VERSION "HNNBNNNYNNNNNNNNNNNNNNNNNNNNNNNNNNNNNNNNNN/4/%%%/4/'%**4NNN///"

NS_ :

BS_:

BU_: BAP_Tester BCM Gateway_Max TSGGen3_BFS TSGGen3_FS TSGGen3_HBFS TSGGen3_HFS WLC_01_CFD

BO_ 885 ESC_54: 32 Gateway_Max
 SG_ ESC_54_BZ : 8|4@1+ (1,0) [0|15] ""  BCM
 SG_ SSO_EdgeCount_Sum : 16|32@1+ (1,0) [0|4294967293] "Unit_None"  BCM
 SG_ SOK_ESC_54_Signatur : 208|48@1+ (1,0) [0|281474976710655] "Unit_None"  BCM

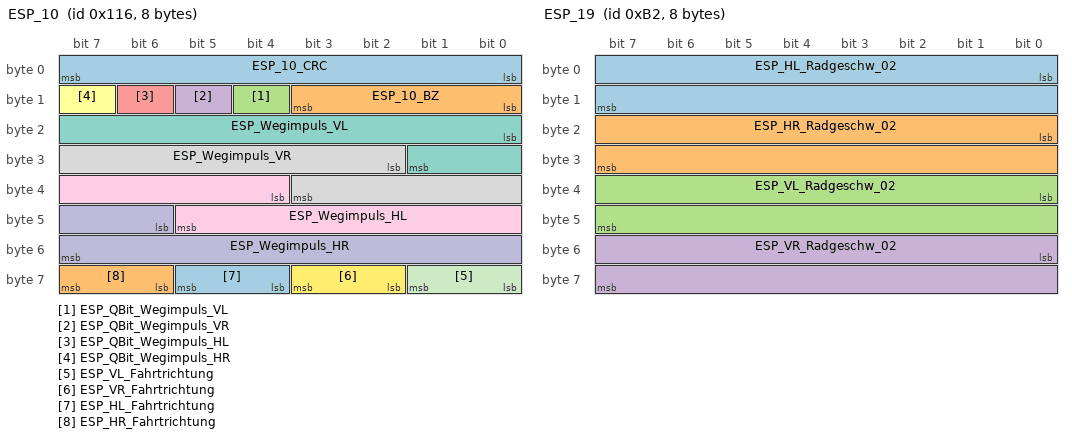
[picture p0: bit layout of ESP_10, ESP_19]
BO_ 278 ESP_10: 8 Gateway_Max
 SG_ ESP_10_CRC : 0|8@1+ (1,0) [0|255] ""  Vector__XXX
 SG_ ESP_10_BZ : 8|4@1+ (1,0) [0|15] ""  Vector__XXX
 SG_ ESP_QBit_Wegimpuls_VL : 12|1@1+ (1.0,0.0) [0.0|1] ""  Vector__XXX
 SG_ ESP_QBit_Wegimpuls_VR : 13|1@1+ (1.0,0.0) [0.0|1] ""  Vector__XXX
 SG_ ESP_QBit_Wegimpuls_HL : 14|1@1+ (1.0,0.0) [0.0|1] ""  Vector__XXX
 SG_ ESP_QBit_Wegimpuls_HR : 15|1@1+ (1.0,0.0) [0.0|1] ""  Vector__XXX
 SG_ ESP_Wegimpuls_VL : 16|10@1+ (1,0) [0|1000] ""  Vector__XXX
 SG_ ESP_Wegimpuls_VR : 26|10@1+ (1,0) [0|1000] ""  Vector__XXX
 SG_ ESP_Wegimpuls_HL : 36|10@1+ (1,0) [0|1000] ""  Vector__XXX
 SG_ ESP_Wegimpuls_HR : 46|10@1+ (1,0) [0|1000] ""  Vector__XXX
 SG_ ESP_VL_Fahrtrichtung : 56|2@1+ (1.0,0.0) [0.0|3] ""  BCM
 SG_ ESP_VR_Fahrtrichtung : 58|2@1+ (1.0,0.0) [0.0|3] ""  BCM
 SG_ ESP_HL_Fahrtrichtung : 60|2@1+ (1.0,0.0) [0.0|3] ""  BCM
 SG_ ESP_HR_Fahrtrichtung : 62|2@1+ (1.0,0.0) [0.0|3] ""  BCM

BO_ 178 ESP_19: 8 Gateway_Max
 SG_ ESP_HL_Radgeschw_02 : 0|16@1+ (0.0075,0) [0.0000|491.4900] "Unit_KiloMeterPerHour"  BCM
 SG_ ESP_HR_Radgeschw_02 : 16|16@1+ (0.0075,0) [0.0000|491.4900] "Unit_KiloMeterPerHour"  BCM
 SG_ ESP_VL_Radgeschw_02 : 32|16@1+ (0.0075,0) [0.0000|491.4900] "Unit_KiloMeterPerHour"  BCM
 SG_ ESP_VR_Radgeschw_02 : 48|16@1+ (0.0075,0) [0.0000|491.4900] "Unit_KiloMeterPerHour"  BCM

BO_ 1629 ESP_20: 8 Gateway_Max
 SG_ ESP_20_CRC : 0|8@1+ (1,0) [0|255] ""  Vector__XXX
 SG_ ESP_20_BZ : 8|4@1+ (1,0) [0|15] ""  Vector__XXX
 SG_ BR_Systemart : 12|2@1+ (1.0,0.0) [0.0|3] ""  BCM
 SG_ ESP_SpannungsAnf_02 : 14|2@1+ (1.0,0.0) [0.0|3] ""  Vector__XXX
 SG_ ESP_Zaehnezahl : 16|8@1+ (1,0) [0|255] ""  BCM
 SG_ ESP_Charisma_FahrPr : 24|4@1+ (1.0,0.0) [0.0|15] ""  Vector__XXX
 SG_ ESP_Charisma_Status : 28|2@1+ (1.0,0.0) [0.0|3] ""  Vector__XXX
 SG_ ESP_Wiederstart_Anz_01 : 30|1@1+ (1.0,0.0) [0.0|1] ""  Vector__XXX
 SG_ ESP_Wiederstart_Anz_02 : 31|1@1+ (1.0,0.0) [0.0|1] ""  Vector__XXX
 SG_ ESP_Wiederstart_Anz_03 : 32|1@1+ (1.0,0.0) [0.0|1] ""  Vector__XXX
 SG_ ESP_Wiederstart_Anz_04 : 33|1@1+ (1.0,0.0) [0.0|1] ""  Vector__XXX
 SG_ ESP_Stoppverbot_Anz_01 : 34|1@1+ (1.0,0.0) [0.0|1] ""  Vector__XXX
 SG_ ESP_Stoppverbot_Anz_02 : 35|1@1+ (1.0,0.0) [0.0|1] ""  Vector__XXX
 SG_ ESP_Stoppverbot_Anz_03 : 36|1@1+ (1.0,0.0) [0.0|1] ""  Vector__XXX
 SG_ ESP_Stoppverbot_Anz_04 : 37|1@1+ (1.0,0.0) [0.0|1] ""  Vector__XXX
 SG_ ESP_Stoppverbot_Anz_05 : 38|1@1+ (1.0,0.0) [0.0|1] ""  Vector__XXX
 SG_ ESP_Stoppverbot_Anz_06 : 39|1@1+ (1.0,0.0) [0.0|1] ""  Vector__XXX
 SG_ ESP_Stoppverbot_Anz_07 : 40|1@1+ (1.0,0.0) [0.0|1] ""  Vector__XXX
 SG_ ESP_Stoppverbot_Anz_Std : 41|1@1+ (1.0,0.0) [0.0|1] ""  Vector__XXX
 SG_ ESP_Dachrelingsensor : 42|2@1+ (1.0,0.0) [0.0|3] ""  Vector__XXX
 SG_ ESP_Stoppverbot_Anz_08 : 44|1@1+ (1.0,0.0) [0.0|1] ""  Vector__XXX
 SG_ HDC_Charisma_FahrPr : 45|4@1+ (1.0,0.0) [0.0|15] ""  Vector__XXX
 SG_ HDC_Charisma_Status : 49|2@1+ (1.0,0.0) [0.0|3] ""  Vector__XXX
 SG_ BR_QBit_Reifenumfang : 51|1@1+ (1.0,0.0) [0.0|1] ""  Vector__XXX
 SG_ BR_Reifenumfang : 52|12@1+ (1,0) [0|4095] "Unit_MilliMeter"  Vector__XXX

BO_ 253 ESP_21: 8 Gateway_Max
 SG_ ESP_21_CRC : 0|8@1+ (1,0) [0|255] ""  BCM,TSGGen3_BFS,TSGGen3_FS,TSGGen3_HBFS,TSGGen3_HFS
 SG_ ESP_21_BZ : 8|4@1+ (1,0) [0|15] ""  BCM,TSGGen3_BFS,TSGGen3_FS,TSGGen3_HBFS,TSGGen3_HFS
 SG_ BR_Eingriffsmoment : 12|10@1+ (1,-509) [-509|509] ""  BCM
 SG_ ESP_PLA_Bremseingriff : 22|1@1+ (1.0,0.0) [0.0|1] ""  BCM
 SG_ ESP_Diagnose : 23|1@1+ (1.0,0.0) [0.0|1] ""  BCM
 SG_ ESC_Reku_Freigabe : 24|1@1+ (1.0,0.0) [0.0|1] ""  BCM
 SG_ ESC_v_Signal_Qualifier_High_Low : 25|3@1+ (1.0,0.0) [0.0|7] ""  BCM
 SG_ ESP_Vorsteuerung : 28|1@1+ (1.0,0.0) [0.0|1] ""  BCM
 SG_ ESP_AWV3_Brems_aktiv : 29|1@1+ (1.0,0.0) [0.0|1] ""  BCM
 SG_ OBD_Schlechtweg : 30|1@1+ (1.0,0.0) [0.0|1] ""  BCM
 SG_ OBD_QBit_Schlechtweg : 31|1@1+ (1.0,0.0) [0.0|1] ""  BCM
 SG_ ESP_v_Signal : 32|16@1+ (0.01,0) [0.00|655.32] "Unit_KiloMeterPerHour"  BCM,TSGGen3_BFS,TSGGen3_FS,TSGGen3_HBFS,TSGGen3_HFS,WLC_01_CFD
 SG_ ASR_Tastung_passiv : 48|1@1+ (1.0,0.0) [0.0|1] ""  BCM
 SG_ ESP_Tastung_passiv : 49|1@1+ (1.0,0.0) [0.0|1] ""  BCM
 SG_ ESP_Systemstatus : 50|1@1+ (1.0,0.0) [0.0|1] ""  BCM
 SG_ ASR_Schalteingriff : 51|2@1+ (1.0,0.0) [0.0|3] ""  BCM
 SG_ ESP_Haltebestaetigung : 53|1@1+ (1.0,0.0) [0.0|1] ""  BCM
 SG_ ESP_MKB_Abbruch_Geschw : 54|1@1+ (1.0,0.0) [0.0|1] ""  BCM
 SG_ ESP_QBit_v_Signal : 55|1@1+ (1.0,0.0) [0.0|1] ""  BCM,TSGGen3_BFS,TSGGen3_FS,TSGGen3_HBFS,TSGGen3_HFS,WLC_01_CFD
 SG_ ABS_Bremsung : 56|1@1+ (1.0,0.0) [0.0|1] ""  BCM
 SG_ ASR_Anf : 57|1@1+ (1.0,0.0) [0.0|1] ""  BCM
 SG_ MSR_Anf : 58|1@1+ (1.0,0.0) [0.0|1] ""  BCM
 SG_ EBV_Eingriff : 59|1@1+ (1.0,0.0) [0.0|1] ""  BCM
 SG_ EDS_Eingriff : 60|1@1+ (1.0,0.0) [0.0|1] ""  BCM
 SG_ ESP_Eingriff : 61|1@1+ (1.0,0.0) [0.0|1] ""  BCM
 SG_ ESP_ASP : 62|1@1+ (1.0,0.0) [0.0|1] ""  BCM
 SG_ ESP_Anhaltevorgang_ACC_aktiv : 63|1@1+ (1.0,0.0) [0.0|1] ""  BCM

BO_ 795 ESP_24: 8 Gateway_Max
 SG_ ESP_24_CRC : 0|8@1+ (1,0) [0|255] ""  Vector__XXX
 SG_ ESP_24_BZ : 8|4@1+ (1,0) [0|15] ""  Vector__XXX
 SG_ ESP_Lampe : 12|1@1+ (1.0,0.0) [0.0|1] ""  Vector__XXX
 SG_ ABS_Lampe : 13|1@1+ (1.0,0.0) [0.0|1] ""  Vector__XXX
 SG_ BK_Lampe_02 : 14|2@1+ (1.0,0.0) [0.0|3] ""  Vector__XXX
 SG_ TC_Lampe : 16|1@1+ (1.0,0.0) [0.0|1] ""  Vector__XXX
 SG_ ESP_m_Raddrehz : 17|15@1+ (0.002,0) [0.000|65.278] "Unit_Hertz"  BCM
 SG_ ESP_Textanzeigen_03 : 32|5@1+ (1.0,0.0) [0.0|31] ""  Vector__XXX
 SG_ ESP_Meldungen : 37|3@1+ (1.0,0.0) [0.0|7] ""  Vector__XXX
 SG_ ESP_Wegimp_VA : 40|11@1+ (1,0) [0|2047] ""  BCM
 SG_ ESP_Fehlerstatus_Wegimp : 51|1@1+ (1.0,0.0) [0.0|1] ""  Vector__XXX
 SG_ ESP_Wegimp_Ueberlauf : 52|1@1+ (1.0,0.0) [0.0|1] ""  BCM
 SG_ ESP_QBit_Wegimp_VA : 53|1@1+ (1.0,0.0) [0.0|1] ""  Vector__XXX
 SG_ ESP_HDC_FktLampe : 54|1@1+ (1.0,0.0) [0.0|1] ""  Vector__XXX
 SG_ ESP_Off_Lampe : 55|1@1+ (1.0,0.0) [0.0|1] ""  Vector__XXX
 SG_ ESP_HDC_Regelgeschw : 56|7@1+ (0.32,0) [0.32|39.68] "Unit_KiloMeterPerHour"  Vector__XXX
 SG_ ESP_BKV_Warnung : 63|1@1+ (1.0,0.0) [0.0|1] ""  Vector__XXX

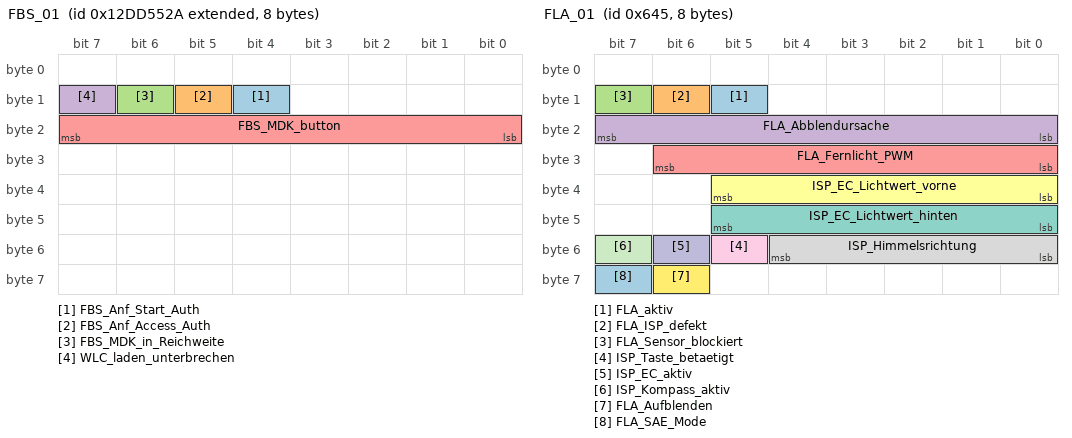
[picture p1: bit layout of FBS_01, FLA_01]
BO_ 2463978794 FBS_01: 8 BCM
 SG_ FBS_Anf_Start_Auth : 12|1@1+ (1.0,0.0) [0.0|1] ""  Gateway_Max,WLC_01_CFD
 SG_ FBS_Anf_Access_Auth : 13|1@1+ (1.0,0.0) [0.0|1] ""  Gateway_Max
 SG_ FBS_MDK_in_Reichweite : 14|1@1+ (1.0,0.0) [0.0|1] ""  Gateway_Max
 SG_ WLC_laden_unterbrechen : 15|1@1+ (1.0,0.0) [0.0|1] ""  Gateway_Max,WLC_01_CFD
 SG_ FBS_MDK_button : 16|8@1+ (1.0,0.0) [0.0|255] ""  Gateway_Max

BO_ 2527679800 FBS_MKGO_01: 64 BCM
 SG_ FBS_MKGO_01 : 0|512@1+ (1.0,0.0) [0.0|13407807929942597099574024998205846127479365820592393377723561443721764030073546976801874298166903427690031858186486050853753882811946569946433649006084095] ""  WLC_01_CFD

BO_ 2527679801 FBS_MKGO_02: 64 BCM
 SG_ FBS_MKGO_02 : 0|512@1+ (1.0,0.0) [0.0|13407807929942597099574024998205846127479365820592393377723561443721764030073546976801874298166903427690031858186486050853753882811946569946433649006084095] ""  WLC_01_CFD

BO_ 2527679802 FBS_MKGO_03: 64 BCM
 SG_ FBS_MKGO_03 : 0|512@1+ (1.0,0.0) [0.0|13407807929942597099574024998205846127479365820592393377723561443721764030073546976801874298166903427690031858186486050853753882811946569946433649006084095] ""  WLC_01_CFD

BO_ 2527679803 FBS_MKGO_04: 64 BCM
 SG_ FBS_MKGO_04 : 0|512@1+ (1.0,0.0) [0.0|13407807929942597099574024998205846127479365820592393377723561443721764030073546976801874298166903427690031858186486050853753882811946569946433649006084095] ""  WLC_01_CFD

BO_ 2527679804 FBS_MKGO_05: 64 BCM
 SG_ FBS_MKGO_05 : 0|512@1+ (1.0,0.0) [0.0|13407807929942597099574024998205846127479365820592393377723561443721764030073546976801874298166903427690031858186486050853753882811946569946433649006084095] ""  WLC_01_CFD

BO_ 1605 FLA_01: 8 Gateway_Max
 SG_ FLA_aktiv : 13|1@1+ (1.0,0.0) [0.0|1] ""  BCM
 SG_ FLA_ISP_defekt : 14|1@1+ (1.0,0.0) [0.0|1] ""  BCM
 SG_ FLA_Sensor_blockiert : 15|1@1+ (1.0,0.0) [0.0|1] ""  BCM
 SG_ FLA_Abblendursache : 16|8@1+ (1.0,0.0) [0.0|255] ""  Vector__XXX
 SG_ FLA_Fernlicht_PWM : 24|7@1+ (1,0) [0|100] "Unit_PerCent"  BCM
 SG_ ISP_EC_Lichtwert_vorne : 32|6@1+ (1,0) [0|61] "Unit_None"  Vector__XXX
 SG_ ISP_EC_Lichtwert_hinten : 40|6@1+ (1,0) [0|61] "Unit_None"  Vector__XXX
 SG_ ISP_Himmelsrichtung : 48|5@1+ (12,0) [0|348] "Unit_DegreOfArc"  Vector__XXX
 SG_ ISP_Taste_betaetigt : 53|1@1+ (1.0,0.0) [0.0|1] ""  Vector__XXX
 SG_ ISP_EC_aktiv : 54|1@1+ (1.0,0.0) [0.0|1] ""  Vector__XXX
 SG_ ISP_Kompass_aktiv : 55|1@1+ (1.0,0.0) [0.0|1] ""  Vector__XXX
 SG_ FLA_Aufblenden : 62|1@1+ (1.0,0.0) [0.0|1] ""  BCM
 SG_ FLA_SAE_Mode : 63|1@1+ (1.0,0.0) [0.0|1] ""  BCM

BO_ 2589283684 FoD_01: 8 Gateway_Max
 SG_ GRA_FoD_Status : 58|2@1+ (1.0,0.0) [0.0|3] ""  Vector__XXX
 SG_ FoD_Transmission_Info : 60|2@1+ (1.0,0.0) [0.0|3] ""  Vector__XXX

BO_ 2549875470 FoD_BCM1_Req: 8 Gateway_Max
 SG_ FoD_BCM1_Req_Data : 0|64@1+ (1.0,0.0) [0.0|18446744073709551615] ""  BCM

BO_ 2550006542 FoD_BCM1_Resp: 8 BCM
 SG_ FoD_BCM1_Resp_Data : 0|64@1+ (1.0,0.0) [0.0|18446744073709551615] ""  Gateway_Max

BO_ 986 Gateway_71: 8 Gateway_Max
 SG_ ESP_05_alt : 0|1@1+ (1.0,0.0) [0.0|1] ""  BCM
 SG_ EPB_01_alt : 1|1@1+ (1.0,0.0) [0.0|1] ""  BCM
 SG_ ESP_21_alt : 2|1@1+ (1.0,0.0) [0.0|1] ""  BCM
 SG_ LWI_01_alt : 3|1@1+ (1.0,0.0) [0.0|1] ""  BCM
 SG_ Parkhilfe_01_alt : 4|1@1+ (1.0,0.0) [0.0|1] ""  BCM
 SG_ Kamera_Status_alt : 5|1@1+ (1.0,0.0) [0.0|1] ""  BCM
 SG_ ESP_HDC_Standby : 6|1@1+ (1.0,0.0) [0.0|1] ""  BCM
 SG_ ECD_Bremslicht : 8|1@1+ (1.0,0.0) [0.0|1] ""  BCM
 SG_ EPB_Status : 9|2@1+ (1.0,0.0) [0.0|3] ""  BCM
 SG_ EPB_QBit_Pedalweg_Kuppl : 11|1@1+ (1.0,0.0) [0.0|1] ""  BCM
 SG_ ESP_QBit_v_Signal : 12|1@1+ (1.0,0.0) [0.0|1] ""  BCM
 SG_ ABS_Bremsung : 13|1@1+ (1.0,0.0) [0.0|1] ""  BCM
 SG_ ESP_Eingriff : 14|1@1+ (1.0,0.0) [0.0|1] ""  BCM
 SG_ Kamera_FSH_aktiv : 15|1@1+ (1.0,0.0) [0.0|1] ""  BCM
 SG_ EPB_Pedalweg_Kuppl : 16|8@1+ (0.4,0) [8.0|92.0] "Unit_PerCent"  BCM
 SG_ ESP_v_Signal : 24|16@1+ (0.01,0) [0.00|655.32] "Unit_KiloMeterPerHour"  BCM
 SG_ LWI_QBit_Lenkradwinkel : 40|1@1+ (1.0,0.0) [0.0|1] ""  BCM
 SG_ LWI_Sensorstatus : 41|1@1+ (1.0,0.0) [0.0|1] ""  BCM
 SG_ LWI_VZ_Lenkradwinkel : 42|1@1+ (1.0,0.0) [0.0|1] ""  BCM
 SG_ LWI_Lenkradwinkel : 43|13@1+ (0.1,0) [0.0|800.0] "Unit_DegreOfArc"  BCM
 SG_ PH_Anf_Audioabsenkung : 56|1@1+ (1.0,0.0) [0.0|1] ""  BCM
 SG_ PH_Systemzustand : 57|3@1+ (1.0,0.0) [0.0|7] ""  BCM
 SG_ PH_Taster : 60|2@1+ (1.0,0.0) [0.0|3] ""  BCM
 SG_ ESP_MKB_Abbruch_Geschw : 62|1@1+ (1.0,0.0) [0.0|1] ""  BCM
 SG_ PLA_Anf_Aufschaltung_RVC : 63|1@1+ (1.0,0.0) [0.0|1] ""  BCM

BO_ 988 Gateway_73: 8 Gateway_Max
 SG_ Motor_12_alt : 0|1@1+ (1.0,0.0) [0.0|1] ""  BCM
 SG_ ESP_07_alt : 1|1@1+ (1.0,0.0) [0.0|1] ""  BCM
 SG_ Getriebe_11_alt : 2|1@1+ (1.0,0.0) [0.0|1] ""  BCM
 SG_ Getriebe_13_alt : 3|1@1+ (1.0,0.0) [0.0|1] ""  BCM
 SG_ Getriebe_17_alt : 4|1@1+ (1.0,0.0) [0.0|1] ""  BCM
 SG_ TSK_06_alt : 5|1@1+ (1.0,0.0) [0.0|1] ""  BCM
 SG_ Getriebe_14_alt : 6|1@1+ (1.0,0.0) [0.0|1] ""  BCM
 SG_ ESP_50_alt : 7|1@1+ (1.0,0.0) [0.0|1] ""  BCM
 SG_ MO_QBit_Drehzahl_01 : 8|1@1+ (1.0,0.0) [0.0|1] ""  BCM
 SG_ MKE_Texte : 9|2@1+ (1.0,0.0) [0.0|3] ""  BCM
 SG_ MKE_Stufe : 11|3@1+ (1.0,0.0) [0.0|7] ""  BCM
 SG_ TSK_Hauptschalter_GRA_ACC : 14|2@1+ (1.0,0.0) [0.0|3] ""  BCM
 SG_ MO_Drehzahl_01 : 16|16@1+ (0.25,0) [0.00|16383.00] "Unit_MinutInver"  BCM
 SG_ TSK_Status : 32|3@1+ (1.0,0.0) [0.0|7] ""  BCM
 SG_ EPB_Schalterposition : 35|2@1+ (1.0,0.0) [0.0|3] ""  BCM
 SG_ GE_LaunchControl : 37|1@1+ (1.0,0.0) [0.0|1] ""  BCM
 SG_ GE_Fahrstufe : 40|4@1+ (1.0,0.0) [0.0|15] ""  BCM
 SG_ GE_Ursache_Fahrstufe_N : 44|1@1+ (1.0,0.0) [0.0|1] ""  BCM
 SG_ GE_Notlauf : 45|1@1+ (1.0,0.0) [0.0|1] ""  BCM
 SG_ ESP_Rollenmodus_Deaktivieren : 46|1@1+ (1.0,0.0) [0.0|1] ""  BCM
 SG_ GE_Freilauf_Status : 47|3@1+ (1.0,0.0) [0.0|7] ""  BCM
 SG_ GE_Sperr_Info_WFS : 50|1@1+ (1.0,0.0) [0.0|1] ""  BCM
 SG_ TSK_Limiter_ausgewaehlt : 51|1@1+ (1.0,0.0) [0.0|1] ""  BCM
 SG_ GE_Veto_Rollfaehigkeit : 52|1@1+ (1.0,0.0) [0.0|1] ""  BCM
 SG_ EPB_Status_02 : 53|3@1+ (1.0,0.0) [0.0|7] ""  BCM
 SG_ ACC_Status_ACC : 56|3@1+ (1.0,0.0) [0.0|7] ""  BCM
 SG_ ACC_18_alt : 59|1@1+ (1.0,0.0) [0.0|1] ""  BCM
 SG_ Bel_DiETa_Mode2 : 60|2@1+ (1.0,0.0) [0.0|3] ""  BCM

BO_ 1002 Gateway_77: 8 Gateway_Max
 SG_ ESP_05_alt : 0|1@1+ (1.0,0.0) [0.0|1] ""  BCM
 SG_ Getriebe_14_alt : 1|1@1+ (1.0,0.0) [0.0|1] ""  BCM
 SG_ Motor_11_alt : 2|1@1+ (1.0,0.0) [0.0|1] ""  BCM
 SG_ Motor_20_alt : 3|1@1+ (1.0,0.0) [0.0|1] ""  BCM
 SG_ EBKV_03_alt : 4|1@1+ (1.0,0.0) [0.0|1] ""  BCM
 SG_ AWV_03_alt : 5|1@1+ (1.0,0.0) [0.0|1] ""  BCM
 SG_ AWV_Verz_Freigabe : 6|1@1+ (1.0,0.0) [0.0|1] ""  BCM
 SG_ AWV_Verz_Anf : 7|10@1+ (0.024,-20.016) [-20.016|4.512] "Unit_MeterPerSeconSquar"  BCM
 SG_ Bel_DiETa_Mode : 17|2@1+ (1.0,0.0) [0.0|3] ""  BCM
 SG_ PaCo_DiETa_LED : 19|2@1+ (1.0,0.0) [0.0|3] ""  BCM
 SG_ RTM_Warnstatus : 21|2@1+ (1.0,0.0) [0.0|3] ""  BCM
 SG_ EBKV_Fahrer_bremst : 23|1@1+ (1.0,0.0) [0.0|1] ""  BCM
 SG_ AWV_Zielobjekttyp : 24|4@1+ (1.0,0.0) [0.0|15] ""  BCM
 SG_ ESP_Bremsdruck : 28|10@1+ (0.3,-30) [-30.0|276.6] "Unit_Bar"  BCM
 SG_ MO_Mom_Ist_Summe : 38|10@1+ (1,-509) [-509|509] ""  BCM
 SG_ MO_Fahrpedalrohwert_01 : 48|8@1+ (0.4,0) [0.0|101.6] "Unit_PerCent"  BCM
 SG_ GE_Sumpftemperatur : 56|8@1+ (1,-58) [-58|196] "Unit_DegreCelsi"  BCM

BO_ 1003 Gateway_78: 8 Gateway_Max
 SG_ LH_EPS_02_alt : 0|1@1+ (1.0,0.0) [0.0|1] ""  BCM
 SG_ LIN_2_alt : 1|1@1+ (1.0,0.0) [0.0|1] ""  BCM
 SG_ Parkhilfe_01_alt : 2|1@1+ (1.0,0.0) [0.0|1] ""  BCM
 SG_ Motor_20_alt : 3|1@1+ (1.0,0.0) [0.0|1] ""  BCM
 SG_ LR_HZG_01_alt : 4|1@1+ (1.0,0.0) [0.0|1] ""  BCM
 SG_ Areaview_01_alt : 5|1@1+ (1.0,0.0) [0.0|1] ""  BCM
 SG_ EBKV_03_alt : 6|1@1+ (1.0,0.0) [0.0|1] ""  BCM
 SG_ ESP_50_alt : 7|1@1+ (1.0,0.0) [0.0|1] ""  BCM
 SG_ EPS_Lastinfo : 8|8@1+ (1,0) [0|253] "Unit_Amper"  BCM
 SG_ EFF_Verbrauch_STH : 16|7@1+ (0.01,0) [0.00|1.26] "Unit_LiterPerHour"  BCM
 SG_ LR_HZG_Taster_on_off : 23|1@1+ (1.0,0.0) [0.0|1] ""  BCM
 SG_ LR_HZG_Temp_Sensor : 24|8@1+ (1,-50) [-50|104] "Unit_DegreCelsi"  BCM
 SG_ MFL_Signalhorn : 32|1@1+ (1.0,0.0) [0.0|1] ""  BCM
 SG_ EBKV_Fahrer_bremst : 33|1@1+ (1.0,0.0) [0.0|1] ""  BCM
 SG_ PH_Stoermeldung : 34|4@1+ (1.0,0.0) [0.0|15] ""  BCM
 SG_ MO_temporaere_Fahrerabwesenheit : 38|1@1+ (1.0,0.0) [0.0|1] ""  BCM
 SG_ AV_Umfeldbeleuchtung_Anf : 39|1@1+ (1.0,0.0) [0.0|1] ""  BCM
 SG_ MO_Fahrpedalrohwert_01 : 40|8@1+ (0.4,0) [0.0|101.6] "Unit_PerCent"  BCM
 SG_ LR_HZG_Konfiguration : 48|3@1+ (1.0,0.0) [0.0|7] ""  BCM
 SG_ EBKV_QBit_Fahrer_bremst : 51|1@1+ (1.0,0.0) [0.0|1] ""  BCM
 SG_ MO_QBit_Fahrpedalwerte_01 : 52|1@1+ (1.0,0.0) [0.0|1] ""  BCM
 SG_ ESP_QBit_Bremsdruck : 53|1@1+ (1.0,0.0) [0.0|1] ""  BCM
 SG_ ESP_Bremsdruck : 54|10@1+ (0.3,-30) [-30.0|276.6] "Unit_Bar"  BCM

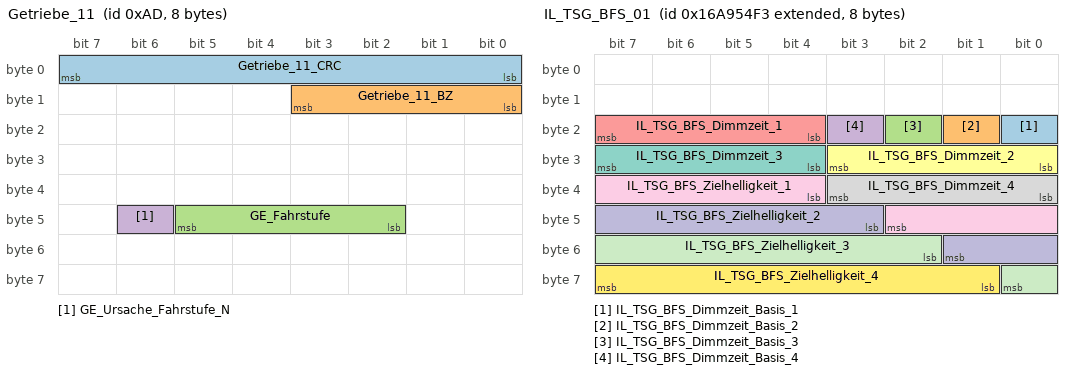
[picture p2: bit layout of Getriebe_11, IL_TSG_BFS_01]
BO_ 173 Getriebe_11: 8 Gateway_Max
 SG_ Getriebe_11_CRC : 0|8@1+ (1,0) [0|255] ""  BCM
 SG_ Getriebe_11_BZ : 8|4@1+ (1,0) [0|15] ""  BCM
 SG_ GE_Fahrstufe : 42|4@1+ (1.0,0.0) [0.0|15] ""  BCM
 SG_ GE_Ursache_Fahrstufe_N : 46|1@1+ (1.0,0.0) [0.0|1] ""  Vector__XXX

BO_ 299 GRA_ACC_01: 8 BCM
 SG_ GRA_ACC_01_CRC : 0|8@1+ (1,0) [0|255] ""  BCM,Gateway_Max
 SG_ GRA_ACC_01_BZ : 8|4@1+ (1,0) [0|15] ""  BCM,Gateway_Max
 SG_ GRA_Hauptschalter : 12|1@1+ (1.0,0.0) [0.0|1] ""  BCM,Gateway_Max
 SG_ GRA_Abbrechen : 13|1@1+ (1.0,0.0) [0.0|1] ""  BCM,Gateway_Max
 SG_ GRA_Typ_Hauptschalter : 14|1@1+ (1.0,0.0) [0.0|1] ""  BCM,Gateway_Max
 SG_ GRA_Limiter : 15|1@1+ (1.0,0.0) [0.0|1] ""  BCM,Gateway_Max
 SG_ GRA_Tip_Setzen : 16|1@1+ (1.0,0.0) [0.0|1] ""  BCM,Gateway_Max
 SG_ GRA_Tip_Hoch : 17|1@1+ (1.0,0.0) [0.0|1] ""  BCM,Gateway_Max
 SG_ GRA_Tip_Runter : 18|1@1+ (1.0,0.0) [0.0|1] ""  BCM,Gateway_Max
 SG_ GRA_Tip_Wiederaufnahme : 19|1@1+ (1.0,0.0) [0.0|1] ""  BCM,Gateway_Max
 SG_ GRA_Verstellung_Zeitluecke : 20|2@1+ (1.0,0.0) [0.0|3] ""  BCM,Gateway_Max
 SG_ GRA_Codierung : 22|2@1+ (1.0,0.0) [0.0|3] ""  BCM,Gateway_Max
 SG_ GRA_Fehler : 24|1@1+ (1.0,0.0) [0.0|1] ""  BCM,Gateway_Max
 SG_ GRA_LIM_Taste_verfuegbar : 25|1@1+ (1.0,0.0) [0.0|1] ""  BCM,Gateway_Max
 SG_ GRA_Tip_Stufe_2 : 26|1@1+ (1.0,0.0) [0.0|1] ""  BCM,Gateway_Max
 SG_ GRA_Typ_Bedienteil : 27|3@1+ (1.0,0.0) [0.0|7] ""  BCM,Gateway_Max
 SG_ GRA_TravelAssist : 30|1@1+ (1.0,0.0) [0.0|1] ""  BCM,Gateway_Max
 SG_ GRA_PIT_Limiter : 31|1@1+ (1.0,0.0) [0.0|1] ""  BCM,Gateway_Max
 SG_ GRA_reserveByte5 : 32|8@1+ (1.0,0.0) [0.0|255] ""  BCM,Gateway_Max
 SG_ GRA_reserveByte6 : 40|8@1+ (1.0,0.0) [0.0|255] ""  BCM,Gateway_Max
 SG_ GRA_reserveByte7 : 48|8@1+ (1.0,0.0) [0.0|255] ""  BCM,Gateway_Max
 SG_ GRA_reserveByte8 : 56|8@1+ (1.0,0.0) [0.0|255] ""  BCM,Gateway_Max

BO_ 18 GSG_WFS_Anfrage: 8 Gateway_Max
 SG_ WFS_GSG_RND : 0|32@1+ (1.0,0.0) [0.0|4294967295] ""  BCM
 SG_ WFS_GSG_CRC : 32|32@1+ (1.0,0.0) [0.0|4294967295] ""  BCM

BO_ 1410 HDSG_01: 4 Gateway_Max
 SG_ HD_Endstellung_oben : 0|1@1+ (1.0,0.0) [0.0|1] ""  Vector__XXX
 SG_ HD_Endstellung_unten : 1|1@1+ (1.0,0.0) [0.0|1] ""  Vector__XXX
 SG_ HD_Bewegung_auf : 2|1@1+ (1.0,0.0) [0.0|1] ""  BCM
 SG_ HD_Bewegung_zu : 3|1@1+ (1.0,0.0) [0.0|1] ""  BCM
 SG_ HD_Innentaster_betaetigt : 4|1@1+ (1.0,0.0) [0.0|1] ""  BCM
 SG_ HD_Kupp_Ma_aktiv : 5|1@1+ (1.0,0.0) [0.0|1] ""  Vector__XXX
 SG_ HD_Kupp_Sl_aktiv : 6|1@1+ (1.0,0.0) [0.0|1] ""  Vector__XXX
 SG_ HD_UeKB_erkannt : 7|1@1+ (1.0,0.0) [0.0|1] ""  Vector__XXX
 SG_ HD_Position : 8|8@1+ (1,0) [0|100] "Unit_PerCent"  BCM
 SG_ HD_SG_MA_KD_Fehler : 16|1@1+ (1.0,0.0) [0.0|1] ""  Vector__XXX
 SG_ HD_SG_SL_KD_Fehler : 17|1@1+ (1.0,0.0) [0.0|1] ""  Vector__XXX
 SG_ HD_Taster_defekt : 18|1@1+ (1.0,0.0) [0.0|1] ""  Vector__XXX
 SG_ HD_Spannung : 19|1@1+ (1.0,0.0) [0.0|1] ""  Vector__XXX
 SG_ HD_Rueckmeld_prog : 20|1@1+ (1.0,0.0) [0.0|1] ""  BCM
 SG_ HD_Verriegelungstaster_betaetigt : 21|1@1+ (1.0,0.0) [0.0|1] ""  BCM
 SG_ HD_Verr_Taster_betaetigt_inv : 22|1@1+ (1.0,0.0) [0.0|1] ""  BCM
 SG_ HD_ZZH_Schalter_S3 : 23|1@1+ (1.0,0.0) [0.0|1] ""  BCM
 SG_ HDSG_Anf_Umluftklappe : 31|1@1+ (1.0,0.0) [0.0|1] ""  Vector__XXX

BO_ 588 Heckradar_01: 16 Gateway_Max
 SG_ SWA_LED_Hell_BFS : 12|7@1+ (1,0) [0|100] "Unit_PerCent"  TSGGen3_BFS,TSGGen3_FS,TSGGen3_HBFS,TSGGen3_HFS
 SG_ SWA_LED_Hell_FS : 19|7@1+ (1,0) [0|100] "Unit_PerCent"  TSGGen3_BFS,TSGGen3_FS,TSGGen3_HBFS,TSGGen3_HFS
 SG_ SWA_LED_Ausgabemodus_BFS : 26|3@1+ (1.0,0.0) [0.0|7] ""  TSGGen3_BFS
 SG_ SWA_LED_Ausgabemodus_FS : 29|3@1+ (1.0,0.0) [0.0|7] ""  TSGGen3_FS
 SG_ SWA_Status : 32|2@1+ (1.0,0.0) [0.0|3] ""  Vector__XXX
 SG_ ASW_Ton_Richtung_VL : 34|1@1+ (1.0,0.0) [0.0|1] ""  Vector__XXX
 SG_ ASW_Ton_Richtung_VR : 35|1@1+ (1.0,0.0) [0.0|1] ""  Vector__XXX
 SG_ ASW_Ton_Richtung_HL : 36|1@1+ (1.0,0.0) [0.0|1] ""  Vector__XXX
 SG_ ASW_Ton_Richtung_HR : 37|1@1+ (1.0,0.0) [0.0|1] ""  Vector__XXX
 SG_ SWA_Status_System : 38|2@1+ (1.0,0.0) [0.0|3] ""  Vector__XXX
 SG_ SWA_Brightness_Mode_FPM : 40|4@1+ (1.0,0.0) [0.0|15] ""  Vector__XXX
 SG_ SWA_Status_KuFu : 44|2@1+ (1.0,0.0) [0.0|3] ""  Vector__XXX
 SG_ SWA_Infostufe_Assist_li : 46|1@1+ (1.0,0.0) [0.0|1] ""  Vector__XXX
 SG_ SWA_Infostufe_Assist_re : 47|1@1+ (1.0,0.0) [0.0|1] ""  Vector__XXX
 SG_ SWA_Warnstufe_Assist_li : 48|1@1+ (1.0,0.0) [0.0|1] ""  Vector__XXX
 SG_ SWA_Warnstufe_Assist_re : 49|1@1+ (1.0,0.0) [0.0|1] ""  Vector__XXX
 SG_ SWA_Modus_System : 50|3@1+ (1.0,0.0) [0.0|7] ""  Vector__XXX
 SG_ SWA_Kombiausgabe : 53|3@1+ (1.0,0.0) [0.0|7] ""  Vector__XXX
 SG_ ASW_Kombiausgabe : 56|3@1+ (1.0,0.0) [0.0|7] ""  Vector__XXX
 SG_ SWA_Kombiwarnung : 59|1@1+ (1.0,0.0) [0.0|1] ""  Vector__XXX
 SG_ ASW_Ausgabemodus_HBFS : 64|3@1+ (1.0,0.0) [0.0|7] ""  TSGGen3_BFS,TSGGen3_HBFS
 SG_ ASW_Ausgabemodus_HFS : 67|3@1+ (1.0,0.0) [0.0|7] ""  TSGGen3_FS,TSGGen3_HFS
 SG_ ASW_Akustik_Einstellung : 70|1@1+ (1.0,0.0) [0.0|1] ""  TSGGen3_BFS,TSGGen3_FS,TSGGen3_HBFS,TSGGen3_HFS
 SG_ SWA_Anzeigen : 76|4@1+ (1.0,0.0) [0.0|15] ""  Vector__XXX
 SG_ SWA_Blindheit_erkannt : 80|1@1+ (1.0,0.0) [0.0|1] ""  Vector__XXX
 SG_ SWA_rel_Nichtverf : 81|1@1+ (1.0,0.0) [0.0|1] ""  Vector__XXX
 SG_ SWA_rel_Fehler : 82|1@1+ (1.0,0.0) [0.0|1] ""  Vector__XXX
 SG_ SWA_Sta_aktiv : 83|1@1+ (1.0,0.0) [0.0|1] ""  Vector__XXX
 SG_ SWA_Sta_passiv : 84|1@1+ (1.0,0.0) [0.0|1] ""  Vector__XXX
 SG_ SWA_FT_RueckLED : 85|1@1+ (1.0,0.0) [0.0|1] ""  Vector__XXX
 SG_ ASW_Status : 86|2@1+ (1.0,0.0) [0.0|3] ""  TSGGen3_BFS,TSGGen3_FS,TSGGen3_HBFS,TSGGen3_HFS
 SG_ SWA_Standziele_li : 88|1@1+ (1.0,0.0) [0.0|1] ""  Vector__XXX
 SG_ ASW_Ausgabemodus_BFS : 89|3@1+ (1.0,0.0) [0.0|7] ""  TSGGen3_BFS
 SG_ ASW_Warnung_FS : 92|1@1+ (1.0,0.0) [0.0|1] ""  BCM,TSGGen3_BFS,TSGGen3_FS,TSGGen3_HBFS,TSGGen3_HFS
 SG_ ASW_Warnung_BFS : 93|1@1+ (1.0,0.0) [0.0|1] ""  BCM,TSGGen3_BFS,TSGGen3_FS,TSGGen3_HBFS,TSGGen3_HFS
 SG_ ASW_Kombitexte : 94|3@1+ (1.0,0.0) [0.0|7] ""  Vector__XXX
 SG_ ASW_Modus : 98|3@1+ (1.0,0.0) [0.0|7] ""  Vector__XXX
 SG_ SWA_Modus : 101|3@1+ (1.0,0.0) [0.0|7] ""  Vector__XXX
 SG_ SWA_Standziele_re : 104|1@1+ (1.0,0.0) [0.0|1] ""  Vector__XXX
 SG_ ASW_Ausgabemodus_FS : 105|3@1+ (1.0,0.0) [0.0|7] ""  TSGGen3_FS
 SG_ HRE_Anzeigetexte : 108|4@1+ (1.0,0.0) [0.0|15] ""  Vector__XXX
 SG_ SWA_Gischtzaehler : 112|7@1+ (1,0) [0|100] "Unit_PerCent"  Vector__XXX
 SG_ SWA_Blindheitsverdacht : 119|1@1+ (1.0,0.0) [0.0|1] ""  Vector__XXX
 SG_ Heckradar_Kombitexte : 120|5@1+ (1.0,0.0) [0.0|31] ""  Vector__XXX
 SG_ RCTA_Kombitexte : 125|3@1+ (1.0,0.0) [0.0|7] ""  Vector__XXX

BO_ 1016 HLR_02: 8 Gateway_Max
 SG_ HLR_FlHz_Freigabe_Ruhesitz : 14|2@1+ (1.0,0.0) [0.0|3] ""  Vector__XXX
 SG_ HLR_FlHz_Freigabe_VR : 16|2@1+ (1.0,0.0) [0.0|3] ""  Vector__XXX
 SG_ HLR_FlHz_Freigabe_VL : 18|2@1+ (1.0,0.0) [0.0|3] ""  Vector__XXX
 SG_ HLR_FlHz_Freigabe_HR : 20|2@1+ (1.0,0.0) [0.0|3] ""  Vector__XXX
 SG_ HLR_FlHz_Freigabe_HL : 22|2@1+ (1.0,0.0) [0.0|3] ""  Vector__XXX
 SG_ HLR_TCH_Freigabe : 24|1@1+ (1.0,0.0) [0.0|1] ""  Vector__XXX
 SG_ HLR_SIH_Freigabe_Fond : 25|1@1+ (1.0,0.0) [0.0|1] ""  Vector__XXX
 SG_ HLR_Sp_Heizung_Freigabe_BT : 26|1@1+ (1.0,0.0) [0.0|1] ""  TSGGen3_BFS
 SG_ HLR_Sp_Heizung_Freigabe_FT : 27|1@1+ (1.0,0.0) [0.0|1] ""  TSGGen3_FS
 SG_ HLR_KRH_Freigabe_VL : 28|2@1+ (1.0,0.0) [0.0|3] ""  BCM
 SG_ HLR_KRH_Freigabe_VR : 30|2@1+ (1.0,0.0) [0.0|3] ""  BCM
 SG_ HLR_SIH_Freigabe_VL : 32|2@1+ (1.0,0.0) [0.0|3] ""  Vector__XXX
 SG_ HLR_SIH_Freigabe_VR : 34|2@1+ (1.0,0.0) [0.0|3] ""  Vector__XXX
 SG_ HLR_SIH_Freigabe_HL : 36|2@1+ (1.0,0.0) [0.0|3] ""  Vector__XXX
 SG_ HLR_SIH_Freigabe_HR : 38|2@1+ (1.0,0.0) [0.0|3] ""  Vector__XXX
 SG_ HLR_SIL_Freigabe_VL : 40|2@1+ (1.0,0.0) [0.0|3] ""  Vector__XXX
 SG_ HLR_SIL_Freigabe_VR : 42|2@1+ (1.0,0.0) [0.0|3] ""  Vector__XXX
 SG_ HLR_SIL_Freigabe_HL : 44|2@1+ (1.0,0.0) [0.0|3] ""  Vector__XXX
 SG_ HLR_SIL_Freigabe_HR : 46|2@1+ (1.0,0.0) [0.0|3] ""  Vector__XXX
 SG_ HLR_FSH_Freigabe : 48|6@1+ (20,0) [20|1240] "Unit_Watt"  Vector__XXX
 SG_ HLR_HSH_Freigabe : 54|1@1+ (1.0,0.0) [0.0|1] ""  Vector__XXX
 SG_ HLR_LRH_Freigabe : 55|1@1+ (1.0,0.0) [0.0|1] ""  BCM
 SG_ HLR_PTC_linear_Freigabe : 56|6@1+ (50,0) [0|3100] "Unit_Watt"  Vector__XXX
 SG_ HLR_PTC_Freigabe : 62|2@1+ (1.0,0.0) [0.0|3] ""  Vector__XXX

BO_ 2527679731 IL_TSG_BFS_01: 8 BCM
 SG_ IL_TSG_BFS_Dimmzeit_Basis_1 : 16|1@1+ (1.0,0.0) [0.0|1] ""  TSGGen3_BFS
 SG_ IL_TSG_BFS_Dimmzeit_Basis_2 : 17|1@1+ (1.0,0.0) [0.0|1] ""  TSGGen3_BFS
 SG_ IL_TSG_BFS_Dimmzeit_Basis_3 : 18|1@1+ (1.0,0.0) [0.0|1] ""  TSGGen3_BFS
 SG_ IL_TSG_BFS_Dimmzeit_Basis_4 : 19|1@1+ (1.0,0.0) [0.0|1] ""  TSGGen3_BFS
 SG_ IL_TSG_BFS_Dimmzeit_1 : 20|4@1+ (1,0) [0|15] "Unit_None"  TSGGen3_BFS
 SG_ IL_TSG_BFS_Dimmzeit_2 : 24|4@1+ (1,0) [0|15] "Unit_None"  TSGGen3_BFS
 SG_ IL_TSG_BFS_Dimmzeit_3 : 28|4@1+ (1,0) [0|15] "Unit_None"  TSGGen3_BFS
 SG_ IL_TSG_BFS_Dimmzeit_4 : 32|4@1+ (1,0) [0|15] "Unit_None"  TSGGen3_BFS
 SG_ IL_TSG_BFS_Zielhelligkeit_1 : 36|7@1+ (1,0) [0|100] "Unit_PerCent"  TSGGen3_BFS
 SG_ IL_TSG_BFS_Zielhelligkeit_2 : 43|7@1+ (1,0) [0|100] "Unit_PerCent"  TSGGen3_BFS
 SG_ IL_TSG_BFS_Zielhelligkeit_3 : 50|7@1+ (1,0) [0|100] "Unit_PerCent"  TSGGen3_BFS
 SG_ IL_TSG_BFS_Zielhelligkeit_4 : 57|7@1+ (1,0) [0|100] "Unit_PerCent"  TSGGen3_BFS

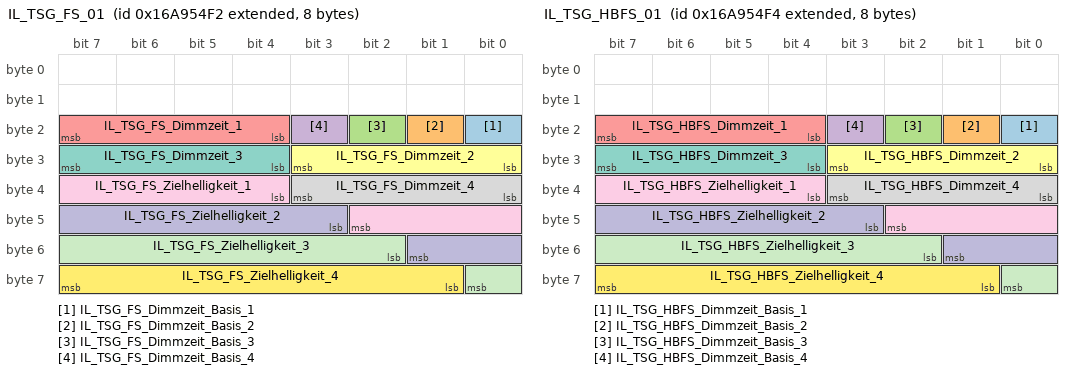
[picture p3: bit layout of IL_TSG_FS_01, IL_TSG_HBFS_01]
BO_ 2527679730 IL_TSG_FS_01: 8 BCM
 SG_ IL_TSG_FS_Dimmzeit_Basis_1 : 16|1@1+ (1.0,0.0) [0.0|1] ""  TSGGen3_FS
 SG_ IL_TSG_FS_Dimmzeit_Basis_2 : 17|1@1+ (1.0,0.0) [0.0|1] ""  TSGGen3_FS
 SG_ IL_TSG_FS_Dimmzeit_Basis_3 : 18|1@1+ (1.0,0.0) [0.0|1] ""  TSGGen3_FS
 SG_ IL_TSG_FS_Dimmzeit_Basis_4 : 19|1@1+ (1.0,0.0) [0.0|1] ""  TSGGen3_FS
 SG_ IL_TSG_FS_Dimmzeit_1 : 20|4@1+ (1,0) [0|15] "Unit_None"  TSGGen3_FS
 SG_ IL_TSG_FS_Dimmzeit_2 : 24|4@1+ (1,0) [0|15] "Unit_None"  TSGGen3_FS
 SG_ IL_TSG_FS_Dimmzeit_3 : 28|4@1+ (1,0) [0|15] "Unit_None"  TSGGen3_FS
 SG_ IL_TSG_FS_Dimmzeit_4 : 32|4@1+ (1,0) [0|15] "Unit_None"  TSGGen3_FS
 SG_ IL_TSG_FS_Zielhelligkeit_1 : 36|7@1+ (1,0) [0|100] "Unit_PerCent"  TSGGen3_FS
 SG_ IL_TSG_FS_Zielhelligkeit_2 : 43|7@1+ (1,0) [0|100] "Unit_PerCent"  TSGGen3_FS
 SG_ IL_TSG_FS_Zielhelligkeit_3 : 50|7@1+ (1,0) [0|100] "Unit_PerCent"  TSGGen3_FS
 SG_ IL_TSG_FS_Zielhelligkeit_4 : 57|7@1+ (1,0) [0|100] "Unit_PerCent"  TSGGen3_FS

BO_ 2527679732 IL_TSG_HBFS_01: 8 BCM
 SG_ IL_TSG_HBFS_Dimmzeit_Basis_1 : 16|1@1+ (1.0,0.0) [0.0|1] ""  TSGGen3_HBFS
 SG_ IL_TSG_HBFS_Dimmzeit_Basis_2 : 17|1@1+ (1.0,0.0) [0.0|1] ""  TSGGen3_HBFS
 SG_ IL_TSG_HBFS_Dimmzeit_Basis_3 : 18|1@1+ (1.0,0.0) [0.0|1] ""  TSGGen3_HBFS
 SG_ IL_TSG_HBFS_Dimmzeit_Basis_4 : 19|1@1+ (1.0,0.0) [0.0|1] ""  TSGGen3_HBFS
 SG_ IL_TSG_HBFS_Dimmzeit_1 : 20|4@1+ (1,0) [0|15] "Unit_None"  TSGGen3_HBFS
 SG_ IL_TSG_HBFS_Dimmzeit_2 : 24|4@1+ (1,0) [0|15] "Unit_None"  TSGGen3_HBFS
 SG_ IL_TSG_HBFS_Dimmzeit_3 : 28|4@1+ (1,0) [0|15] "Unit_None"  TSGGen3_HBFS
 SG_ IL_TSG_HBFS_Dimmzeit_4 : 32|4@1+ (1,0) [0|15] "Unit_None"  TSGGen3_HBFS
 SG_ IL_TSG_HBFS_Zielhelligkeit_1 : 36|7@1+ (1,0) [0|100] "Unit_PerCent"  TSGGen3_HBFS
 SG_ IL_TSG_HBFS_Zielhelligkeit_2 : 43|7@1+ (1,0) [0|100] "Unit_PerCent"  TSGGen3_HBFS
 SG_ IL_TSG_HBFS_Zielhelligkeit_3 : 50|7@1+ (1,0) [0|100] "Unit_PerCent"  TSGGen3_HBFS
 SG_ IL_TSG_HBFS_Zielhelligkeit_4 : 57|7@1+ (1,0) [0|100] "Unit_PerCent"  TSGGen3_HBFS

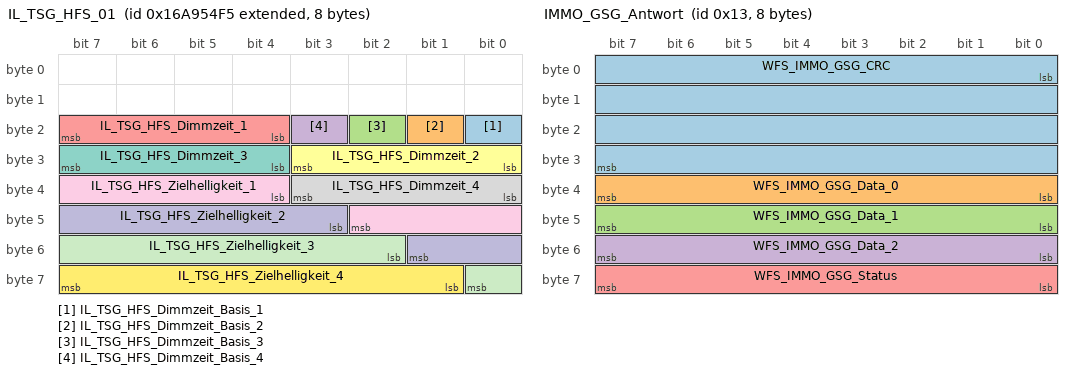
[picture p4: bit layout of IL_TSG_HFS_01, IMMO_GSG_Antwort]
BO_ 2527679733 IL_TSG_HFS_01: 8 BCM
 SG_ IL_TSG_HFS_Dimmzeit_Basis_1 : 16|1@1+ (1.0,0.0) [0.0|1] ""  TSGGen3_HFS
 SG_ IL_TSG_HFS_Dimmzeit_Basis_2 : 17|1@1+ (1.0,0.0) [0.0|1] ""  TSGGen3_HFS
 SG_ IL_TSG_HFS_Dimmzeit_Basis_3 : 18|1@1+ (1.0,0.0) [0.0|1] ""  TSGGen3_HFS
 SG_ IL_TSG_HFS_Dimmzeit_Basis_4 : 19|1@1+ (1.0,0.0) [0.0|1] ""  TSGGen3_HFS
 SG_ IL_TSG_HFS_Dimmzeit_1 : 20|4@1+ (1,0) [0|15] "Unit_None"  TSGGen3_HFS
 SG_ IL_TSG_HFS_Dimmzeit_2 : 24|4@1+ (1,0) [0|15] "Unit_None"  TSGGen3_HFS
 SG_ IL_TSG_HFS_Dimmzeit_3 : 28|4@1+ (1,0) [0|15] "Unit_None"  TSGGen3_HFS
 SG_ IL_TSG_HFS_Dimmzeit_4 : 32|4@1+ (1,0) [0|15] "Unit_None"  TSGGen3_HFS
 SG_ IL_TSG_HFS_Zielhelligkeit_1 : 36|7@1+ (1,0) [0|100] "Unit_PerCent"  TSGGen3_HFS
 SG_ IL_TSG_HFS_Zielhelligkeit_2 : 43|7@1+ (1,0) [0|100] "Unit_PerCent"  TSGGen3_HFS
 SG_ IL_TSG_HFS_Zielhelligkeit_3 : 50|7@1+ (1,0) [0|100] "Unit_PerCent"  TSGGen3_HFS
 SG_ IL_TSG_HFS_Zielhelligkeit_4 : 57|7@1+ (1,0) [0|100] "Unit_PerCent"  TSGGen3_HFS

BO_ 27 IMMO_ELV_Antwort: 8 BCM
 SG_ WFS_IMMO_ELV_CRC : 0|32@1+ (1.0,0.0) [0.0|4294967295] ""  Gateway_Max
 SG_ WFS_IMMO_ELV_RND : 32|32@1+ (1.0,0.0) [0.0|4294967295] ""  Gateway_Max

BO_ 19 IMMO_GSG_Antwort: 8 BCM
 SG_ WFS_IMMO_GSG_CRC : 0|32@1+ (1.0,0.0) [0.0|4294967295] ""  Gateway_Max
 SG_ WFS_IMMO_GSG_Data_0 : 32|8@1+ (1.0,0.0) [0.0|255] ""  Gateway_Max
 SG_ WFS_IMMO_GSG_Data_1 : 40|8@1+ (1.0,0.0) [0.0|255] ""  Gateway_Max
 SG_ WFS_IMMO_GSG_Data_2 : 48|8@1+ (1.0,0.0) [0.0|255] ""  Gateway_Max
 SG_ WFS_IMMO_GSG_Status : 56|8@1+ (1,0) [0|255] ""  Gateway_Max

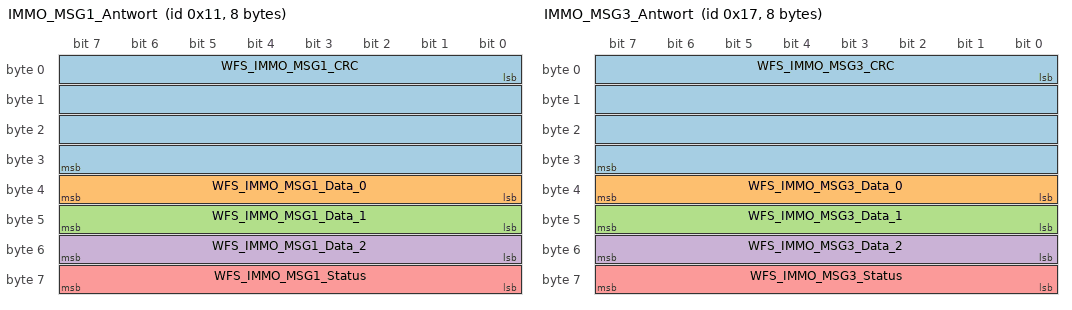
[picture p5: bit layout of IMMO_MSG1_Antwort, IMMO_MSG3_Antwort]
BO_ 17 IMMO_MSG1_Antwort: 8 BCM
 SG_ WFS_IMMO_MSG1_CRC : 0|32@1+ (1.0,0.0) [0.0|4294967295] ""  Gateway_Max
 SG_ WFS_IMMO_MSG1_Data_0 : 32|8@1+ (1.0,0.0) [0.0|255] ""  Gateway_Max
 SG_ WFS_IMMO_MSG1_Data_1 : 40|8@1+ (1.0,0.0) [0.0|255] ""  Gateway_Max
 SG_ WFS_IMMO_MSG1_Data_2 : 48|8@1+ (1.0,0.0) [0.0|255] ""  Gateway_Max
 SG_ WFS_IMMO_MSG1_Status : 56|8@1+ (1,0) [0|255] ""  Gateway_Max

BO_ 21 IMMO_MSG2_Antwort: 8 BCM
 SG_ WFS_IMMO_MSG2_CRC : 0|32@1+ (1.0,0.0) [0.0|4294967295] ""  Vector__XXX
 SG_ WFS_IMMO_MSG2_Status : 56|8@1+ (1,0) [0|255] ""  Vector__XXX

BO_ 23 IMMO_MSG3_Antwort: 8 BCM
 SG_ WFS_IMMO_MSG3_CRC : 0|32@1+ (1.0,0.0) [0.0|4294967295] ""  Gateway_Max
 SG_ WFS_IMMO_MSG3_Data_0 : 32|8@1+ (1.0,0.0) [0.0|255] ""  Gateway_Max
 SG_ WFS_IMMO_MSG3_Data_1 : 40|8@1+ (1.0,0.0) [0.0|255] ""  Gateway_Max
 SG_ WFS_IMMO_MSG3_Data_2 : 48|8@1+ (1.0,0.0) [0.0|255] ""  Gateway_Max
 SG_ WFS_IMMO_MSG3_Status : 56|8@1+ (1,0) [0|255] ""  Gateway_Max

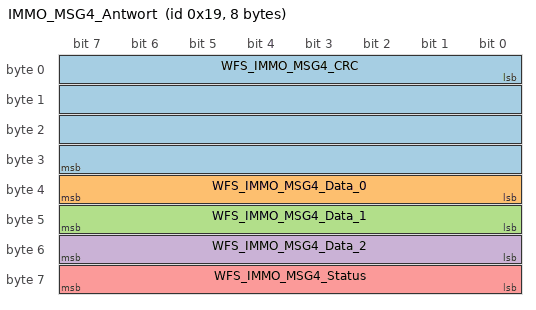
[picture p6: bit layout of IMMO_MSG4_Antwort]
BO_ 25 IMMO_MSG4_Antwort: 8 BCM
 SG_ WFS_IMMO_MSG4_CRC : 0|32@1+ (1.0,0.0) [0.0|4294967295] ""  Gateway_Max
 SG_ WFS_IMMO_MSG4_Data_0 : 32|8@1+ (1.0,0.0) [0.0|255] ""  Gateway_Max
 SG_ WFS_IMMO_MSG4_Data_1 : 40|8@1+ (1.0,0.0) [0.0|255] ""  Gateway_Max
 SG_ WFS_IMMO_MSG4_Data_2 : 48|8@1+ (1.0,0.0) [0.0|255] ""  Gateway_Max
 SG_ WFS_IMMO_MSG4_Status : 56|8@1+ (1,0) [0|255] ""  Gateway_Max

BO_ 29 IMMO_OCU_Antwort: 8 BCM
 SG_ WFS_IMMO_OCU_CRC : 0|32@1+ (1.0,0.0) [0.0|4294967295] ""  Gateway_Max
 SG_ WFS_IMMO_OCU_RND : 32|32@1+ (1.0,0.0) [0.0|4294967295] ""  Gateway_Max

BO_TX_BU_ 299 :BCM,Gateway_Max;
CM_ BO_ 1629 "neu im MQB";
CM_ BO_ 253 "Neue Momente im MQB
Struktur ab MQB mit CRC8 entstanden aus ESP_01";
CM_ BO_ 795 "neu für MQB wg. Absicherung
Entstanden aus ESP_04";
CM_ BO_ 986 "Fahrwerk, Extended -> Komfort, Infotainment";
CM_ BO_ 988 "Antrieb, Fahrwerk -> Extended, Infotainment, Komfort";
CM_ BO_ 1002 "ACAN, FCAN --> ICAN";
CM_ BO_ 1003 "Fahrwerk -> Komfort";
CM_ BO_ 1016 "Heizleistungsregelung 
MLBevo (NVEM im Gateway)";

CM_ SG_ 885 ESC_54_BZ "4bit Botschaftszähler, wird mit jeder Sendebotschaft inkrementiert";
CM_ SG_ 885 SOK_ESC_54_Signatur "Signatur im Rahmen der durch SOK geschützten Broadcast-Kommunikation

Geschützte Funktion: Wegstreckensicherheit
Geschützte Signale: SSO_EdgeCount_Sum";
CM_ SG_ 885 SSO_EdgeCount_Sum "sum of the average of the counters of the rear wheels";

CM_ SG_ 278 ESP_10_BZ "Botschaftszähler

Wird im Projekt D4 und D4Hybrid nicht verwendet!  Wird im D4 PA verwendet
Botschaft asynchron geroutet. Zählerwert kann springen.";
CM_ SG_ 278 ESP_10_CRC "Für MLB:
'Berechnung siehe Lastenheft 'Kommunikationsabsicherung für FlexRay und CAN''

Ab MQB und MLBevo:
'Berechnung siehe Lastenheft 'End-to-End Kommunikationsabsicherung''

Endwerte siehe Begleitdokument 'S-PDU Kennungsfolgen'

Wird im Projekt";
CM_ SG_ 278 ESP_HL_Fahrtrichtung "Drehrichtung Rad HL

Weiterführende Informationen im Lastenheft spezifiziert und in der entsprechenden Fachabteilung zu erfragen.

Wird im Projekt D4 und D4Hybrid nicht verwendet!  Wird im D4 PA verwendet";
CM_ SG_ 278 ESP_HR_Fahrtrichtung "Drehrichtung Rad HR

Weiterführende Informationen im Lastenheft spezifiziert und in der entsprechenden Fachabteilung zu erfragen.

Wird im Projekt D4 und D4Hybrid nicht verwendet!  Wird im D4 PA verwendet";
CM_ SG_ 278 ESP_QBit_Wegimpuls_HL "Qualifizierungsbit Wegimpulszähler HL

Wird im Projekt D4 und D4Hybrid nicht verwendet!  Wird im D4 PA verwendet";
CM_ SG_ 278 ESP_QBit_Wegimpuls_HR "Qualifizierungsbit Wegimpulszähler HR

Wird im Projekt D4 und D4Hybrid nicht verwendet!  Wird im D4 PA verwendet";
CM_ SG_ 278 ESP_QBit_Wegimpuls_VL "Qualifizierungsbit Wegimpulszähler VL

Wird im Projekt D4 und D4Hybrid nicht verwendet!  Wird im D4 PA verwendet";
CM_ SG_ 278 ESP_QBit_Wegimpuls_VR "Qualifizierungsbit Wegimpulszähler VR

Wird im Projekt D4 und D4Hybrid nicht verwendet!  Wird im D4 PA verwendet";
CM_ SG_ 278 ESP_VL_Fahrtrichtung "Drehrichtung Rad VL

Weiterführende Informationen im Lastenheft spezifiziert und in der entsprechenden Fachabteilung zu erfragen.

Wird im Projekt D4 und D4Hybrid nicht verwendet!  Wird im D4 PA verwendet";
CM_ SG_ 278 ESP_VR_Fahrtrichtung "Drehrichtung Rad VR

Weiterführende Informationen im Lastenheft spezifiziert und in der entsprechenden Fachabteilung zu erfragen.

Wird im Projekt D4 und D4Hybrid nicht verwendet!  Wird im D4 PA verwendet";
CM_ SG_ 278 ESP_Wegimpuls_HL "Wegimpulszähler HL.
Anzahl der Wegimpulse Hinterrad links (steigende und fallende Flanke)
Zähler läuft grundsätzlich vorwärts, auch bei Rückwärtsfahrt.
Nach SG-Reset ist immer, ohne Ausnahme, 1mal der Init Wert 1021 zu senden.

Wird im Projekt D4 und";
CM_ SG_ 278 ESP_Wegimpuls_HR "Wegimpulszähler HR.
Anzahl der Wegimpulse Hinterrad rechts (steigende und fallende Flanke)
Zähler läuft grundsätzlich vorwärts, auch bei Rückwärtsfahrt.
Nach SG-Reset ist immer, ohne Ausnahme, 1mal der Init Wert 1021 zu senden.

Wird im Projekt D4 un";
CM_ SG_ 278 ESP_Wegimpuls_VL "Wegimpulszähler VL.
Anzahl der Wegimpulse Vorderrad links (steigende und fallende Flanke)
Zähler läuft grundsätzlich vorwärts, auch bei Rückwärtsfahrt.
Nach SG-Reset ist immer, ohne Ausnahme, 1mal der Init Wert 1021 zu senden.

Wird im Projekt D4 und";
CM_ SG_ 278 ESP_Wegimpuls_VR "Wegimpulszähler VR.
Anzahl der Wegimpulse Vorderrad rechts (steigende und fallende Flanke)
Zähler läuft grundsätzlich vorwärts, auch bei Rückwärtsfahrt.
Nach SG-Reset ist immer, ohne Ausnahme, 1mal der Init Wert 1021 zu senden.

Wird im Projekt D4 un";

CM_ SG_ 178 ESP_HL_Radgeschw_02 "Radgeschwindigkeit hinten links";
CM_ SG_ 178 ESP_HR_Radgeschw_02 "Radgeschwindigkeit hinten rechts";
CM_ SG_ 178 ESP_VL_Radgeschw_02 "Radgeschwindigkeit vorne links";
CM_ SG_ 178 ESP_VR_Radgeschw_02 "Radgeschwindigkeit vorne rechts";

CM_ SG_ 1629 BR_QBit_Reifenumfang "Gesetzt bei Ersatzwert, Init oder Fehler.";
CM_ SG_ 1629 BR_Reifenumfang "Mittlerer Radumfang gerechnet in Millimeter.
Von der Bremse plausibilisierter Wert (Kopie von KBI_Reifenumfang wenn dieser plausibel) oder Ersatzwert aus Bremse wenn KBI_Reifenumfang unplausibel. Bitte das QBit beachten!

Im MEB wird das Signal KBI_Rei";
CM_ SG_ 1629 BR_Systemart "Identifikation des verbauten Bremssystems

Dient dem Kombi zur Plausibilisierung";
CM_ SG_ 1629 ESP_20_CRC "Für MLB:
'Berechnung siehe Lastenheft 'Kommunikationsabsicherung für FlexRay und CAN''

Ab MQB und MLBevo:
'Berechnung siehe Lastenheft 'End-to-End Kommunikationsabsicherung''

Endwerte siehe Begleitdokument 'S-PDU Kennungsfolgen'";
CM_ SG_ 1629 ESP_Charisma_FahrPr "MLBevo: Aktuelles Fahrprogramm des Charisma-Teilnehmers (siehe Systemlastenheft Drive Select)
MQB: Istwert der Kennlinie (siehe Systemlastenheft MQB FPA)";
CM_ SG_ 1629 ESP_Charisma_Status "Systemstatus des Charismateilnehmers

Wert 0x3 ist nur für Fahrzeuge ab MQB relevant";
CM_ SG_ 1629 ESP_Dachrelingsensor "Erkennung auf Verbau des Dachrelingsensors und Dachquerträger.";
CM_ SG_ 1629 ESP_SpannungsAnf_02 "Forderung des ESP-SG's zur Spannungsanhebung.";
CM_ SG_ 1629 ESP_Stoppverbot_Anz_01 "Dieses Signal gibt die detaillierte Begründung für ein Stoppverbot vom Bremsensteuergerät an.";
CM_ SG_ 1629 ESP_Stoppverbot_Anz_02 "Dieses Signal gibt die detaillierte Begründung für ein Stoppverbot vom Bremsensteuergerät an.";
CM_ SG_ 1629 ESP_Stoppverbot_Anz_03 "Dieses Signal gibt die detaillierte Begründung für ein Stoppverbot vom Bremsensteuergerät an.";
CM_ SG_ 1629 ESP_Stoppverbot_Anz_04 "Dieses Signal gibt die detaillierte Begründung für ein Stoppverbot vom Bremsensteuergerät an.";
CM_ SG_ 1629 ESP_Stoppverbot_Anz_05 "Dieses Signal gibt die detaillierte Begründung für ein Stoppverbot vom Bremsensteuergerät an.";
CM_ SG_ 1629 ESP_Stoppverbot_Anz_06 "Dieses Signal gibt die detaillierte Begründung für ein Stoppverbot vom Bremsensteuergerät an.";
CM_ SG_ 1629 ESP_Stoppverbot_Anz_07 "Dieses Signal gibt die detaillierte Begründung für ein Stoppverbot vom Bremsensteuergerät an.";
CM_ SG_ 1629 ESP_Stoppverbot_Anz_08 "Dieses Signal gibt die detaillierte Begründung für ein Stoppverbot vom Bremsensteuergerät an.";
CM_ SG_ 1629 ESP_Stoppverbot_Anz_Std "Dieses Signal gibt die detaillierte Begründung für ein Stoppverbot vom Bremsensteuergerät an.";
CM_ SG_ 1629 ESP_Wiederstart_Anz_01 "Dieses Signal gibt die detaillierte Begründung für einen Wiederstart vom Bremsensteuergerät an. ";
CM_ SG_ 1629 ESP_Wiederstart_Anz_02 "Dieses Signal gibt die detaillierte Begründung für einen Wiederstart vom Bremsensteuergerät an. ";
CM_ SG_ 1629 ESP_Wiederstart_Anz_03 "Dieses Signal gibt die detaillierte Begründung für einen Wiederstart vom Bremsensteuergerät an. ";
CM_ SG_ 1629 ESP_Wiederstart_Anz_04 "Dieses Signal gibt die detaillierte Begründung für einen Wiederstart vom Bremsensteuergerät an.";
CM_ SG_ 1629 ESP_Zaehnezahl "Konstanter Wert der Zähnezahl des verwendeten Impulsrades wird ausgegeben, jeder Empfänger der Wegimpulse muss die Zähnezahl einlesen, um eine volle Umdrehung des Rades zu erkennen. 

Weiterführende Informationen im Lastenheft spezifiziert und in der en";
CM_ SG_ 1629 HDC_Charisma_FahrPr "MLBevo: Aktuelles Fahrprogramm des Charisma-Teilnehmers (siehe Systemlastenheft Drive Select)
MQB: Istwert der Kennlinie (siehe Systemlastenheft MQB FPA)";
CM_ SG_ 1629 HDC_Charisma_Status "Systemstatus des Charismateilnehmers

Wert 0x3 ist nur für Fahrzeuge ab MQB relevant";

CM_ SG_ 253 ABS_Bremsung "Antiblockiersystem, Bit zeigt auch Druckabbau an (z.B. ESP hat zuviel Druck aufgebaut oder ungebremste Regelung auf Bahnübergang)
Weiterführende Informationen im Lastenheft spezifiziert und in der entsprechenden Fachabteilung zu erfragen.";
CM_ SG_ 253 ASR_Anf "MLB: Die Momentenanforderung 'ASR_MSR_Moment_schnell' und 'ASR_Moment_langsam' sind auszuführen
MQB: Die Momentenanforderung 'BR_Eingriffsmoment' ist auszuführen";
CM_ SG_ 253 ASR_Schalteingriff "Wunsch an das Getriebe während einer ASR Regelung

MLB: Es wird nur 0x0 und 0x1 genutzt

";
CM_ SG_ 253 ASR_Tastung_passiv "ASR deaktiviert oder Schwellen geändert (projektabhängig)
Weiterführende Informationen im Lastenheft spezifiziert und in der entsprechenden Fachabteilung zu erfragen.
";
CM_ SG_ 253 BR_Eingriffsmoment "Einheitenloser Wert! Faktor in MO_Faktor_Momente_02 in Motor_Code_01 beachten!
Schnelle reduzierende (ASR) oder erhöhende (MSR) Momentanforderung an den Motor.";
CM_ SG_ 253 EBV_Eingriff "Elektronische Bremskraftverteilung, aktueller Eingriff (Druckhalten, Druckabbau)

Im MLB: kein ABS / ESP-Eingriff ???";
CM_ SG_ 253 EDS_Eingriff "Elektronische Differentialsperre";
CM_ SG_ 253 ESC_Reku_Freigabe "Mit diesem Bit wird die Rekuperation im Motorsteuergerät erlaubt. Bei Ausfall ESC wird Rekuperation nicht freigegeben.

MQB/MQB2020: Wird nur von einem blendfähigen ESC unterstützt, wie es in mHEV und pHEV Fahrzeugen eingesetzt wird.";
CM_ SG_ 253 ESC_v_Signal_Qualifier_High_Low "Das Qualifizerungssignal ESC_v_Signal_Qualifier_High_Low gibt eine Information über die Güte der vom Bremsregelsystem ausgegebenen Geschwindigkeitsinformation 'mittlere Geschwindigkeit', wobei Vertrauensbereiche für das ausgegebene Geschwindigkeitssignal ";
CM_ SG_ 253 ESP_21_CRC "Für MLB:
'Berechnung siehe Lastenheft 'Kommunikationsabsicherung für FlexRay und CAN''

Ab MQB und MLBevo:
'Berechnung siehe Lastenheft 'End-to-End Kommunikationsabsicherung''

Endwerte siehe Begleitdokument 'S-PDU Kennungsfolgen'";
CM_ SG_ 253 ESP_Anhaltevorgang_ACC_aktiv "Zeigt an, ob ACC-Anhaltevorgang aktiv";
CM_ SG_ 253 ESP_ASP "MLB: Anhaenger-Stabilisierungs-Programm
MQB: Gespannstabilisierung";
CM_ SG_ 253 ESP_AWV3_Brems_aktiv "Teil-, Ziel- oder Notbremsung wird im ESP für AWV3 umgesetzt (das MSG nutzt diese Info für den Abwurf der GRA-Regelung).";
CM_ SG_ 253 ESP_Diagnose "MLB: Nach Diagnoseende wird ein SW-Reset ausgelöst welcher einen Kommunikatiosausfall für max. 150ms verursacht. Dies ist bei SG mit verschärfter Timeoutüberwachung (nicht nach Konzern-LH) zu beachten.

MQB: Weiterführende Informationen im Lastenheft sp";
CM_ SG_ 253 ESP_Eingriff "Eingriff des Fahrdynamikreglers";
CM_ SG_ 253 ESP_Haltebestaetigung "Rückmeldung vom ESP-SG, dass das Fahrzeug aufgrund einer externen Bremsanforderung (z. B. ACC, PLA, ANB, o. ä.) abgebremst wurde und im Stillstand gehalten wird.";
CM_ SG_ 253 ESP_MKB_Abbruch_Geschw "Im Falle einer Multikollisionsbremsung teilt das ESP den Abbruch der MKB aufgrund der unteren Geschwindigkeitsschwelle mit.";
CM_ SG_ 253 ESP_PLA_Bremseingriff "Signalisierung des aktiven Bremseingriffes des ESP aufgrund einer Bremsanforderung vom PLA.";
CM_ SG_ 253 ESP_QBit_v_Signal "Geschwindigkeit wird vom ABS/ASR oder ESP aus Ersatzwerten errechnet, wenn Bit gesetzt ist. Güte des Signals ist verändert.";
CM_ SG_ 253 ESP_Systemstatus "Fehler steht für Stillegung ESP mit Fehlereintrag.

MLB: Flag wird bei Unterspannung im Stand bis einmalig 6km/h (AU48x) oder 10 km/h (AU641, AU57x) überschritten nicht gesetzt (Ausblendung Startvorgang)
Im AU64x, AU57x gilt ESP D4 Funktionsanforderung";
CM_ SG_ 253 ESP_Tastung_passiv "ESP deaktiviert oder Schwellen geändert (projektabhängig)
Weiterführende Informationen im Lastenheft spezifiziert und in der entsprechenden Fachabteilung zu erfragen.";
CM_ SG_ 253 ESP_v_Signal "Geschwindigkeitssignal vom ABS/ASR oder ESP. Mittelwert der angetriebenen Räder.
Bei MSR oder ABS Eingriffen wird die ABS-Referenzgeschwindigkeit für >= 200ms eingespiegelt (Zeit wird mit Aktiv-Flanke der Funktionsbits getriggert)

MQB: Bei Frontantrie";
CM_ SG_ 253 ESP_Vorsteuerung "zur Unterscheidung zwischen ESP-Vorsteuermaßnahmen und ESP-Regeleingriffen";
CM_ SG_ 253 MSR_Anf "MLB: Die Momentenanforderung 'ASR_MSR_Moment_schnell' ist auszuführen.
MQB: Die Momentenanforderung 'BR_Eingriffsmoment' ist auszuführen";
CM_ SG_ 253 OBD_Schlechtweg "Für Ausblendung der Zündaussetzererkennung im Motorsteuergerät (Otto). Bit wird gesetzt, wenn Rad-Drehbeschleunigung im ESP > Grenzwert ist. Vorteil gegenüber Radgeschwindigkeiten, dass ESP alle 2 ms dynamisch die Rad-Drehbeschleunigung errechnet und dem ";

CM_ SG_ 795 ABS_Lampe "Sicherheitswarnlampe

Weiterführende Informationen im Lastenheft spezifiziert und in der entsprechenden Fachabteilung zu erfragen.";
CM_ SG_ 795 BK_Lampe_02 "Typ1_ein_statisch signalisiert EBV-Ausfall
MQB: wird auch bei HBV-Ausfall verwendet.

Typ1_ein_statisch: wird bei AUDI für Aktivierung der roten BKL ohne Text und Akustik verwendet (z.B. Lampenaufprüfung).
Typ2_ein_statisch: signalisiert elektrischen ";
CM_ SG_ 795 ESP_24_CRC "Für MLB:
'Berechnung siehe Lastenheft 'Kommunikationsabsicherung für FlexRay und CAN''

Ab MQB und MLBevo:
'Berechnung siehe Lastenheft 'End-to-End Kommunikationsabsicherung''

Endwerte siehe Begleitdokument 'S-PDU Kennungsfolgen'";
CM_ SG_ 795 ESP_BKV_Warnung "ESP sendet im Hinweis- /Störungsfall an das Kombi Informationen zum Anzeigen (Text + Akustik)

Im MQB wird dieses Signal nicht unterstützt!
";
CM_ SG_ 795 ESP_Fehlerstatus_Wegimp "Weiterführende Informationen im Lastenheft spezifiziert und in der entsprechenden Fachabteilung zu erfragen.

MLB: Fehler wird gesetzt, wenn beide ESP-Drehzahlfühler an der Vorderachse defekt sind.

MQB: Fehler wird gesetzt, wenn beide Raddrehzahlfühl";
CM_ SG_ 795 ESP_HDC_FktLampe "Funktionslampe Bergabfahrassistent.
(Sender blinkt mit dem Bit 3,3Hz)";
CM_ SG_ 795 ESP_HDC_Regelgeschw "Verwendung/Bedienung nur im AU57x Allroad:
HDC-Geschwindigkeit
Dient der Anzeige der HDC-Geschwindigkeit und eines Bergabfahrsymbols im Kombi.
HDC-Standby wird gesetzt sobald der Fahrer den HDC-Taster aktiviert hat.
Bei HDC-Off oder während der Initia";
CM_ SG_ 795 ESP_Lampe "Zustand der Fahrdynamikregelungslampe (MLB: ASR und/oder ESP, MQB: nur ESP)

Weiterführende Informationen im Lastenheft spezifiziert und in der entsprechenden Fachabteilung zu erfragen.";
CM_ SG_ 795 ESP_m_Raddrehz "Radumdrehungen pro Sekunde sind Eingangsgröße für die Geschwindigkeitsberechnung im Kombi. Aus dieser Raddrehzahl und dem Radumfang wird die Fahrzeuggeschwindigkeit errechnet.

MLB: Exklusiver Empfänger ist das Kombiinstrument!
MQB: Bei Frontantrieb un";
CM_ SG_ 795 ESP_Meldungen "ESP sendet im Hinweis- /Störungsfall an das Kombi Informationen zum Anzeigen

Weiterführende Informationen im Lastenheft spezifiziert und in der entsprechenden Fachabteilung zu erfragen.
Ergänzender Hinweis:
1 = Autohold_Hinweis_1 (Anfahrassistent: nu";
CM_ SG_ 795 ESP_Off_Lampe "Bit zur Ansteuerung der separaten ESP-off-Lampe im Kombi (Gesetzesforderung USA)

MLB:
Verwendung/Bedienung ab D4";
CM_ SG_ 795 ESP_QBit_Wegimp_VA "Gesetzt bei Ersatzwert, Init oder Fehler.";
CM_ SG_ 795 ESP_Textanzeigen_03 "Textanzeigen der Fahrdynamikregelung im Kombiinstrument

Weiterführende Informationen im Lastenheft spezifiziert und in der entsprechenden Fachabteilung zu erfragen.

Der Signalwert 24 wird nur im BY736 verwendet.";
CM_ SG_ 795 ESP_Wegimp_Ueberlauf "Der Wegimpulszähler ist pro Zündungslauf mindestens einmal übergelaufen

Weiterführende Informationen im Lastenheft spezifiziert und in der entsprechenden Fachabteilung zu erfragen.";
CM_ SG_ 795 ESP_Wegimp_VA "Weiterführende Informationen im Lastenheft spezifiziert und in der entsprechenden Fachabteilung zu erfragen.

MLB: Die Wegimpulse Vorderachse sind die gemittelten Werte (reine mathematische Operation: Addition und Division durch zwei, keine Filterung) d";
CM_ SG_ 795 TC_Lampe "M-ABS Lampe (separate Lampe für M-ABS-Systeme Markt Brasilien)

Weiterführende Informationen im Lastenheft spezifiziert und in der entsprechenden Fachabteilung zu erfragen.";

CM_ SG_ 2463978794 FBS_Anf_Access_Auth "Trigger um Authentifikation für Zugang zu starten";
CM_ SG_ 2463978794 FBS_Anf_Start_Auth "Trigger um Authentifikation zu starten";
CM_ SG_ 2463978794 FBS_MDK_button "smart device button pressed signalling for remote keyless entry";
CM_ SG_ 2463978794 FBS_MDK_in_Reichweite "Für elektrisch betätigte Türen und Klappen muss für eine Remote-Betätigung mittels MobileDeviceKey eine Reichweitenbegrenzung eingeführt werden. Dieses Bit zeigt an, dass sich der MobileDeviceKey innerhalb der geforderten Reichweite befindet";
CM_ SG_ 2463978794 WLC_laden_unterbrechen "Kommunikation zur Phonebox, das Laden zu unterbrechen";

CM_ SG_ 2527679800 FBS_MKGO_01 "NFC Kommunikation FBS zu MKGO";

CM_ SG_ 2527679801 FBS_MKGO_02 "NFC Kommunikation FBS zu MKGO";

CM_ SG_ 2527679802 FBS_MKGO_03 "NFC Kommunikation FBS zu MKGO";

CM_ SG_ 2527679803 FBS_MKGO_04 "NFC Kommunikation FBS zu MKGO";

CM_ SG_ 2527679804 FBS_MKGO_05 "NFC Kommunikation FBS zu MKGO";

CM_ SG_ 1605 FLA_Abblendursache "FLA Abblendursache
(20ms Task)";
CM_ SG_ 1605 FLA_aktiv "FLA aktiv  (200ms Task)";
CM_ SG_ 1605 FLA_Aufblenden "FLA Aufblenden (20ms Task)";
CM_ SG_ 1605 FLA_Fernlicht_PWM "FLA PWM Vorgabe Fernlicht
(20ms Task)";
CM_ SG_ 1605 FLA_ISP_defekt "FLA defekt (Innenspiegelkamera oder Multifunktionskamera)
interner Fehler  (200ms Task)";
CM_ SG_ 1605 FLA_SAE_Mode "Rückmeldung an den Fahrer, über Wechsel in den SAE Modus --> wird nur für den amerikanischen Markt benötigt.";
CM_ SG_ 1605 FLA_Sensor_blockiert "FLA Sensor blockiert
Sichtbeeinträchtigung der Kamera  (200ms Task)";
CM_ SG_ 1605 ISP_EC_aktiv "Status Innenspiegel (EC-Spiegel)";
CM_ SG_ 1605 ISP_EC_Lichtwert_hinten "Innenspiegel: Lichtwert hinten
";
CM_ SG_ 1605 ISP_EC_Lichtwert_vorne "Innenspiegel: Lichtwert vorne
";
CM_ SG_ 1605 ISP_Himmelsrichtung "Himmelsrichtung Kompass im EC Spiegel
Wertebereich 0-29 (12°-Schritte, 0-348°)
";
CM_ SG_ 1605 ISP_Kompass_aktiv "Status Kompass Innenspiegel";
CM_ SG_ 1605 ISP_Taste_betaetigt "ISP Taste betätigt
(200ms Task)";

CM_ SG_ 2589283684 FoD_Transmission_Info "Mit dem Signal zeigt der FoD-Master allen FoD-Slaves den Beginn und das Ende eines Freischaltuebertragungszykluses (FS-ID-Zyklus) an.";
CM_ SG_ 2589283684 GRA_FoD_Status "Verortung des FOD-Slaves für die Funktion GRA erfolgt im Gateway. Signal übermittelt den FOD-Status an das MSG.";

CM_ SG_ 2549875470 FoD_BCM1_Req_Data "FoD - Function On Demand
ISO-TP Datenkanal - FID2NA
Request Funktion 0x03 FoD-Master

FoD-Master an BCM1";

CM_ SG_ 2550006542 FoD_BCM1_Resp_Data "FoD - Function On Demand
ISO-TP Datenkanal - FID2NA
Response Knoten 0x0E BCM

BCM an FoD Master";

CM_ SG_ 986 ABS_Bremsung "Antiblockiersystem, Bit zeigt auch Druckabbau an (z.B. ESP hat zuviel Druck aufgebaut oder ungebremste Regelung auf Bahnübergang)
Weiterführende Informationen im Lastenheft spezifiziert und in der entsprechenden Fachabteilung zu erfragen.";
CM_ SG_ 986 ECD_Bremslicht "Bremslichtansteuerung durch ECD-Funktion";
CM_ SG_ 986 EPB_Pedalweg_Kuppl "Signal entspricht Tastverhältnis des PWM. Gesamtweg Kupplungspedal 10% bis 90%, damit zu erwartende Werte 25 bis 225. 25 bei Kupplungspedal nicht getreten, 225 bei Kupplungspedal voll durchgetreten.
2% Toleranz wird im Wertebereich ermöglicht (8%-92%).
";
CM_ SG_ 986 EPB_Status "Gibt den Zustand der EPB-Aktuatoren an.

Nur VW526/PAG E2: Wert 0x3 bedeutet 'unbekannt'

";
CM_ SG_ 986 ESP_Eingriff "Eingriff des Fahrdynamikreglers";
CM_ SG_ 986 ESP_HDC_Standby "Verwendung/Bedienung im MQB und AU57x Allroad:
Flag wird vom ESP gesetzt, wenn über den HDC-Taster die HDC-Funktion eingeschalten wurde";
CM_ SG_ 986 ESP_MKB_Abbruch_Geschw "Im Falle einer Multikollisionsbremsung teilt das ESP den Abbruch der MKB aufgrund der unteren Geschwindigkeitsschwelle mit.";
CM_ SG_ 986 ESP_QBit_v_Signal "Geschwindigkeit wird vom ABS/ASR oder ESP aus Ersatzwerten errechnet, wenn Bit gesetzt ist. Güte des Signals ist verändert.";
CM_ SG_ 986 ESP_v_Signal "Geschwindigkeitssignal vom ABS/ASR oder ESP. Mittelwert der angetriebenen Räder.
Bei MSR oder ABS Eingriffen wird die ABS-Referenzgeschwindigkeit für >= 200ms eingespiegelt (Zeit wird mit Aktiv-Flanke der Funktionsbits getriggert)

MQB: Bei Frontantrie";
CM_ SG_ 986 Kamera_FSH_aktiv "Bei aktivierter (lokaler) Frontscheibenheizung wird die Scheibentemperaturmessung des Klimafeuchtesensors beeinflusst. Über das Signal wird dem Klima-SG mitgeteilt, dass die lokale Scheibenheizung aktiviert ist, um entsprechende Korrekturwerte bei der Sch";
CM_ SG_ 986 LWI_Lenkradwinkel "Wertebereich = +/- 800 Grad
Auflösung = 0,1 Grad
ACHTUNG: spezifizierte Interne Auflösung des Sensors beträgt aber nur Schrittweite 0,5 Grad!

Hinweis:
MLB: Zusätzlich gestellte Winkel bei Dynamiklenkung beachten !
MQB: Nicht konstante Lenkübersetzu";
CM_ SG_ 986 LWI_QBit_Lenkradwinkel "Das QBit wird auch bei nicht abgeglichenem Lenkradwinkelsensor gesetzt";
CM_ SG_ 986 LWI_VZ_Lenkradwinkel "Vorzeichen Lenkradwinkel gemäss DIN70000; 
Nullstellung = +0";
CM_ SG_ 986 PH_Anf_Audioabsenkung "Es gibt zwei unterschiedliche Nachlauftimer für dieses Bit:
1. normale Funktion
2. Demotonausgabe";
CM_ SG_ 986 PH_Systemzustand "Aktivierungsursache wird für die Dauer der Aktivierung gemeldet.
Im Fehlerfall bei atkviem System wechselt das Signal auf '7'
(siehe auch 'Abschaltursache')";
CM_ SG_ 986 PH_Taster "Taster Status (für RVC/TopView)";
CM_ SG_ 986 PLA_Anf_Aufschaltung_RVC "Anforderung der Aufschaltung RVC durch PLA";

CM_ SG_ 988 ACC_18_alt "Veraltet-Bit";
CM_ SG_ 988 ACC_Status_ACC "'ACC OFF' bedeutet ACC-Hauptschalter ist 'Gerastet Aus

'ACC Reversibler Fehler' bedeutet, daß das ACC aktuell einen 
reversiblen Fehler im ACC-SG selbst oder in einem zum 
ACC-System gehörenden SG erkennt.

'ACC irreversibler Fehler' bedeutet, daß ";
CM_ SG_ 988 Bel_DiETa_Mode2 "Statusanzeige FPA-Mode2 in den Direkteinstiegstasten (GTE-Taster im VW380 PHEV)";
CM_ SG_ 988 EPB_Schalterposition "Spiegelt die Schalterstellung wieder.

0x3 = Schalterfehler ";
CM_ SG_ 988 EPB_Status_02 "Erweiterung der Zustände um ein genaueres Bild des aktuellen Zustandes zu erhalten für weitergehende Funktionen ( Stillstandsmanager)
";
CM_ SG_ 988 ESP_50_alt "Veraltet-Bit";
CM_ SG_ 988 ESP_Rollenmodus_Deaktivieren "Zwang zum Abbruch des Rollenmodus mit anschließender ESP-Vollfunktion.
MQB: Zwang zum Abbruch des Rollenmodus in allen Funktionsteilnehmern (Empfänger) mit anschließender ESP-Vollfunktion (Sender).
Signal wird vom ESP dauerhaft mit gültigen Werten bedat";
CM_ SG_ 988 GE_Fahrstufe "Fahrprogramm des Getriebes

Hinweis: Zwischenstellung '0x0' darf nur für Zustandswechsel P/R, R/N, N/D ausgegeben werden, nicht für D/S oder D/Tippgasse wegen Abschaltkriterium GRA/ACC";
CM_ SG_ 988 GE_Freilauf_Status "Freilauf-Status-Signal vom Frailauf-Master an aktive Freilauf-Teilnehmer. In diesem Signal zeigt der Freilauf-Master an, welchen aktuellen Status die Freilauf-Betriebsstrategie hat.";
CM_ SG_ 988 GE_LaunchControl "Während einer LaunchControl-Anfahrt sendet das Getriebesteuergerät das Bit LaunchControl aktiv.
Die Bremse wertet dieses Bit aus, um während einer solchen Anfahrt die Regelgrenzen der Schlupfregelung zu erweitern.
Im Motor Nutzung zur Verbesserung des A";
CM_ SG_ 988 GE_Notlauf "AL/DL: Signalisiert wenn sich das Getriebe (bei DL ein Teilgetriebe) im Notlauf befindet.
VL: Wird gesetzt wenn kein Kraftschluss möglich ist.";
CM_ SG_ 988 GE_Sperr_Info_WFS "WFS-Sperrinformation";
CM_ SG_ 988 GE_Ursache_Fahrstufe_N "Zeigt an, warum Fahrstufe N angenommen wurde. So kann z.B. die Rollsicherung im Verlassenskonzept aktiv bleiben, wenn das Schalten nach N ohne Fahrerwunsch erfolgte (z.B. Fehlerreaktion).

ACHTUNG: Das Signal darf nur ausgewertet werden, wenn GE_Fahrstu";
CM_ SG_ 988 GE_Veto_Rollfaehigkeit "Der Schaltbetätigungsmaster kann mit diesem Signal die Rollfähigkeit bei Zündung aus ('N-Haltephase'/'Waschstraßenfunktion') situationsabhängig verhindern, z.B. bei einem Defekt der P-Taste.";
CM_ SG_ 988 MKE_Stufe "Das Signal bildet die Müdigkeitsstufe im Kombi ab:
0 - deaktiviert
1 - nicht_verfügbar
2 - Stufe_1
3 - Stufe_2
4 - Stufe_3
5 - Stufe_4
6 - reserviert
7 - reserviert";
CM_ SG_ 988 MKE_Texte "Systemhinweis und Sicherheitshinweis für Anzeige im Kombi";
CM_ SG_ 988 MO_Drehzahl_01 "Im Fehlerfall wird die Motordrehzahl über die Nockenwellendrehzahl als Ersatzgrösse ausgegeben

Bei Parallelhybrid: Getriebeeingangsdrehzahl (=E-Maschinen Drehzahl)

Hinweis: 
Ehemaliger Fehlerwert 0xFFFF wird senderseitig nicht unterstützt. 
Diesen";
CM_ SG_ 988 MO_QBit_Drehzahl_01 "AUDI D4: Zykluszeit: 10ms (siehe Zykluszeit schnell/Cycletime Fast)

Achtung:
Reduktion der Zykluszeit Motor_03 auf 10ms geplant.
Projektabhängig soll künftig mit 10ms gesendet werden.
Empfänger die in weiteren Konzern-Projekten eingesetzt werden müs";
CM_ SG_ 988 TSK_06_alt "Veraltet-Bit für die BotschaftTSK_06_alt";
CM_ SG_ 988 TSK_Hauptschalter_GRA_ACC "Stellung des GRA/ACC Hauptschalters. Das Signal wird auch bei Fehlerabschaltungen von GRA/ACC weiterhin bedient und ermöglicht für ACC die Steuerung der ACC-Anzeige auch in Fehlerfällen.";
CM_ SG_ 988 TSK_Limiter_ausgewaehlt "ACC/GRA-Betrieb nur bei nicht ausgewähltem Limiter möglich";
CM_ SG_ 988 TSK_Status "Betriebszustand des TSK-Reglers";

CM_ SG_ 1002 AWV_03_alt "Veraltet-Bit für die Signale:

Botschaft Gateway_77:
AWV_Zielobjekt";
CM_ SG_ 1002 AWV_Verz_Anf "Verzögerungsanforderung der Funktionen Zielbremsung und Teilbremsung an das VZM";
CM_ SG_ 1002 AWV_Verz_Freigabe "Freigabe-Bit der AWV Verzögerung an das VZM";
CM_ SG_ 1002 AWV_Zielobjekttyp "Definiert den Zielobjekttyp an VZM";
CM_ SG_ 1002 Bel_DiETa_Mode "Statusanzeige FPA-Mode in den Direkteinstiegstasten";
CM_ SG_ 1002 EBKV_03_alt "Veraltet Bit";
CM_ SG_ 1002 EBKV_Fahrer_bremst "Fahrer will bremsen (Eintreterkennung).
Wird benötigt, um ACC oder GRA abzuschalten.";
CM_ SG_ 1002 ESP_Bremsdruck "Rohwert des Bremsdrucks
Für Fahrzeuge mit elektrischem Bremskraftverstärker gilt: Aus dem Signal ESP_Bremsdruck lässt sich kein Fahrerbremswunsch ableiten. Das Signal bildet lediglich den hydraulischen Anteil der Fahrzeugverzögerung ab. Der Rohwert des S";
CM_ SG_ 1002 GE_Sumpftemperatur "Getriebesumpftemperatur wird über den Temperatursensor auf der Getriebeplatine ermittelt. Die absolute Sumpftemperatur wird vom Motor empfangen, um entsprechende Kühlleistung für das Getriebe einzustellen.";
CM_ SG_ 1002 MO_Fahrpedalrohwert_01 "AUDI D4: Zykluszeit: 10ms (siehe Zykluszeit schnell/Cycletime Fast)

Stellung des Fahrpedales (Rohwert, ohne Überlagerung durch GRA-Eingriffe etc.)

Die Funktionen zur Berechung des Fahrpedalrohwerts laufen im 10ms Raster. Der Fahrpedalwert berechnet ";
CM_ SG_ 1002 MO_Mom_Ist_Summe "Einheitenloser Wert! Faktor in MO_Faktor_Momente_02 in Motor_Code_01 beachten!

Ist-Moment als Summe aus Verbrennungsmotor und E-Motor (bei Hybrid-Konzepten) incl. allen Eingriffen und Korrekturen

In Fahrzeugen mit einer Antriebsachse bzw. mit mechan";
CM_ SG_ 1002 PaCo_DiETa_LED "Ansteuerung der Funktionsbeleuchtung im Direkteinstiegstaster ('DiETa') durch den Parking Coordinator ('PaCo').

0 LED_Inactive: Die Funktionsbeleuchtung im DiETa_Parken muss leuchten
1 LED_Active: Die Funktionsbeleuchtung im DiETa_Parken darf nicht le";
CM_ SG_ 1002 RTM_Warnstatus "Signalisiert die RTM-Warnstufe.";

CM_ SG_ 1003 AV_Umfeldbeleuchtung_Anf "Anforderung für die Aktivierung einer Umfeldbeleuchtung zur Unterstützung des Umfeldkamerasystems bei Dunkelheit";
CM_ SG_ 1003 EBKV_03_alt "Veraltet Bit";
CM_ SG_ 1003 EBKV_Fahrer_bremst "Fahrer will bremsen (Eintreterkennung).
Wird benötigt, um ACC oder GRA abzuschalten.";
CM_ SG_ 1003 EBKV_QBit_Fahrer_bremst "
";
CM_ SG_ 1003 EFF_Verbrauch_STH "Verbrauchsanteil der Standheizung im Komfortverbrauch (siehe EFF_Verbraucher_Balken)";
CM_ SG_ 1003 EPS_Lastinfo "entspricht Stromaufnahme des Lenkhilfe-SG, Auflösung = 1A";
CM_ SG_ 1003 ESP_50_alt "Veraltet-Bit";
CM_ SG_ 1003 ESP_Bremsdruck "Rohwert des Bremsdrucks
Für Fahrzeuge mit elektrischem Bremskraftverstärker gilt: Aus dem Signal ESP_Bremsdruck lässt sich kein Fahrerbremswunsch ableiten. Das Signal bildet lediglich den hydraulischen Anteil der Fahrzeugverzögerung ab. Der Rohwert des S";
CM_ SG_ 1003 ESP_QBit_Bremsdruck "QBit des Bremsdrucks. Gesetzt bei Ersatzwert, Init oder Fehler.";
CM_ SG_ 1003 LR_HZG_Konfiguration "Konfiguration der Heizmatte der Lenkradheizung";
CM_ SG_ 1003 LR_HZG_Taster_on_off "Anforderung des Schalters am MFL: Lenkradheizung aus/ein
(Regelung der LR_HZG ist im SMLS)";
CM_ SG_ 1003 LR_HZG_Temp_Sensor "Temperaturwert Lenkradheizung";
CM_ SG_ 1003 MFL_Signalhorn "Signalhorn nicht betaetigt/betaetigt";
CM_ SG_ 1003 MO_Fahrpedalrohwert_01 "AUDI D4: Zykluszeit: 10ms (siehe Zykluszeit schnell/Cycletime Fast)

Stellung des Fahrpedales (Rohwert, ohne Überlagerung durch GRA-Eingriffe etc.)

Die Funktionen zur Berechung des Fahrpedalrohwerts laufen im 10ms Raster. Der Fahrpedalwert berechnet ";
CM_ SG_ 1003 MO_QBit_Fahrpedalwerte_01 "AUDI D4: Zykluszeit: 10ms (siehe Zykluszeit schnell/Cycletime Fast)

QBit für beide Fahrpedalwerte des Motors (Fahrpedalrohsignal für ESP, EPB, ACC; Fahrpedalwert für Getriebe)

Achtung:
Reduktion der Zykluszeit Motor_03 auf 10ms geplant.
Projektabh";
CM_ SG_ 1003 MO_temporaere_Fahrerabwesenheit "Das Signal dient zur Signalisierung einer temporären Abwesenheit des Fahrers. In dieser Zeit ist es ihm möglich, sich durch gewisse ¿ im Verlassenskonzept definierte ¿ Fahreraktionen im aktuellen Fahrzyklus zurückzumelden.
Das Signal wird gesetzt, sobald";
CM_ SG_ 1003 PH_Stoermeldung "Meldung einer Störung der PDC an das Kombi";

CM_ SG_ 173 GE_Fahrstufe "Fahrprogramm des Getriebes

Hinweis: Zwischenstellung '0x0' darf nur für Zustandswechsel P/R, R/N, N/D ausgegeben werden, nicht für D/S oder D/Tippgasse wegen Abschaltkriterium GRA/ACC";
CM_ SG_ 173 GE_Ursache_Fahrstufe_N "Zeigt an, warum Fahrstufe N angenommen wurde. So kann z.B. die Rollsicherung im Verlassenskonzept aktiv bleiben, wenn das Schalten nach N ohne Fahrerwunsch erfolgte (z.B. Fehlerreaktion).

ACHTUNG: Das Signal darf nur ausgewertet werden, wenn GE_Fahrstu";
CM_ SG_ 173 Getriebe_11_BZ "Botschaftszähler";
CM_ SG_ 173 Getriebe_11_CRC "Für MLB:
'Berechnung siehe Lastenheft 'Kommunikationsabsicherung für FlexRay und CAN''

Ab MQB und MLBevo:
'Berechnung siehe Lastenheft 'End-to-End Kommunikationsabsicherung''

Endwerte siehe Begleitdokument 'S-PDU Kennungsfolgen'";

CM_ SG_ 299 GRA_Abbrechen "GRA : aus mit speichern
ACC : Soft aus";
CM_ SG_ 299 GRA_ACC_01_BZ "4bit Botschaftszaehler, wird mit jeder Sendebotschaft inkrementiert";
CM_ SG_ 299 GRA_ACC_01_CRC "Für MLB:
'Berechnung siehe Lastenheft 'Kommunikationsabsicherung für FlexRay und CAN''

Ab MQB und MLBevo:
'Berechnung siehe Lastenheft 'End-to-End Kommunikationsabsicherung''

Endwerte siehe Begleitdokument 'S-PDU Kennungsfolgen'";
CM_ SG_ 299 GRA_Codierung "Das Signal zeigt an, ob das Sende-SG (SMLS/MFL) auf GRA- oder ACC-Bedienteil codiert ist:
0: kein GRA- oder ACC Bedienteil
1: GRA-Bedienteil
2: ACC-Bedienteil
3: Limiter_Only-Bedienteil";
CM_ SG_ 299 GRA_Fehler "Das Signal zeigt an, dass das Sende-SG (SMLS/MFG) einen Defekt des GRA-Bedienteils erkannt hat und hierzu ein FSPE abgelegt wurde.";
CM_ SG_ 299 GRA_Hauptschalter "Stellung des GRA/ACC-Hauptschalters: 
Bei gerastetem Hauptschalter:
0: Hauptschalter aus
1: Hauptschalter ein
Bei getastetem Hauptschalter:
0: Taster nicht betätigt
1: Taster betätigt";
CM_ SG_ 299 GRA_LIM_Taste_verfuegbar "Das Signal zeigt an, ob eine Limiter-Umschalttaste am jeweiligen GRA/ACC-Bedienelement vorhanden ist.";
CM_ SG_ 299 GRA_Limiter "Stellung des Limiter-Tasters";
CM_ SG_ 299 GRA_PIT_Limiter "Stellung der Taste PIT-Speed-Limiter";
CM_ SG_ 299 GRA_reserveByte5 "Zweck: Befüllen der reservierten Bitpositionen mit 0 (wg. LIN-Teilnehmer MFL)";
CM_ SG_ 299 GRA_reserveByte6 "Zweck: Befüllen der reservierten Bitpositionen mit 0 (wg. LIN-Teilnehmer MFL)";
CM_ SG_ 299 GRA_reserveByte7 "Zweck: Befüllen der reservierten Bitpositionen mit 0 (wg. LIN-Teilnehmer MFL)";
CM_ SG_ 299 GRA_reserveByte8 "Zweck: Befüllen der reservierten Bitpositionen mit 0 (wg. LIN-Teilnehmer MFL)";
CM_ SG_ 299 GRA_Tip_Hoch "Tippschalter Tip Up / Geschwindigkeit erhöhen";
CM_ SG_ 299 GRA_Tip_Runter "Tippschalter Tip Down / Geschwindigkeit reduzieren";
CM_ SG_ 299 GRA_Tip_Setzen "Tippschalter Set";
CM_ SG_ 299 GRA_Tip_Stufe_2 "Signal zeigt an, dass der zweistufige GRA/ACC-Hebel (8_Positions_Bedienteil) in der 2. Tip-Stufe betätigt wird. Das Signal wird nur gleichzeitig mit dem Signal GRA_Tip_Hoch oder GRA_Tip_Runter gesetzt, wobei die Bits GRA_Tip_Hoch bzw. GRA_Tip_Runter die R";
CM_ SG_ 299 GRA_Tip_Wiederaufnahme "Tippschalter Wiederaufnahme";
CM_ SG_ 299 GRA_TravelAssist "Taste für TravelAssist";
CM_ SG_ 299 GRA_Typ_Bedienteil "Das Signal kennzeichnet die Variante des GRA/ACC-Bedienteils:
0: Init
1: 4-Positionen-Bedienteil (z.B. GRA im Blinkerhebel)
2: 6-Positionen-Bedienteil (GRA/ACC-Bedienteil mit separaten Stellungen für Set/Resume/TipUp/TipDown) 
3: 8-Positionen-Bediente";
CM_ SG_ 299 GRA_Typ_Hauptschalter "Variante des GRA/ACC-Hauptschalters:
0: gerasteter Hauptschalter (bzw. Taster mit Speicherung des Status im SMLS (PAG))
1: getasteter Hauptschalter, keine Speicherung des Status im SMLS";
CM_ SG_ 299 GRA_Verstellung_Zeitluecke "Verstellung der Zeitlücke für ACC

DIST -1 = Zeitluecke um 1 Stufe kleiner
DIST +1 = Zeitluecke um 1 Stufe groeßer
DIST Toggle = Zeitlücke um 1 Stufe kleiner, von kleinster Stufe auf größte Stufe";

CM_ SG_ 1410 HD_Bewegung_auf "Bewegung HD (öffnen)";
CM_ SG_ 1410 HD_Bewegung_zu "Bewegung HD (schließen)";
CM_ SG_ 1410 HD_Endstellung_oben "obere Endstellung HD
";
CM_ SG_ 1410 HD_Endstellung_unten "untere Endstellung HD";
CM_ SG_ 1410 HD_Innentaster_betaetigt "Betätigung Innentaster HD
";
CM_ SG_ 1410 HD_Position "HD Position von 0 bis 100 %";
CM_ SG_ 1410 HD_Rueckmeld_prog "Programmierung Endstellung HD 
";
CM_ SG_ 1410 HD_Taster_defekt "Anzeige ob Heckdeckeltaster defekt ist";
CM_ SG_ 1410 HD_UeKB_erkannt "Erkennung Einklemmschutz";
CM_ SG_ 1410 HD_Verr_Taster_betaetigt_inv "Inverses Bit (Fusi-Anforderung) Betätigung des Verriegelungstaster für Heckdeckel";
CM_ SG_ 1410 HD_Verriegelungstaster_betaetigt "Betätigung des Verriegelungstaster für Heckdeckel";
CM_ SG_ 1410 HD_ZZH_Schalter_S3 "Teilt den Zustand des Statusschalters in einer unidirektionalen ZZH mit.";
CM_ SG_ 1410 HDSG_Anf_Umluftklappe "Signal zur Ansteuerung der Umluftklappe Klima.";

CM_ SG_ 588 ASW_Akustik_Einstellung "Einstellung der Akustik der Funktion ASW.";
CM_ SG_ 588 ASW_Ausgabemodus_BFS "Ansteuerinformationen der ASW Aktoren";
CM_ SG_ 588 ASW_Ausgabemodus_FS "Ansteuerinformationen der ASW Aktoren";
CM_ SG_ 588 ASW_Ausgabemodus_HBFS "Ansteuerinformationen der ASW Aktoren";
CM_ SG_ 588 ASW_Ausgabemodus_HFS "Ansteuerinformationen der ASW Aktoren";
CM_ SG_ 588 ASW_Kombiausgabe "ASW_Kombiausgabe bestimmt, welcher Text im Kombi angezeigt wird. Darüber hinaus werden auch Kombi-Akkustik durch dieses Signal ausgelöst.";
CM_ SG_ 588 ASW_Kombitexte "ASW_Kombitexte bestimmt welcher Text im Kombi angezeigt wird. Darüber hinaus werden auch Kombi-Akkustik durch dieses Signal ausgelöst.

Dieses Signal ersetzt SWA_Anzeigen für den ASW-Anteil. Der SWA-Anteil des alten Signals findet sich in SWA-Kombitexte";
CM_ SG_ 588 ASW_Modus "gibt die Verfügbarkeit der ASW Modus an";
CM_ SG_ 588 ASW_Status "Funktionsstatus Ausstiegswarnung (ASW)";
CM_ SG_ 588 ASW_Ton_Richtung_HL "ASW-Warntonausgabe hinten links";
CM_ SG_ 588 ASW_Ton_Richtung_HR "ASW_Warntonausgabe hinten rechts";
CM_ SG_ 588 ASW_Ton_Richtung_VL "ASW-Warntonausgabe vorne links";
CM_ SG_ 588 ASW_Ton_Richtung_VR "ASW-Warntonausgabe vorne rechts";
CM_ SG_ 588 ASW_Warnung_BFS "Modus Beifahrerseite der Funktion Ausstiegswarnung (ASW)";
CM_ SG_ 588 ASW_Warnung_FS "Modus Beifahrerseite der Funktion Ausstiegswarnung (ASW)";
CM_ SG_ 588 Heckradar_Kombitexte "Heckradar_Kombitexte bestimmt welcher Text im Kombi angezeigt wird. Darüber hinaus werden auch Kombi-Akkustik durch dieses Signal ausgelöst.

Dieses Signal ersetzt SWA_Anzeigen und deckt alle Kombinationsmöglichkeiten der Heckradarfunktionen ab. Die Fun";
CM_ SG_ 588 HRE_Anzeigetexte "HRE-Texte und -Akustik zur Anzeige im Kombiinstrument";
CM_ SG_ 588 RCTA_Kombitexte "RCTA_Kombitexte bestimmt welcher Text im Kombi angezeigt wird. Darüber hinaus werden auch Kombi-Akkustik durch dieses Signal ausgelöst.";
CM_ SG_ 588 SWA_Anzeigen "SWA- Texte und -Akustik zur Anzeige im Kombiinstrument
0x7-0xF = reserviert";
CM_ SG_ 588 SWA_Blindheit_erkannt "SWA erkennt selbständig eigene Blindheit durch äußere Einflüsse.";
CM_ SG_ 588 SWA_Blindheitsverdacht "Signalwert wird auf Blindheitsverdacht_erkannt gesetzt, wenn ein im Datensatz parametrierbarer Schwellwert überschritten wurde.
Das Signal dient als Vorstufe zur SWA Blindheit und schaltet nicht die SWA Funktion ab.";
CM_ SG_ 588 SWA_Brightness_Mode_FPM "Actual mode for brightness settings of function Spurwechselassistent";
CM_ SG_ 588 SWA_FT_RueckLED "SWA/ASW Rückmelde-LED. Zeigt den Aktivierungszustand der Funktionen SWA/ASW";
CM_ SG_ 588 SWA_Gischtzaehler "Zähler, der die eigene Gischt bei nasser Fahrbahn misst (Kennwert)";
CM_ SG_ 588 SWA_Infostufe_Assist_li "Aktion der SWA-Funktion auf der entsprechenden Fahrzeugseite";
CM_ SG_ 588 SWA_Infostufe_Assist_re "Aktion der SWA-Funktion auf der entsprechenden Fahrzeugseite";
CM_ SG_ 588 SWA_Kombiausgabe "SWA_Kombiausgabe bestimmt, welcher Text im Kombi angezeigt wird.";
CM_ SG_ 588 SWA_Kombiwarnung "SWA_Kombiwarnung löst (akustische) Warnungen an den Fahrer aus";
CM_ SG_ 588 SWA_LED_Ausgabemodus_BFS "Ansteuerung SWA LED Beifahrerseite";
CM_ SG_ 588 SWA_LED_Ausgabemodus_FS "Ansteuerung SWA LED Fahrerseite";
CM_ SG_ 588 SWA_LED_Hell_BFS "Helligkeitswert SWA LED Beifahrerseite";
CM_ SG_ 588 SWA_LED_Hell_FS "Helligkeitswert SWA LED Fahrerseite";
CM_ SG_ 588 SWA_Modus "gibt die Verfügbarkeit der SWA Modus an";
CM_ SG_ 588 SWA_Modus_System "Gibt Zusatzinformationen zum SWA System Status an";
CM_ SG_ 588 SWA_rel_Fehler "Hinweis: In Zukunft das Signal SWA_Modus anstatt SWA_rel_Fehler verwenden!

SWA erkennt einen Fehler, die Objektdetektion betreffend, mit FSP-Eintrag.";
CM_ SG_ 588 SWA_rel_Nichtverf "Hinweis: In Zukunft das Signal SWA_Modus anstatt SWA_rel_Nichtverf verwenden!

SWA erkennt eine Nichtverfuegbarkeit, die Objektdetektion betreffend, ohne FSP-Eintrag";
CM_ SG_ 588 SWA_Sta_aktiv "SWA Status aktiv; Lampenansteuerung im Kombi";
CM_ SG_ 588 SWA_Sta_passiv "Hinweis: In Zukunft das Signal SWA_Status anstatt SWA_Sta_passiv verwenden!

SWA Status passiv; Lampenansteuerung im Kombi";
CM_ SG_ 588 SWA_Standziele_li "Hinweis: In Zukunft das Signal SWA_StrukturLinks_querAbstand anstatt SWA_Standziele_li verwenden!

Abstand zwischen Fahrzeug und Standziele links geringer als ein applizierbarer Wert.";
CM_ SG_ 588 SWA_Standziele_re "Hinweis: In Zukunft das Signal SWA_StrukturRechts_querAbstand anstatt SWA_Standziele_re verwenden!

Abstand zwischen Fahrzeug und Standziele links geringer als ein applizierbarer Wert.";
CM_ SG_ 588 SWA_Status "gibt die Verfügbarkeit der SWA_Status an";
CM_ SG_ 588 SWA_Status_KuFu "Gibt den Status der Kundenfunktion SWA an";
CM_ SG_ 588 SWA_Status_System "Gibt den Status des Systems SWA an";
CM_ SG_ 588 SWA_Warnstufe_Assist_li "Aktion der SWA-Funktion auf der entsprechenden Fahrzeugseite";
CM_ SG_ 588 SWA_Warnstufe_Assist_re "Aktion der SWA-Funktion auf der entsprechenden Fahrzeugseite";

CM_ SG_ 1016 HLR_FlHz_Freigabe_HL "Freigabe des NVEM für die Flächenheizung hinten links";
CM_ SG_ 1016 HLR_FlHz_Freigabe_HR "Freigabe des NVEM für die Flächenheizung hinten rechts";
CM_ SG_ 1016 HLR_FlHz_Freigabe_Ruhesitz "Freigabe des NVEM für die Flächenheizung des Ruhesitzes";
CM_ SG_ 1016 HLR_FlHz_Freigabe_VL "Freigabe des NVEM für die Flächenheizung vorne links";
CM_ SG_ 1016 HLR_FlHz_Freigabe_VR "Freigabe des NVEM für die Flächenheizung vorne rechts";
CM_ SG_ 1016 HLR_FSH_Freigabe "Freigabe des EEM für die Frontscheibenheizung";
CM_ SG_ 1016 HLR_HSH_Freigabe "Freigabe des EEM für die Heckscheibenheizung";
CM_ SG_ 1016 HLR_KRH_Freigabe_VL "Freigabe des EEM für die Kopfraumheizung vorne links";
CM_ SG_ 1016 HLR_KRH_Freigabe_VR "Freigabe des EEM für die Kopfraumheizung vorne rechts";
CM_ SG_ 1016 HLR_LRH_Freigabe "Freigabe für die Lenkradheizung";
CM_ SG_ 1016 HLR_PTC_Freigabe "Freigabe des elektrischen Energiemanagements für das gestufte/geregelte PTC";
CM_ SG_ 1016 HLR_PTC_linear_Freigabe "Freigabe des EEM für den linearen PTC-Zuheizer";
CM_ SG_ 1016 HLR_SIH_Freigabe_Fond "Freigabe des EM für Sitzheizungen hinten";
CM_ SG_ 1016 HLR_SIH_Freigabe_HL "Freigabe des EEM für die Sitzheizung hinten links";
CM_ SG_ 1016 HLR_SIH_Freigabe_HR "Freigabe des EEM für die Sitzheizung hinten rechts";
CM_ SG_ 1016 HLR_SIH_Freigabe_VL "Freigabe des EEM für die Sitzheizung vorne links";
CM_ SG_ 1016 HLR_SIH_Freigabe_VR "Freigabe des EEM für die Sitzheizung vorne rechts";
CM_ SG_ 1016 HLR_SIL_Freigabe_HL "Freigabe des EEM für die Sitzbelüftung hinten links";
CM_ SG_ 1016 HLR_SIL_Freigabe_HR "Freigabe des EEM für die Sitzlüftung hinten rechts";
CM_ SG_ 1016 HLR_SIL_Freigabe_VL "Freigabe des EEM für die Sitzlüftung Vorne Links";
CM_ SG_ 1016 HLR_SIL_Freigabe_VR "Freigabe des EEM für die Sitzlüftung vorne Rechts";
CM_ SG_ 1016 HLR_Sp_Heizung_Freigabe_BT "Freigabe der Außenspiegelheizung Beifahrerseite";
CM_ SG_ 1016 HLR_Sp_Heizung_Freigabe_FT "Freigabe des EEM für die Außenspiegelheizung rechtsFreigabe der Außenspiegelheizung Fahrerseite";
CM_ SG_ 1016 HLR_TCH_Freigabe "Freigabe des NVEM für den Thermocupholder";

CM_ SG_ 2527679731 IL_TSG_BFS_Dimmzeit_1 "Dimmzeit für Ausgang 1 TSG BFS als Multiplikator der Dimmzeit Zeitbasis (Hinweis: Dimmzeit Zeitbasis für Ausgang 1 TSG BFS beachten)";
CM_ SG_ 2527679731 IL_TSG_BFS_Dimmzeit_2 "Dimmzeit für Ausgang 2 TSG BFS als Multiplikator der Dimmzeit Zeitbasis (Hinweis: Dimmzeit Zeitbasis für Ausgang 2 TSG BFS beachten)";
CM_ SG_ 2527679731 IL_TSG_BFS_Dimmzeit_3 "Dimmzeit für Ausgang 3 TSG BFS als Multiplikator der Dimmzeit Zeitbasis (Hinweis: Dimmzeit Zeitbasis für Ausgang 3 TSG BFS beachten)";
CM_ SG_ 2527679731 IL_TSG_BFS_Dimmzeit_4 "Dimmzeit für Ausgang 4 TSG BFS als Multiplikator der Dimmzeit Zeitbasis (Hinweis: Dimmzeit Zeitbasis für Ausgang 4 TSG BFS beachten)";
CM_ SG_ 2527679731 IL_TSG_BFS_Dimmzeit_Basis_1 "Dimmzeit Zeitbasis für Lichtausgang 1 TSG BFS umschaltbar zwischen 250ms und 50ms.";
CM_ SG_ 2527679731 IL_TSG_BFS_Dimmzeit_Basis_2 "Dimmzeit Zeitbasis für Lichtausgang 2 TSG BFS umschaltbar zwischen 250ms und 50ms.";
CM_ SG_ 2527679731 IL_TSG_BFS_Dimmzeit_Basis_3 "Dimmzeit Zeitbasis für Lichtausgang 3 TSG BFS umschaltbar zwischen 250ms und 50ms.";
CM_ SG_ 2527679731 IL_TSG_BFS_Dimmzeit_Basis_4 "Dimmzeit Zeitbasis für Lichtausgang 4 TSG BFS umschaltbar zwischen 250ms und 50ms.";
CM_ SG_ 2527679731 IL_TSG_BFS_Zielhelligkeit_1 "Intensität für Ausgang 1 TSG BFS";
CM_ SG_ 2527679731 IL_TSG_BFS_Zielhelligkeit_2 "Intensität für Ausgang 2 TSG BFS";
CM_ SG_ 2527679731 IL_TSG_BFS_Zielhelligkeit_3 "Intensität für Ausgang 3 TSG BFS";
CM_ SG_ 2527679731 IL_TSG_BFS_Zielhelligkeit_4 "Intensität für Ausgang 4 TSG BFS";

CM_ SG_ 2527679730 IL_TSG_FS_Dimmzeit_1 "Dimmzeit für Ausgang 1 TSG FS als Multiplikator der Dimmzeit Zeitbasis (Hinweis: Dimmzeit Zeitbasis für Ausgang 1 TSG FS beachten)";
CM_ SG_ 2527679730 IL_TSG_FS_Dimmzeit_2 "Dimmzeit für Ausgang 2 TSG FS als Multiplikator der Dimmzeit Zeitbasis (Hinweis: Dimmzeit Zeitbasis für Ausgang 2 TSG FS beachten)";
CM_ SG_ 2527679730 IL_TSG_FS_Dimmzeit_3 "Dimmzeit für Ausgang 3 TSG FS als Multiplikator der Dimmzeit Zeitbasis (Hinweis: Dimmzeit Zeitbasis für Ausgang 3 TSG FS beachten)";
CM_ SG_ 2527679730 IL_TSG_FS_Dimmzeit_4 "Dimmzeit für Ausgang 4 TSG FS als Multiplikator der Dimmzeit Zeitbasis (Hinweis: Dimmzeit Zeitbasis für Ausgang 4 TSG FS beachten)";
CM_ SG_ 2527679730 IL_TSG_FS_Dimmzeit_Basis_1 "Dimmzeit Zeitbasis für Lichtausgang 1 TSG FS umschaltbar zwischen 250ms und 50ms.";
CM_ SG_ 2527679730 IL_TSG_FS_Dimmzeit_Basis_2 "Dimmzeit Zeitbasis für Lichtausgang 2 TSG FS umschaltbar zwischen 250ms und 50ms.";
CM_ SG_ 2527679730 IL_TSG_FS_Dimmzeit_Basis_3 "Dimmzeit Zeitbasis für Lichtausgang 3 TSG FS umschaltbar zwischen 250ms und 50ms.";
CM_ SG_ 2527679730 IL_TSG_FS_Dimmzeit_Basis_4 "Dimmzeit Zeitbasis für Lichtausgang 4 TSG FS umschaltbar zwischen 250ms und 50ms.";
CM_ SG_ 2527679730 IL_TSG_FS_Zielhelligkeit_1 "Intensität für Ausgang 1 TSG FS";
CM_ SG_ 2527679730 IL_TSG_FS_Zielhelligkeit_2 "Intensität für Ausgang 2 TSG FS";
CM_ SG_ 2527679730 IL_TSG_FS_Zielhelligkeit_3 "Intensität für Ausgang 3 TSG FS";
CM_ SG_ 2527679730 IL_TSG_FS_Zielhelligkeit_4 "Intensität für Ausgang 4 TSG FS";

CM_ SG_ 2527679732 IL_TSG_HBFS_Dimmzeit_1 "Dimmzeit für Ausgang 1 TSG HBFS als Multiplikator der Dimmzeit Zeitbasis (Hinweis: Dimmzeit Zeitbasis für Ausgang 1 TSG HBFS beachten)";
CM_ SG_ 2527679732 IL_TSG_HBFS_Dimmzeit_2 "Dimmzeit für Ausgang 2 TSG HBFS als Multiplikator der Dimmzeit Zeitbasis (Hinweis: Dimmzeit Zeitbasis für Ausgang 2 TSG HBFS beachten)";
CM_ SG_ 2527679732 IL_TSG_HBFS_Dimmzeit_3 "Dimmzeit für Ausgang 3 TSG HBFS als Multiplikator der Dimmzeit Zeitbasis (Hinweis: Dimmzeit Zeitbasis für Ausgang 3 TSG HBFS beachten)";
CM_ SG_ 2527679732 IL_TSG_HBFS_Dimmzeit_4 "Dimmzeit für Ausgang 4 TSG HBFS als Multiplikator der Dimmzeit Zeitbasis (Hinweis: Dimmzeit Zeitbasis für Ausgang 4 TSG HBFS beachten)";
CM_ SG_ 2527679732 IL_TSG_HBFS_Dimmzeit_Basis_1 "Dimmzeit Zeitbasis für Lichtausgang 1 TSG HBFS umschaltbar zwischen 250ms und 50ms.";
CM_ SG_ 2527679732 IL_TSG_HBFS_Dimmzeit_Basis_2 "Dimmzeit Zeitbasis für Lichtausgang 2 TSG HBFS umschaltbar zwischen 250ms und 50ms.";
CM_ SG_ 2527679732 IL_TSG_HBFS_Dimmzeit_Basis_3 "Dimmzeit Zeitbasis für Lichtausgang 3 TSG HBFS umschaltbar zwischen 250ms und 50ms.";
CM_ SG_ 2527679732 IL_TSG_HBFS_Dimmzeit_Basis_4 "Dimmzeit Zeitbasis für Lichtausgang 4 TSG HBFS umschaltbar zwischen 250ms und 50ms.";
CM_ SG_ 2527679732 IL_TSG_HBFS_Zielhelligkeit_1 "Intensität für Ausgang 1 TSG HBFS";
CM_ SG_ 2527679732 IL_TSG_HBFS_Zielhelligkeit_2 "Intensität für Ausgang 2 TSG HBFS";
CM_ SG_ 2527679732 IL_TSG_HBFS_Zielhelligkeit_3 "Intensität für Ausgang 3 TSG HBFS";
CM_ SG_ 2527679732 IL_TSG_HBFS_Zielhelligkeit_4 "Intensität für Ausgang 4 TSG HBFS";

CM_ SG_ 2527679733 IL_TSG_HFS_Dimmzeit_1 "Dimmzeit für Ausgang 1 TSG HFS als Multiplikator der Dimmzeit Zeitbasis (Hinweis: Dimmzeit Zeitbasis für Ausgang 1 TSG HFS beachten)";
CM_ SG_ 2527679733 IL_TSG_HFS_Dimmzeit_2 "Dimmzeit für Ausgang  TSG HFS als Multiplikator der Dimmzeit Zeitbasis (Hinweis: Dimmzeit Zeitbasis für Ausgang 2 TSG HFS beachten)";
CM_ SG_ 2527679733 IL_TSG_HFS_Dimmzeit_3 "Dimmzeit für Ausgang 3 TSG HFS als Multiplikator der Dimmzeit Zeitbasis (Hinweis: Dimmzeit Zeitbasis für Ausgang 3 TSG HFS beachten)";
CM_ SG_ 2527679733 IL_TSG_HFS_Dimmzeit_4 "Dimmzeit für Ausgang 4 TSG HFS als Multiplikator der Dimmzeit Zeitbasis (Hinweis: Dimmzeit Zeitbasis für Ausgang 4 TSG HFS beachten)";
CM_ SG_ 2527679733 IL_TSG_HFS_Dimmzeit_Basis_1 "Dimmzeit Zeitbasis für Lichtausgang 1 TSG HFS umschaltbar zwischen 250ms und 50ms.";
CM_ SG_ 2527679733 IL_TSG_HFS_Dimmzeit_Basis_2 "Dimmzeit Zeitbasis für Lichtausgang 2 TSG HFS umschaltbar zwischen 250ms und 50ms.";
CM_ SG_ 2527679733 IL_TSG_HFS_Dimmzeit_Basis_3 "Dimmzeit Zeitbasis für Lichtausgang 3 TSG HFS umschaltbar zwischen 250ms und 50ms.";
CM_ SG_ 2527679733 IL_TSG_HFS_Dimmzeit_Basis_4 "Dimmzeit Zeitbasis für Lichtausgang 4 TSG HFS umschaltbar zwischen 250ms und 50ms.";
CM_ SG_ 2527679733 IL_TSG_HFS_Zielhelligkeit_1 "Intensität für Ausgang 1 TSG HFS";
CM_ SG_ 2527679733 IL_TSG_HFS_Zielhelligkeit_2 "Intensität für Ausgang 2 TSG HFS";
CM_ SG_ 2527679733 IL_TSG_HFS_Zielhelligkeit_3 "Intensität für Ausgang 3 TSG HFS";
CM_ SG_ 2527679733 IL_TSG_HFS_Zielhelligkeit_4 "Intensität für Ausgang 4 TSG HFS";

CM_ SG_ 27 WFS_IMMO_ELV_RND "WFS_IMMO_ELV_RND";

CM_ SG_ 19 WFS_IMMO_GSG_Data_0 "Zusatzinformation der WFS-Freigabe für GSG (z.B. Freigabe mit Geschw. Limitierung)";
CM_ SG_ 19 WFS_IMMO_GSG_Data_1 "Zusatzinformation der WFS-Freigabe für GSG (z.B. Freigabe mit Geschw. Limitierung)";
CM_ SG_ 19 WFS_IMMO_GSG_Data_2 "Zusatzinformation der WFS-Freigabe für GSG (z.B. Freigabe mit Geschw. Limitierung)";

CM_ SG_ 17 WFS_IMMO_MSG1_Data_0 "Zusatzinformation der WFS-Freigabe (z.B. Freigabe mit Geschw. Limitierung)";
CM_ SG_ 17 WFS_IMMO_MSG1_Data_1 "Zusatzinformation der WFS-Freigabe für MSG1/LE4 (z.B. Freigabe mit Geschw. Limitierung)";
CM_ SG_ 17 WFS_IMMO_MSG1_Data_2 "Zusatzinformation der WFS-Freigabe für MSG1/LE4 (z.B. Freigabe mit Geschw. Limitierung)";

CM_ SG_ 23 WFS_IMMO_MSG3_Data_0 "Zusatzinformation der WFS-Freigabe für MSG3/LE2 (z.B. Freigabe mit Geschw. Limitierung)";
CM_ SG_ 23 WFS_IMMO_MSG3_Data_1 "Zusatzinformation der WFS-Freigabe für MSG3/LE2 (z.B. Freigabe mit Geschw. Limitierung)";
CM_ SG_ 23 WFS_IMMO_MSG3_Data_2 "Zusatzinformation der WFS-Freigabe für MSG3/LE2 (z.B. Freigabe mit Geschw. Limitierung)";

CM_ SG_ 25 WFS_IMMO_MSG4_Data_0 "Zusatzinformation der WFS-Freigabe für MSG4/LE1 (z.B. Freigabe mit Geschw. Limitierung)";
CM_ SG_ 25 WFS_IMMO_MSG4_Data_1 "Zusatzinformation der WFS-Freigabe für MSG4/LE1 (z.B. Freigabe mit Geschw. Limitierung)";
CM_ SG_ 25 WFS_IMMO_MSG4_Data_2 "Zusatzinformation der WFS-Freigabe für MSG4/LE1 (z.B. Freigabe mit Geschw. Limitierung)";

CM_ SG_ 29 WFS_IMMO_OCU_CRC "WFS_IMMO_OCU_CRC";
CM_ SG_ 29 WFS_IMMO_OCU_RND "WFS_IMMO_OCU_RND";
BA_DEF_REL_ BU_SG_REL_  "GenSigTimeoutTime" INT 0 65535;
BA_DEF_ BO_  "DiagRequest" ENUM "No", "Yes";
BA_DEF_ BO_  "DiagResponse" ENUM "No", "Yes";
BA_DEF_ BO_  "DiagState" ENUM "No", "Yes";
BA_DEF_ BO_  "GenMsgChkConstant" HEX 0 4095;
BA_DEF_ BO_  "GenMsgCycleTime" INT 0 65535;
BA_DEF_ BO_  "GenMsgCycleTimeFast" INT 0 65535;
BA_DEF_ BO_  "GenMsgDelayTime" INT 0 100000;
BA_DEF_ BO_  "GenMsgILSupport" ENUM "No", "Yes";
BA_DEF_ BO_  "GenMsgNrOfRepetition" INT 0 100;
BA_DEF_ BO_  "GenMsgPDUConstants" STRING;
BA_DEF_ BO_  "GenMsgSendType" ENUM "Cyclic", "not_used", "not_used", "not_used", "not_used", "not_used", "not_used", "IfActive", "NoMsgSendType";
BA_DEF_ BO_  "GenMsgStartDelayTime" INT 0 100000;
BA_DEF_ BO_  "NmMessage" ENUM "No", "Yes";
BA_DEF_ BO_  "NmhMessage" ENUM "No", "Yes";
BA_DEF_ BO_  "MsgType" ENUM "Application", "NM ", "NMH", "TP2.0", "ISO-TP ", "BAP", "EID", "KS", "XCP_PRE_CONFIGURED", "XCP_RUNTIME_CONFIGURED";
BA_DEF_ BO_  "VAGTP20_API" HEX 0 255;
BA_DEF_ BO_  "VAGTP20_DynConnection" ENUM "No", "Yes";
BA_DEF_ BO_  "VAGTP20_DynSetup" ENUM "No", "Yes";
BA_DEF_ BO_  "VAGTP20_StatConnection" ENUM "No", "Yes";
BA_DEF_ BO_  "CANFD_BRS" ENUM "0", "1";
BA_DEF_ BO_  "VFrameFormat" ENUM "StandardCAN", "ExtendedCAN", "reserved", "reserved", "reserved", "reserved", "reserved", "reserved", "reserved", "reserved", "reserved", "reserved", "reserved", "reserved", "StandardCAN_FD", "ExtendedCAN_FD";
BA_DEF_ SG_  "GenSigActiveRepetitions" INT -2147483648 2147483647;
BA_DEF_ SG_  "GenSigInactiveValue" INT -2147483648 2147483647;
BA_DEF_ SG_  "GenSigSendType" ENUM "Cyclic", "OnWrite", "OnWriteWithRepetition", "OnChange", "OnChangeWithRepetition", "IfActive", "IfActiveWithRepetition", "NoSigSendType", "OnChangeAndIfActive", "OnChangeAndIfActiveWithRepetition";
BA_DEF_ SG_  "GenSigStartValue" INT -2147483648 2147483647;
BA_DEF_ SG_  "NWM-WakeupAllowed" ENUM "No", "Yes";
BA_DEF_ SG_  "GenSigFuncType" ENUM "NoFunction", "MsgCounter", "CRC-8", "XOR", "XOR-2", "DatedBit", "SW-Kl15", "CHK", "Constant", "Protocol", "CRC-8-SAE_J1850", "CRC-32", "DataLength", "DataID", "MsgCounter16", "SOK-Signatur", "Cluster";
BA_DEF_ SG_  "GenSigSwitchedByIgnition" ENUM "No", "Yes";
BA_DEF_ SG_  "Fehlerwert" HEX 0 2147483647;
BA_DEF_ SG_  "GenSigMissingSourceValue" HEX 0 2147483647;
BA_DEF_DEF_REL_  "GenSigTimeoutTime" 0;
BA_DEF_DEF_  "DiagRequest" "No";
BA_DEF_DEF_  "DiagResponse" "No";
BA_DEF_DEF_  "DiagState" "No";
BA_DEF_DEF_  "GenMsgChkConstant" 0;
BA_DEF_DEF_  "GenMsgCycleTime" 0;
BA_DEF_DEF_  "GenMsgCycleTimeFast" 0;
BA_DEF_DEF_  "GenMsgDelayTime" 0;
BA_DEF_DEF_  "GenMsgILSupport" "No";
BA_DEF_DEF_  "GenMsgNrOfRepetition" 0;
BA_DEF_DEF_  "GenMsgPDUConstants" "";
BA_DEF_DEF_  "GenMsgSendType" "NoMsgSendType";
BA_DEF_DEF_  "GenMsgStartDelayTime" 0;
BA_DEF_DEF_  "NmMessage" "No";
BA_DEF_DEF_  "NmhMessage" "No";
BA_DEF_DEF_  "MsgType" "Application";
BA_DEF_DEF_  "VAGTP20_API" 0;
BA_DEF_DEF_  "VAGTP20_DynConnection" "No";
BA_DEF_DEF_  "VAGTP20_DynSetup" "No";
BA_DEF_DEF_  "VAGTP20_StatConnection" "No";
BA_DEF_DEF_  "CANFD_BRS" "1";
BA_DEF_DEF_  "VFrameFormat" "StandardCAN";
BA_DEF_DEF_  "GenSigActiveRepetitions" 0;
BA_DEF_DEF_  "GenSigInactiveValue" 0;
BA_DEF_DEF_  "GenSigSendType" "NoSigSendType";
BA_DEF_DEF_  "GenSigStartValue" 0;
BA_DEF_DEF_  "NWM-WakeupAllowed" "No";
BA_DEF_DEF_  "GenSigFuncType" "NoFunction";
BA_DEF_DEF_  "GenSigSwitchedByIgnition" "Yes";
BA_DEF_DEF_  "Fehlerwert" 0;
BA_DEF_DEF_  "GenSigMissingSourceValue" 0;
BA_ "GenMsgCycleTime" BO_ 885 50;
BA_ "GenMsgILSupport" BO_ 885 1;
BA_ "GenMsgSendType" BO_ 885 0;
BA_ "CANFD_BRS" BO_ 885 0;
BA_ "VFrameFormat" BO_ 885 14;
BA_ "GenMsgChkConstant" BO_ 278 172;
BA_ "GenMsgCycleTime" BO_ 278 100;
BA_ "GenMsgILSupport" BO_ 278 1;
BA_ "GenMsgPDUConstants" BO_ 278 "0xac,0xac,0xac,0xac,0xac,0xac,0xac,0xac,0xac,0xac,0xac,0xac,0xac,0xac,0xac,0xac";
BA_ "GenMsgSendType" BO_ 278 0;
BA_ "CANFD_BRS" BO_ 278 0;
BA_ "VFrameFormat" BO_ 278 14;
BA_ "GenMsgCycleTime" BO_ 178 20;
BA_ "GenMsgILSupport" BO_ 178 1;
BA_ "GenMsgSendType" BO_ 178 0;
BA_ "CANFD_BRS" BO_ 178 0;
BA_ "VFrameFormat" BO_ 178 14;
BA_ "GenMsgCycleTime" BO_ 1629 1000;
BA_ "GenMsgDelayTime" BO_ 1629 200;
BA_ "GenMsgILSupport" BO_ 1629 1;
BA_ "GenMsgPDUConstants" BO_ 1629 "0xac,0xb3,0xab,0xeb,0x7a,0xe1,0x3b,0xf7,0x73,0xba,0x7c,0x9e,0x06,0x5f,0x02,0xd9";
BA_ "GenMsgSendType" BO_ 1629 0;
BA_ "CANFD_BRS" BO_ 1629 0;
BA_ "VFrameFormat" BO_ 1629 14;
BA_ "GenMsgCycleTime" BO_ 253 20;
BA_ "GenMsgILSupport" BO_ 253 1;
BA_ "GenMsgPDUConstants" BO_ 253 "0xb4,0xef,0xf8,0x49,0x1e,0xe5,0xc2,0xc0,0x97,0x19,0x3c,0xc9,0xf1,0x98,0xd6,0x61";
BA_ "GenMsgSendType" BO_ 253 0;
BA_ "CANFD_BRS" BO_ 253 0;
BA_ "VFrameFormat" BO_ 253 14;
BA_ "GenMsgCycleTime" BO_ 795 50;
BA_ "GenMsgILSupport" BO_ 795 1;
BA_ "GenMsgPDUConstants" BO_ 795 "0x67,0x8a,0xae,0x22,0x4d,0xd0,0x51,0x80,0x5c,0xb9,0xce,0x1e,0xdf,0x02,0x2d,0xd4";
BA_ "GenMsgSendType" BO_ 795 0;
BA_ "CANFD_BRS" BO_ 795 0;
BA_ "VFrameFormat" BO_ 795 14;
BA_ "GenMsgCycleTime" BO_ 2463978794 200;
BA_ "GenMsgCycleTimeFast" BO_ 2463978794 40;
BA_ "GenMsgDelayTime" BO_ 2463978794 20;
BA_ "GenMsgILSupport" BO_ 2463978794 1;
BA_ "GenMsgNrOfRepetition" BO_ 2463978794 7;
BA_ "GenMsgSendType" BO_ 2463978794 0;
BA_ "CANFD_BRS" BO_ 2463978794 0;
BA_ "VFrameFormat" BO_ 2463978794 15;
BA_ "GenMsgDelayTime" BO_ 2527679800 10;
BA_ "GenMsgILSupport" BO_ 2527679800 1;
BA_ "CANFD_BRS" BO_ 2527679800 0;
BA_ "VFrameFormat" BO_ 2527679800 15;
BA_ "GenMsgDelayTime" BO_ 2527679801 10;
BA_ "GenMsgILSupport" BO_ 2527679801 1;
BA_ "CANFD_BRS" BO_ 2527679801 0;
BA_ "VFrameFormat" BO_ 2527679801 15;
BA_ "GenMsgDelayTime" BO_ 2527679802 10;
BA_ "GenMsgILSupport" BO_ 2527679802 1;
BA_ "CANFD_BRS" BO_ 2527679802 0;
BA_ "VFrameFormat" BO_ 2527679802 15;
BA_ "GenMsgDelayTime" BO_ 2527679803 10;
BA_ "GenMsgILSupport" BO_ 2527679803 1;
BA_ "CANFD_BRS" BO_ 2527679803 0;
BA_ "VFrameFormat" BO_ 2527679803 15;
BA_ "GenMsgDelayTime" BO_ 2527679804 10;
BA_ "GenMsgILSupport" BO_ 2527679804 1;
BA_ "CANFD_BRS" BO_ 2527679804 0;
BA_ "VFrameFormat" BO_ 2527679804 15;
BA_ "GenMsgCycleTime" BO_ 1605 1000;
BA_ "GenMsgDelayTime" BO_ 1605 20;
BA_ "GenMsgILSupport" BO_ 1605 1;
BA_ "GenMsgSendType" BO_ 1605 0;
BA_ "CANFD_BRS" BO_ 1605 0;
BA_ "VFrameFormat" BO_ 1605 14;
BA_ "GenMsgCycleTime" BO_ 2589283684 1000;
BA_ "GenMsgCycleTimeFast" BO_ 2589283684 100;
BA_ "GenMsgDelayTime" BO_ 2589283684 100;
BA_ "GenMsgILSupport" BO_ 2589283684 1;
BA_ "GenMsgNrOfRepetition" BO_ 2589283684 3;
BA_ "GenMsgSendType" BO_ 2589283684 0;
BA_ "CANFD_BRS" BO_ 2589283684 0;
BA_ "VFrameFormat" BO_ 2589283684 15;
BA_ "MsgType" BO_ 2549875470 4;
BA_ "CANFD_BRS" BO_ 2549875470 0;
BA_ "VFrameFormat" BO_ 2549875470 15;
BA_ "MsgType" BO_ 2550006542 4;
BA_ "CANFD_BRS" BO_ 2550006542 0;
BA_ "VFrameFormat" BO_ 2550006542 15;
BA_ "GenMsgCycleTime" BO_ 986 100;
BA_ "GenMsgDelayTime" BO_ 986 10;
BA_ "GenMsgILSupport" BO_ 986 1;
BA_ "GenMsgSendType" BO_ 986 0;
BA_ "CANFD_BRS" BO_ 986 0;
BA_ "VFrameFormat" BO_ 986 14;
BA_ "GenMsgCycleTime" BO_ 988 50;
BA_ "GenMsgDelayTime" BO_ 988 10;
BA_ "GenMsgILSupport" BO_ 988 1;
BA_ "GenMsgSendType" BO_ 988 0;
BA_ "CANFD_BRS" BO_ 988 0;
BA_ "VFrameFormat" BO_ 988 14;
BA_ "GenMsgCycleTime" BO_ 1002 200;
BA_ "GenMsgDelayTime" BO_ 1002 20;
BA_ "GenMsgILSupport" BO_ 1002 1;
BA_ "GenMsgSendType" BO_ 1002 0;
BA_ "CANFD_BRS" BO_ 1002 0;
BA_ "VFrameFormat" BO_ 1002 14;
BA_ "GenMsgCycleTime" BO_ 1003 100;
BA_ "GenMsgDelayTime" BO_ 1003 50;
BA_ "GenMsgILSupport" BO_ 1003 1;
BA_ "GenMsgPDUConstants" BO_ 1003 "0x58,0xc7,0x6d,0xd6,0x2f,0x26,0xf7,0x3d,0x31,0x0c,0x75,0xdb,0x92,0x53,0x87,0x09";
BA_ "GenMsgSendType" BO_ 1003 0;
BA_ "CANFD_BRS" BO_ 1003 0;
BA_ "VFrameFormat" BO_ 1003 14;
BA_ "GenMsgCycleTime" BO_ 173 50;
BA_ "GenMsgILSupport" BO_ 173 1;
BA_ "GenMsgPDUConstants" BO_ 173 "0x3f,0x69,0x39,0xdc,0x94,0xf9,0x14,0x64,0xd8,0x6a,0x34,0xce,0xa2,0x55,0xb5,0x2c";
BA_ "GenMsgSendType" BO_ 173 0;
BA_ "CANFD_BRS" BO_ 173 0;
BA_ "VFrameFormat" BO_ 173 14;
BA_ "GenMsgCycleTime" BO_ 299 30;
BA_ "GenMsgILSupport" BO_ 299 1;
BA_ "GenMsgPDUConstants" BO_ 299 "0x6a,0x38,0xb4,0x27,0x22,0xef,0xe1,0xbb,0xf8,0x80,0x84,0x49,0xc7,0x9e,0x1e,0x2b";
BA_ "GenMsgSendType" BO_ 299 0;
BA_ "CANFD_BRS" BO_ 299 0;
BA_ "VFrameFormat" BO_ 299 14;
BA_ "GenMsgILSupport" BO_ 18 1;
BA_ "CANFD_BRS" BO_ 18 0;
BA_ "VFrameFormat" BO_ 18 14;
BA_ "GenMsgCycleTime" BO_ 1410 200;
BA_ "GenMsgDelayTime" BO_ 1410 20;
BA_ "GenMsgILSupport" BO_ 1410 1;
BA_ "GenMsgSendType" BO_ 1410 0;
BA_ "CANFD_BRS" BO_ 1410 0;
BA_ "VFrameFormat" BO_ 1410 14;
BA_ "GenMsgCycleTime" BO_ 588 50;
BA_ "GenMsgILSupport" BO_ 588 1;
BA_ "GenMsgSendType" BO_ 588 0;
BA_ "CANFD_BRS" BO_ 588 0;
BA_ "VFrameFormat" BO_ 588 14;
BA_ "GenMsgCycleTime" BO_ 1016 500;
BA_ "GenMsgDelayTime" BO_ 1016 50;
BA_ "GenMsgILSupport" BO_ 1016 1;
BA_ "GenMsgSendType" BO_ 1016 0;
BA_ "GenMsgStartDelayTime" BO_ 1016 70;
BA_ "CANFD_BRS" BO_ 1016 0;
BA_ "VFrameFormat" BO_ 1016 14;
BA_ "GenMsgCycleTime" BO_ 2527679731 500;
BA_ "GenMsgDelayTime" BO_ 2527679731 50;
BA_ "GenMsgILSupport" BO_ 2527679731 1;
BA_ "GenMsgSendType" BO_ 2527679731 0;
BA_ "CANFD_BRS" BO_ 2527679731 0;
BA_ "VFrameFormat" BO_ 2527679731 15;
BA_ "GenMsgCycleTime" BO_ 2527679730 500;
BA_ "GenMsgDelayTime" BO_ 2527679730 50;
BA_ "GenMsgILSupport" BO_ 2527679730 1;
BA_ "GenMsgSendType" BO_ 2527679730 0;
BA_ "CANFD_BRS" BO_ 2527679730 0;
BA_ "VFrameFormat" BO_ 2527679730 15;
BA_ "GenMsgCycleTime" BO_ 2527679732 500;
BA_ "GenMsgDelayTime" BO_ 2527679732 50;
BA_ "GenMsgILSupport" BO_ 2527679732 1;
BA_ "GenMsgSendType" BO_ 2527679732 0;
BA_ "CANFD_BRS" BO_ 2527679732 0;
BA_ "VFrameFormat" BO_ 2527679732 15;
BA_ "GenMsgCycleTime" BO_ 2527679733 500;
BA_ "GenMsgDelayTime" BO_ 2527679733 50;
BA_ "GenMsgILSupport" BO_ 2527679733 1;
BA_ "GenMsgSendType" BO_ 2527679733 0;
BA_ "CANFD_BRS" BO_ 2527679733 0;
BA_ "VFrameFormat" BO_ 2527679733 15;
BA_ "CANFD_BRS" BO_ 27 0;
BA_ "VFrameFormat" BO_ 27 14;
BA_ "GenMsgILSupport" BO_ 19 1;
BA_ "CANFD_BRS" BO_ 19 0;
BA_ "VFrameFormat" BO_ 19 14;
BA_ "GenMsgILSupport" BO_ 17 1;
BA_ "CANFD_BRS" BO_ 17 0;
BA_ "VFrameFormat" BO_ 17 14;
BA_ "GenMsgILSupport" BO_ 21 1;
BA_ "CANFD_BRS" BO_ 21 0;
BA_ "VFrameFormat" BO_ 21 14;
BA_ "GenMsgILSupport" BO_ 23 1;
BA_ "CANFD_BRS" BO_ 23 0;
BA_ "VFrameFormat" BO_ 23 14;
BA_ "GenMsgILSupport" BO_ 25 1;
BA_ "CANFD_BRS" BO_ 25 0;
BA_ "VFrameFormat" BO_ 25 14;
BA_ "CANFD_BRS" BO_ 29 0;
BA_ "VFrameFormat" BO_ 29 14;
BA_ "GenSigSendType" SG_ 885 ESC_54_BZ 0;
BA_ "GenSigFuncType" SG_ 885 ESC_54_BZ 1;
BA_ "GenSigSwitchedByIgnition" SG_ 885 ESC_54_BZ 0;
BA_ "GenSigSendType" SG_ 885 SOK_ESC_54_Signatur 0;
BA_ "GenSigFuncType" SG_ 885 SOK_ESC_54_Signatur 15;
BA_ "GenSigSwitchedByIgnition" SG_ 885 SOK_ESC_54_Signatur 0;
BA_ "GenSigSendType" SG_ 885 SSO_EdgeCount_Sum 0;
BA_ "GenSigSwitchedByIgnition" SG_ 885 SSO_EdgeCount_Sum 0;
BA_ "GenSigSendType" SG_ 278 ESP_10_BZ 0;
BA_ "GenSigFuncType" SG_ 278 ESP_10_BZ 1;
BA_ "GenSigSwitchedByIgnition" SG_ 278 ESP_10_BZ 0;
BA_ "GenSigSendType" SG_ 278 ESP_10_CRC 0;
BA_ "GenSigFuncType" SG_ 278 ESP_10_CRC 2;
BA_ "GenSigSwitchedByIgnition" SG_ 278 ESP_10_CRC 0;
BA_ "GenSigSendType" SG_ 278 ESP_HL_Fahrtrichtung 0;
BA_ "GenSigStartValue" SG_ 278 ESP_HL_Fahrtrichtung 2;
BA_ "GenSigSwitchedByIgnition" SG_ 278 ESP_HL_Fahrtrichtung 0;
BA_ "GenSigSendType" SG_ 278 ESP_HR_Fahrtrichtung 0;
BA_ "GenSigStartValue" SG_ 278 ESP_HR_Fahrtrichtung 2;
BA_ "GenSigSwitchedByIgnition" SG_ 278 ESP_HR_Fahrtrichtung 0;
BA_ "GenSigSendType" SG_ 278 ESP_QBit_Wegimpuls_HL 0;
BA_ "GenSigStartValue" SG_ 278 ESP_QBit_Wegimpuls_HL 1;
BA_ "GenSigSwitchedByIgnition" SG_ 278 ESP_QBit_Wegimpuls_HL 0;
BA_ "GenSigSendType" SG_ 278 ESP_QBit_Wegimpuls_HR 0;
BA_ "GenSigStartValue" SG_ 278 ESP_QBit_Wegimpuls_HR 1;
BA_ "GenSigSwitchedByIgnition" SG_ 278 ESP_QBit_Wegimpuls_HR 0;
BA_ "GenSigSendType" SG_ 278 ESP_QBit_Wegimpuls_VL 0;
BA_ "GenSigStartValue" SG_ 278 ESP_QBit_Wegimpuls_VL 1;
BA_ "GenSigSwitchedByIgnition" SG_ 278 ESP_QBit_Wegimpuls_VL 0;
BA_ "GenSigSendType" SG_ 278 ESP_QBit_Wegimpuls_VR 0;
BA_ "GenSigStartValue" SG_ 278 ESP_QBit_Wegimpuls_VR 1;
BA_ "GenSigSwitchedByIgnition" SG_ 278 ESP_QBit_Wegimpuls_VR 0;
BA_ "GenSigSendType" SG_ 278 ESP_VL_Fahrtrichtung 0;
BA_ "GenSigStartValue" SG_ 278 ESP_VL_Fahrtrichtung 2;
BA_ "GenSigSwitchedByIgnition" SG_ 278 ESP_VL_Fahrtrichtung 0;
BA_ "GenSigSendType" SG_ 278 ESP_VR_Fahrtrichtung 0;
BA_ "GenSigStartValue" SG_ 278 ESP_VR_Fahrtrichtung 2;
BA_ "GenSigSwitchedByIgnition" SG_ 278 ESP_VR_Fahrtrichtung 0;
BA_ "GenSigSendType" SG_ 278 ESP_Wegimpuls_HL 0;
BA_ "GenSigStartValue" SG_ 278 ESP_Wegimpuls_HL 1021;
BA_ "GenSigSwitchedByIgnition" SG_ 278 ESP_Wegimpuls_HL 0;
BA_ "Fehlerwert" SG_ 278 ESP_Wegimpuls_HL 1023;
BA_ "GenSigSendType" SG_ 278 ESP_Wegimpuls_HR 0;
BA_ "GenSigStartValue" SG_ 278 ESP_Wegimpuls_HR 1021;
BA_ "GenSigSwitchedByIgnition" SG_ 278 ESP_Wegimpuls_HR 0;
BA_ "Fehlerwert" SG_ 278 ESP_Wegimpuls_HR 1023;
BA_ "GenSigSendType" SG_ 278 ESP_Wegimpuls_VL 0;
BA_ "GenSigStartValue" SG_ 278 ESP_Wegimpuls_VL 1021;
BA_ "GenSigSwitchedByIgnition" SG_ 278 ESP_Wegimpuls_VL 0;
BA_ "Fehlerwert" SG_ 278 ESP_Wegimpuls_VL 1023;
BA_ "GenSigSendType" SG_ 278 ESP_Wegimpuls_VR 0;
BA_ "GenSigStartValue" SG_ 278 ESP_Wegimpuls_VR 1021;
BA_ "GenSigSwitchedByIgnition" SG_ 278 ESP_Wegimpuls_VR 0;
BA_ "Fehlerwert" SG_ 278 ESP_Wegimpuls_VR 1023;
BA_ "GenSigSendType" SG_ 178 ESP_HL_Radgeschw_02 0;
BA_ "GenSigStartValue" SG_ 178 ESP_HL_Radgeschw_02 65534;
BA_ "GenSigSwitchedByIgnition" SG_ 178 ESP_HL_Radgeschw_02 0;
BA_ "Fehlerwert" SG_ 178 ESP_HL_Radgeschw_02 65535;
BA_ "GenSigSendType" SG_ 178 ESP_HR_Radgeschw_02 0;
BA_ "GenSigStartValue" SG_ 178 ESP_HR_Radgeschw_02 65534;
BA_ "GenSigSwitchedByIgnition" SG_ 178 ESP_HR_Radgeschw_02 0;
BA_ "Fehlerwert" SG_ 178 ESP_HR_Radgeschw_02 65535;
BA_ "GenSigSendType" SG_ 178 ESP_VL_Radgeschw_02 0;
BA_ "GenSigStartValue" SG_ 178 ESP_VL_Radgeschw_02 65534;
BA_ "GenSigSwitchedByIgnition" SG_ 178 ESP_VL_Radgeschw_02 0;
BA_ "Fehlerwert" SG_ 178 ESP_VL_Radgeschw_02 65535;
BA_ "GenSigSendType" SG_ 178 ESP_VR_Radgeschw_02 0;
BA_ "GenSigStartValue" SG_ 178 ESP_VR_Radgeschw_02 65534;
BA_ "GenSigSwitchedByIgnition" SG_ 178 ESP_VR_Radgeschw_02 0;
BA_ "Fehlerwert" SG_ 178 ESP_VR_Radgeschw_02 65535;
BA_ "GenSigSendType" SG_ 1629 BR_QBit_Reifenumfang 0;
BA_ "GenSigStartValue" SG_ 1629 BR_QBit_Reifenumfang 1;
BA_ "GenSigSwitchedByIgnition" SG_ 1629 BR_QBit_Reifenumfang 0;
BA_ "GenSigSendType" SG_ 1629 BR_Reifenumfang 0;
BA_ "GenSigSwitchedByIgnition" SG_ 1629 BR_Reifenumfang 0;
BA_ "GenSigSendType" SG_ 1629 BR_Systemart 0;
BA_ "GenSigFuncType" SG_ 1629 BR_Systemart 8;
BA_ "GenSigSwitchedByIgnition" SG_ 1629 BR_Systemart 0;
BA_ "GenSigSendType" SG_ 1629 ESP_20_BZ 0;
BA_ "GenSigFuncType" SG_ 1629 ESP_20_BZ 1;
BA_ "GenSigSwitchedByIgnition" SG_ 1629 ESP_20_BZ 0;
BA_ "GenSigSendType" SG_ 1629 ESP_20_CRC 0;
BA_ "GenSigFuncType" SG_ 1629 ESP_20_CRC 2;
BA_ "GenSigSwitchedByIgnition" SG_ 1629 ESP_20_CRC 0;
BA_ "GenSigSendType" SG_ 1629 ESP_Charisma_FahrPr 3;
BA_ "GenSigSwitchedByIgnition" SG_ 1629 ESP_Charisma_FahrPr 0;
BA_ "GenSigSendType" SG_ 1629 ESP_Charisma_Status 3;
BA_ "GenSigSwitchedByIgnition" SG_ 1629 ESP_Charisma_Status 0;
BA_ "GenSigSendType" SG_ 1629 ESP_Dachrelingsensor 0;
BA_ "GenSigSwitchedByIgnition" SG_ 1629 ESP_Dachrelingsensor 0;
BA_ "Fehlerwert" SG_ 1629 ESP_Dachrelingsensor 3;
BA_ "GenSigSendType" SG_ 1629 ESP_SpannungsAnf_02 3;
BA_ "GenSigSwitchedByIgnition" SG_ 1629 ESP_SpannungsAnf_02 0;
BA_ "GenSigSendType" SG_ 1629 ESP_Stoppverbot_Anz_01 3;
BA_ "GenSigSwitchedByIgnition" SG_ 1629 ESP_Stoppverbot_Anz_01 0;
BA_ "GenSigSendType" SG_ 1629 ESP_Stoppverbot_Anz_02 3;
BA_ "GenSigSwitchedByIgnition" SG_ 1629 ESP_Stoppverbot_Anz_02 0;
BA_ "GenSigSendType" SG_ 1629 ESP_Stoppverbot_Anz_03 3;
BA_ "GenSigSwitchedByIgnition" SG_ 1629 ESP_Stoppverbot_Anz_03 0;
BA_ "GenSigSendType" SG_ 1629 ESP_Stoppverbot_Anz_04 3;
BA_ "GenSigSwitchedByIgnition" SG_ 1629 ESP_Stoppverbot_Anz_04 0;
BA_ "GenSigSendType" SG_ 1629 ESP_Stoppverbot_Anz_05 3;
BA_ "GenSigSwitchedByIgnition" SG_ 1629 ESP_Stoppverbot_Anz_05 0;
BA_ "GenSigSendType" SG_ 1629 ESP_Stoppverbot_Anz_06 3;
BA_ "GenSigSwitchedByIgnition" SG_ 1629 ESP_Stoppverbot_Anz_06 0;
BA_ "GenSigSendType" SG_ 1629 ESP_Stoppverbot_Anz_07 3;
BA_ "GenSigSwitchedByIgnition" SG_ 1629 ESP_Stoppverbot_Anz_07 0;
BA_ "GenSigSendType" SG_ 1629 ESP_Stoppverbot_Anz_08 3;
BA_ "GenSigSwitchedByIgnition" SG_ 1629 ESP_Stoppverbot_Anz_08 0;
BA_ "GenSigSendType" SG_ 1629 ESP_Stoppverbot_Anz_Std 3;
BA_ "GenSigSwitchedByIgnition" SG_ 1629 ESP_Stoppverbot_Anz_Std 0;
BA_ "GenSigSendType" SG_ 1629 ESP_Wiederstart_Anz_01 3;
BA_ "GenSigSwitchedByIgnition" SG_ 1629 ESP_Wiederstart_Anz_01 0;
BA_ "GenSigSendType" SG_ 1629 ESP_Wiederstart_Anz_02 3;
BA_ "GenSigSwitchedByIgnition" SG_ 1629 ESP_Wiederstart_Anz_02 0;
BA_ "GenSigSendType" SG_ 1629 ESP_Wiederstart_Anz_03 3;
BA_ "GenSigSwitchedByIgnition" SG_ 1629 ESP_Wiederstart_Anz_03 0;
BA_ "GenSigSendType" SG_ 1629 ESP_Wiederstart_Anz_04 3;
BA_ "GenSigSwitchedByIgnition" SG_ 1629 ESP_Wiederstart_Anz_04 0;
BA_ "GenSigSendType" SG_ 1629 ESP_Zaehnezahl 0;
BA_ "GenSigFuncType" SG_ 1629 ESP_Zaehnezahl 8;
BA_ "GenSigSwitchedByIgnition" SG_ 1629 ESP_Zaehnezahl 0;
BA_ "GenSigSendType" SG_ 1629 HDC_Charisma_FahrPr 3;
BA_ "GenSigSwitchedByIgnition" SG_ 1629 HDC_Charisma_FahrPr 0;
BA_ "GenSigSendType" SG_ 1629 HDC_Charisma_Status 3;
BA_ "GenSigSwitchedByIgnition" SG_ 1629 HDC_Charisma_Status 0;
BA_ "GenSigSendType" SG_ 253 ABS_Bremsung 0;
BA_ "GenSigSwitchedByIgnition" SG_ 253 ABS_Bremsung 0;
BA_ "GenSigSendType" SG_ 253 ASR_Anf 0;
BA_ "GenSigSwitchedByIgnition" SG_ 253 ASR_Anf 0;
BA_ "GenSigSendType" SG_ 253 ASR_Schalteingriff 0;
BA_ "GenSigSwitchedByIgnition" SG_ 253 ASR_Schalteingriff 0;
BA_ "GenSigSendType" SG_ 253 ASR_Tastung_passiv 0;
BA_ "GenSigSwitchedByIgnition" SG_ 253 ASR_Tastung_passiv 0;
BA_ "GenSigSendType" SG_ 253 BR_Eingriffsmoment 0;
BA_ "GenSigStartValue" SG_ 253 BR_Eingriffsmoment 1022;
BA_ "GenSigSwitchedByIgnition" SG_ 253 BR_Eingriffsmoment 0;
BA_ "Fehlerwert" SG_ 253 BR_Eingriffsmoment 1023;
BA_ "GenSigSendType" SG_ 253 EBV_Eingriff 0;
BA_ "GenSigSwitchedByIgnition" SG_ 253 EBV_Eingriff 0;
BA_ "GenSigSendType" SG_ 253 EDS_Eingriff 0;
BA_ "GenSigSwitchedByIgnition" SG_ 253 EDS_Eingriff 0;
BA_ "GenSigSendType" SG_ 253 ESC_Reku_Freigabe 0;
BA_ "GenSigSwitchedByIgnition" SG_ 253 ESC_Reku_Freigabe 0;
BA_ "GenSigSendType" SG_ 253 ESC_v_Signal_Qualifier_High_Low 0;
BA_ "GenSigStartValue" SG_ 253 ESC_v_Signal_Qualifier_High_Low 6;
BA_ "GenSigSwitchedByIgnition" SG_ 253 ESC_v_Signal_Qualifier_High_Low 0;
BA_ "Fehlerwert" SG_ 253 ESC_v_Signal_Qualifier_High_Low 7;
BA_ "GenSigSendType" SG_ 253 ESP_21_BZ 0;
BA_ "GenSigFuncType" SG_ 253 ESP_21_BZ 1;
BA_ "GenSigSwitchedByIgnition" SG_ 253 ESP_21_BZ 0;
BA_ "GenSigSendType" SG_ 253 ESP_21_CRC 0;
BA_ "GenSigFuncType" SG_ 253 ESP_21_CRC 2;
BA_ "GenSigSwitchedByIgnition" SG_ 253 ESP_21_CRC 0;
BA_ "GenSigSendType" SG_ 253 ESP_Anhaltevorgang_ACC_aktiv 0;
BA_ "GenSigSwitchedByIgnition" SG_ 253 ESP_Anhaltevorgang_ACC_aktiv 0;
BA_ "GenSigSendType" SG_ 253 ESP_ASP 0;
BA_ "GenSigSwitchedByIgnition" SG_ 253 ESP_ASP 0;
BA_ "GenSigSendType" SG_ 253 ESP_AWV3_Brems_aktiv 0;
BA_ "GenSigSwitchedByIgnition" SG_ 253 ESP_AWV3_Brems_aktiv 0;
BA_ "GenSigSendType" SG_ 253 ESP_Diagnose 0;
BA_ "GenSigSwitchedByIgnition" SG_ 253 ESP_Diagnose 0;
BA_ "GenSigSendType" SG_ 253 ESP_Eingriff 0;
BA_ "GenSigSwitchedByIgnition" SG_ 253 ESP_Eingriff 0;
BA_ "GenSigSendType" SG_ 253 ESP_Haltebestaetigung 0;
BA_ "GenSigSwitchedByIgnition" SG_ 253 ESP_Haltebestaetigung 0;
BA_ "GenSigSendType" SG_ 253 ESP_MKB_Abbruch_Geschw 0;
BA_ "GenSigSwitchedByIgnition" SG_ 253 ESP_MKB_Abbruch_Geschw 0;
BA_ "GenSigSendType" SG_ 253 ESP_PLA_Bremseingriff 0;
BA_ "GenSigSwitchedByIgnition" SG_ 253 ESP_PLA_Bremseingriff 0;
BA_ "GenSigSendType" SG_ 253 ESP_QBit_v_Signal 0;
BA_ "GenSigStartValue" SG_ 253 ESP_QBit_v_Signal 1;
BA_ "GenSigSwitchedByIgnition" SG_ 253 ESP_QBit_v_Signal 0;
BA_ "GenSigSendType" SG_ 253 ESP_Systemstatus 0;
BA_ "GenSigSwitchedByIgnition" SG_ 253 ESP_Systemstatus 0;
BA_ "GenSigSendType" SG_ 253 ESP_Tastung_passiv 0;
BA_ "GenSigSwitchedByIgnition" SG_ 253 ESP_Tastung_passiv 0;
BA_ "GenSigSendType" SG_ 253 ESP_v_Signal 0;
BA_ "GenSigStartValue" SG_ 253 ESP_v_Signal 65534;
BA_ "GenSigSwitchedByIgnition" SG_ 253 ESP_v_Signal 0;
BA_ "Fehlerwert" SG_ 253 ESP_v_Signal 65535;
BA_ "GenSigMissingSourceValue" SG_ 253 ESP_v_Signal 65534;
BA_ "GenSigSendType" SG_ 253 ESP_Vorsteuerung 0;
BA_ "GenSigSwitchedByIgnition" SG_ 253 ESP_Vorsteuerung 0;
BA_ "GenSigSendType" SG_ 253 MSR_Anf 0;
BA_ "GenSigSwitchedByIgnition" SG_ 253 MSR_Anf 0;
BA_ "GenSigSendType" SG_ 253 OBD_QBit_Schlechtweg 0;
BA_ "GenSigStartValue" SG_ 253 OBD_QBit_Schlechtweg 1;
BA_ "GenSigSwitchedByIgnition" SG_ 253 OBD_QBit_Schlechtweg 0;
BA_ "GenSigSendType" SG_ 253 OBD_Schlechtweg 0;
BA_ "GenSigSwitchedByIgnition" SG_ 253 OBD_Schlechtweg 0;
BA_ "GenSigSendType" SG_ 795 ABS_Lampe 0;
BA_ "GenSigStartValue" SG_ 795 ABS_Lampe 1;
BA_ "GenSigSwitchedByIgnition" SG_ 795 ABS_Lampe 0;
BA_ "GenSigSendType" SG_ 795 BK_Lampe_02 0;
BA_ "GenSigStartValue" SG_ 795 BK_Lampe_02 1;
BA_ "GenSigSwitchedByIgnition" SG_ 795 BK_Lampe_02 0;
BA_ "GenSigSendType" SG_ 795 ESP_24_BZ 0;
BA_ "GenSigFuncType" SG_ 795 ESP_24_BZ 1;
BA_ "GenSigSwitchedByIgnition" SG_ 795 ESP_24_BZ 0;
BA_ "GenSigSendType" SG_ 795 ESP_24_CRC 0;
BA_ "GenSigFuncType" SG_ 795 ESP_24_CRC 2;
BA_ "GenSigSwitchedByIgnition" SG_ 795 ESP_24_CRC 0;
BA_ "GenSigSendType" SG_ 795 ESP_BKV_Warnung 0;
BA_ "GenSigSwitchedByIgnition" SG_ 795 ESP_BKV_Warnung 0;
BA_ "GenSigSendType" SG_ 795 ESP_Fehlerstatus_Wegimp 0;
BA_ "GenSigSwitchedByIgnition" SG_ 795 ESP_Fehlerstatus_Wegimp 0;
BA_ "GenSigSendType" SG_ 795 ESP_HDC_FktLampe 0;
BA_ "GenSigSwitchedByIgnition" SG_ 795 ESP_HDC_FktLampe 0;
BA_ "GenSigSendType" SG_ 795 ESP_HDC_Regelgeschw 0;
BA_ "GenSigStartValue" SG_ 795 ESP_HDC_Regelgeschw 126;
BA_ "GenSigSwitchedByIgnition" SG_ 795 ESP_HDC_Regelgeschw 0;
BA_ "Fehlerwert" SG_ 795 ESP_HDC_Regelgeschw 127;
BA_ "GenSigSendType" SG_ 795 ESP_Lampe 0;
BA_ "GenSigSwitchedByIgnition" SG_ 795 ESP_Lampe 0;
BA_ "GenSigSendType" SG_ 795 ESP_m_Raddrehz 0;
BA_ "GenSigStartValue" SG_ 795 ESP_m_Raddrehz 32766;
BA_ "GenSigSwitchedByIgnition" SG_ 795 ESP_m_Raddrehz 0;
BA_ "Fehlerwert" SG_ 795 ESP_m_Raddrehz 32767;
BA_ "GenSigSendType" SG_ 795 ESP_Meldungen 0;
BA_ "GenSigSwitchedByIgnition" SG_ 795 ESP_Meldungen 0;
BA_ "GenSigSendType" SG_ 795 ESP_Off_Lampe 0;
BA_ "GenSigSwitchedByIgnition" SG_ 795 ESP_Off_Lampe 0;
BA_ "GenSigSendType" SG_ 795 ESP_QBit_Wegimp_VA 0;
BA_ "GenSigStartValue" SG_ 795 ESP_QBit_Wegimp_VA 1;
BA_ "GenSigSwitchedByIgnition" SG_ 795 ESP_QBit_Wegimp_VA 0;
BA_ "GenSigSendType" SG_ 795 ESP_Textanzeigen_03 0;
BA_ "GenSigSwitchedByIgnition" SG_ 795 ESP_Textanzeigen_03 0;
BA_ "GenSigSendType" SG_ 795 ESP_Wegimp_Ueberlauf 0;
BA_ "GenSigSwitchedByIgnition" SG_ 795 ESP_Wegimp_Ueberlauf 0;
BA_ "GenSigSendType" SG_ 795 ESP_Wegimp_VA 0;
BA_ "GenSigSwitchedByIgnition" SG_ 795 ESP_Wegimp_VA 0;
BA_ "GenSigSendType" SG_ 795 TC_Lampe 0;
BA_ "GenSigSwitchedByIgnition" SG_ 795 TC_Lampe 0;
BA_ "GenSigSendType" SG_ 2463978794 FBS_Anf_Access_Auth 0;
BA_ "GenSigSwitchedByIgnition" SG_ 2463978794 FBS_Anf_Access_Auth 0;
BA_ "GenSigSendType" SG_ 2463978794 FBS_Anf_Start_Auth 0;
BA_ "GenSigSwitchedByIgnition" SG_ 2463978794 FBS_Anf_Start_Auth 0;
BA_ "GenSigSendType" SG_ 2463978794 FBS_MDK_button 4;
BA_ "GenSigSwitchedByIgnition" SG_ 2463978794 FBS_MDK_button 0;
BA_ "GenSigSendType" SG_ 2463978794 FBS_MDK_in_Reichweite 4;
BA_ "GenSigSwitchedByIgnition" SG_ 2463978794 FBS_MDK_in_Reichweite 0;
BA_ "GenSigSendType" SG_ 2463978794 WLC_laden_unterbrechen 0;
BA_ "GenSigSwitchedByIgnition" SG_ 2463978794 WLC_laden_unterbrechen 0;
BA_ "GenSigSendType" SG_ 2527679800 FBS_MKGO_01 1;
BA_ "GenSigSwitchedByIgnition" SG_ 2527679800 FBS_MKGO_01 0;
BA_ "GenSigSendType" SG_ 2527679801 FBS_MKGO_02 1;
BA_ "GenSigSwitchedByIgnition" SG_ 2527679801 FBS_MKGO_02 0;
BA_ "GenSigSendType" SG_ 2527679802 FBS_MKGO_03 1;
BA_ "GenSigSwitchedByIgnition" SG_ 2527679802 FBS_MKGO_03 0;
BA_ "GenSigSendType" SG_ 2527679803 FBS_MKGO_04 1;
BA_ "GenSigSwitchedByIgnition" SG_ 2527679803 FBS_MKGO_04 0;
BA_ "GenSigSendType" SG_ 2527679804 FBS_MKGO_05 1;
BA_ "GenSigSwitchedByIgnition" SG_ 2527679804 FBS_MKGO_05 0;
BA_ "GenSigSendType" SG_ 1605 FLA_Abblendursache 3;
BA_ "Fehlerwert" SG_ 1605 FLA_Abblendursache 255;
BA_ "GenSigSendType" SG_ 1605 FLA_aktiv 3;
BA_ "GenSigSendType" SG_ 1605 FLA_Aufblenden 3;
BA_ "GenSigSendType" SG_ 1605 FLA_Fernlicht_PWM 3;
BA_ "Fehlerwert" SG_ 1605 FLA_Fernlicht_PWM 127;
BA_ "GenSigSendType" SG_ 1605 FLA_ISP_defekt 3;
BA_ "GenSigSendType" SG_ 1605 FLA_SAE_Mode 3;
BA_ "GenSigSendType" SG_ 1605 FLA_Sensor_blockiert 3;
BA_ "GenSigSendType" SG_ 1605 ISP_EC_aktiv 3;
BA_ "GenSigStartValue" SG_ 1605 ISP_EC_aktiv 1;
BA_ "GenSigSendType" SG_ 1605 ISP_EC_Lichtwert_hinten 3;
BA_ "GenSigStartValue" SG_ 1605 ISP_EC_Lichtwert_hinten 62;
BA_ "Fehlerwert" SG_ 1605 ISP_EC_Lichtwert_hinten 63;
BA_ "GenSigSendType" SG_ 1605 ISP_EC_Lichtwert_vorne 3;
BA_ "GenSigStartValue" SG_ 1605 ISP_EC_Lichtwert_vorne 62;
BA_ "Fehlerwert" SG_ 1605 ISP_EC_Lichtwert_vorne 63;
BA_ "GenSigSendType" SG_ 1605 ISP_Himmelsrichtung 3;
BA_ "GenSigStartValue" SG_ 1605 ISP_Himmelsrichtung 30;
BA_ "Fehlerwert" SG_ 1605 ISP_Himmelsrichtung 31;
BA_ "GenSigSendType" SG_ 1605 ISP_Kompass_aktiv 3;
BA_ "GenSigStartValue" SG_ 1605 ISP_Kompass_aktiv 1;
BA_ "GenSigSendType" SG_ 1605 ISP_Taste_betaetigt 3;
BA_ "GenSigSendType" SG_ 2589283684 FoD_Transmission_Info 3;
BA_ "GenSigSwitchedByIgnition" SG_ 2589283684 FoD_Transmission_Info 0;
BA_ "GenSigSendType" SG_ 2589283684 GRA_FoD_Status 4;
BA_ "GenSigSwitchedByIgnition" SG_ 2589283684 GRA_FoD_Status 0;
BA_ "GenSigSendType" SG_ 2549875470 FoD_BCM1_Req_Data 3;
BA_ "GenSigFuncType" SG_ 2549875470 FoD_BCM1_Req_Data 9;
BA_ "GenSigSwitchedByIgnition" SG_ 2549875470 FoD_BCM1_Req_Data 0;
BA_ "GenSigSendType" SG_ 2550006542 FoD_BCM1_Resp_Data 3;
BA_ "GenSigFuncType" SG_ 2550006542 FoD_BCM1_Resp_Data 9;
BA_ "GenSigSwitchedByIgnition" SG_ 2550006542 FoD_BCM1_Resp_Data 0;
BA_ "GenSigSendType" SG_ 986 ABS_Bremsung 0;
BA_ "GenSigSwitchedByIgnition" SG_ 986 ABS_Bremsung 0;
BA_ "GenSigSendType" SG_ 986 ECD_Bremslicht 3;
BA_ "GenSigSwitchedByIgnition" SG_ 986 ECD_Bremslicht 0;
BA_ "GenSigSendType" SG_ 986 EPB_01_alt 0;
BA_ "GenSigStartValue" SG_ 986 EPB_01_alt 1;
BA_ "GenSigFuncType" SG_ 986 EPB_01_alt 5;
BA_ "GenSigSwitchedByIgnition" SG_ 986 EPB_01_alt 0;
BA_ "GenSigSendType" SG_ 986 EPB_Pedalweg_Kuppl 0;
BA_ "GenSigSwitchedByIgnition" SG_ 986 EPB_Pedalweg_Kuppl 0;
BA_ "Fehlerwert" SG_ 986 EPB_Pedalweg_Kuppl 255;
BA_ "GenSigSendType" SG_ 986 EPB_QBit_Pedalweg_Kuppl 0;
BA_ "GenSigStartValue" SG_ 986 EPB_QBit_Pedalweg_Kuppl 1;
BA_ "GenSigSwitchedByIgnition" SG_ 986 EPB_QBit_Pedalweg_Kuppl 0;
BA_ "GenSigSendType" SG_ 986 EPB_Status 0;
BA_ "GenSigSwitchedByIgnition" SG_ 986 EPB_Status 0;
BA_ "GenSigSendType" SG_ 986 ESP_05_alt 0;
BA_ "GenSigStartValue" SG_ 986 ESP_05_alt 1;
BA_ "GenSigFuncType" SG_ 986 ESP_05_alt 5;
BA_ "GenSigSwitchedByIgnition" SG_ 986 ESP_05_alt 0;
BA_ "GenSigSendType" SG_ 986 ESP_21_alt 0;
BA_ "GenSigStartValue" SG_ 986 ESP_21_alt 1;
BA_ "GenSigFuncType" SG_ 986 ESP_21_alt 5;
BA_ "GenSigSwitchedByIgnition" SG_ 986 ESP_21_alt 0;
BA_ "GenSigSendType" SG_ 986 ESP_Eingriff 0;
BA_ "GenSigSwitchedByIgnition" SG_ 986 ESP_Eingriff 0;
BA_ "GenSigSendType" SG_ 986 ESP_HDC_Standby 0;
BA_ "GenSigSwitchedByIgnition" SG_ 986 ESP_HDC_Standby 0;
BA_ "GenSigSendType" SG_ 986 ESP_MKB_Abbruch_Geschw 3;
BA_ "GenSigSwitchedByIgnition" SG_ 986 ESP_MKB_Abbruch_Geschw 0;
BA_ "GenSigSendType" SG_ 986 ESP_QBit_v_Signal 0;
BA_ "GenSigStartValue" SG_ 986 ESP_QBit_v_Signal 1;
BA_ "GenSigSwitchedByIgnition" SG_ 986 ESP_QBit_v_Signal 0;
BA_ "GenSigSendType" SG_ 986 ESP_v_Signal 0;
BA_ "GenSigStartValue" SG_ 986 ESP_v_Signal 65534;
BA_ "GenSigSwitchedByIgnition" SG_ 986 ESP_v_Signal 0;
BA_ "Fehlerwert" SG_ 986 ESP_v_Signal 65535;
BA_ "GenSigMissingSourceValue" SG_ 986 ESP_v_Signal 65534;
BA_ "GenSigSendType" SG_ 986 Kamera_FSH_aktiv 0;
BA_ "GenSigSendType" SG_ 986 Kamera_Status_alt 0;
BA_ "GenSigStartValue" SG_ 986 Kamera_Status_alt 1;
BA_ "GenSigFuncType" SG_ 986 Kamera_Status_alt 5;
BA_ "GenSigSwitchedByIgnition" SG_ 986 Kamera_Status_alt 0;
BA_ "GenSigSendType" SG_ 986 LWI_01_alt 0;
BA_ "GenSigStartValue" SG_ 986 LWI_01_alt 1;
BA_ "GenSigFuncType" SG_ 986 LWI_01_alt 5;
BA_ "GenSigSwitchedByIgnition" SG_ 986 LWI_01_alt 0;
BA_ "GenSigSendType" SG_ 986 LWI_Lenkradwinkel 0;
BA_ "GenSigStartValue" SG_ 986 LWI_Lenkradwinkel 8190;
BA_ "Fehlerwert" SG_ 986 LWI_Lenkradwinkel 8191;
BA_ "GenSigSendType" SG_ 986 LWI_QBit_Lenkradwinkel 0;
BA_ "GenSigStartValue" SG_ 986 LWI_QBit_Lenkradwinkel 1;
BA_ "GenSigSendType" SG_ 986 LWI_Sensorstatus 0;
BA_ "GenSigSendType" SG_ 986 LWI_VZ_Lenkradwinkel 0;
BA_ "GenSigSendType" SG_ 986 Parkhilfe_01_alt 0;
BA_ "GenSigStartValue" SG_ 986 Parkhilfe_01_alt 1;
BA_ "GenSigFuncType" SG_ 986 Parkhilfe_01_alt 5;
BA_ "GenSigSwitchedByIgnition" SG_ 986 Parkhilfe_01_alt 0;
BA_ "GenSigSendType" SG_ 986 PH_Anf_Audioabsenkung 0;
BA_ "GenSigSendType" SG_ 986 PH_Systemzustand 0;
BA_ "GenSigSendType" SG_ 986 PH_Taster 3;
BA_ "Fehlerwert" SG_ 986 PH_Taster 3;
BA_ "GenSigSendType" SG_ 986 PLA_Anf_Aufschaltung_RVC 3;
BA_ "GenSigSendType" SG_ 988 ACC_18_alt 0;
BA_ "GenSigStartValue" SG_ 988 ACC_18_alt 1;
BA_ "GenSigFuncType" SG_ 988 ACC_18_alt 5;
BA_ "GenSigSwitchedByIgnition" SG_ 988 ACC_18_alt 0;
BA_ "GenSigSendType" SG_ 988 ACC_Status_ACC 0;
BA_ "GenSigSendType" SG_ 988 Bel_DiETa_Mode2 3;
BA_ "GenSigSwitchedByIgnition" SG_ 988 Bel_DiETa_Mode2 0;
BA_ "Fehlerwert" SG_ 988 Bel_DiETa_Mode2 3;
BA_ "GenSigSendType" SG_ 988 EPB_Schalterposition 0;
BA_ "GenSigSwitchedByIgnition" SG_ 988 EPB_Schalterposition 0;
BA_ "Fehlerwert" SG_ 988 EPB_Schalterposition 3;
BA_ "GenSigSendType" SG_ 988 EPB_Status_02 0;
BA_ "GenSigStartValue" SG_ 988 EPB_Status_02 6;
BA_ "GenSigSwitchedByIgnition" SG_ 988 EPB_Status_02 0;
BA_ "GenSigSendType" SG_ 988 ESP_07_alt 0;
BA_ "GenSigStartValue" SG_ 988 ESP_07_alt 1;
BA_ "GenSigFuncType" SG_ 988 ESP_07_alt 5;
BA_ "GenSigSwitchedByIgnition" SG_ 988 ESP_07_alt 0;
BA_ "GenSigSendType" SG_ 988 ESP_50_alt 0;
BA_ "GenSigStartValue" SG_ 988 ESP_50_alt 1;
BA_ "GenSigFuncType" SG_ 988 ESP_50_alt 5;
BA_ "GenSigSwitchedByIgnition" SG_ 988 ESP_50_alt 0;
BA_ "GenSigSendType" SG_ 988 ESP_Rollenmodus_Deaktivieren 0;
BA_ "GenSigSwitchedByIgnition" SG_ 988 ESP_Rollenmodus_Deaktivieren 0;
BA_ "GenSigSendType" SG_ 988 GE_Fahrstufe 3;
BA_ "GenSigStartValue" SG_ 988 GE_Fahrstufe 1;
BA_ "GenSigSwitchedByIgnition" SG_ 988 GE_Fahrstufe 0;
BA_ "Fehlerwert" SG_ 988 GE_Fahrstufe 15;
BA_ "GenSigSendType" SG_ 988 GE_Freilauf_Status 0;
BA_ "GenSigSwitchedByIgnition" SG_ 988 GE_Freilauf_Status 0;
BA_ "Fehlerwert" SG_ 988 GE_Freilauf_Status 7;
BA_ "GenSigSendType" SG_ 988 GE_LaunchControl 3;
BA_ "GenSigSwitchedByIgnition" SG_ 988 GE_LaunchControl 0;
BA_ "GenSigSendType" SG_ 988 GE_Notlauf 3;
BA_ "GenSigSwitchedByIgnition" SG_ 988 GE_Notlauf 0;
BA_ "GenSigSendType" SG_ 988 GE_Sperr_Info_WFS 3;
BA_ "GenSigSwitchedByIgnition" SG_ 988 GE_Sperr_Info_WFS 0;
BA_ "GenSigSendType" SG_ 988 GE_Ursache_Fahrstufe_N 0;
BA_ "GenSigSwitchedByIgnition" SG_ 988 GE_Ursache_Fahrstufe_N 0;
BA_ "GenSigSendType" SG_ 988 GE_Veto_Rollfaehigkeit 0;
BA_ "GenSigSwitchedByIgnition" SG_ 988 GE_Veto_Rollfaehigkeit 0;
BA_ "GenSigSendType" SG_ 988 Getriebe_11_alt 0;
BA_ "GenSigStartValue" SG_ 988 Getriebe_11_alt 1;
BA_ "GenSigFuncType" SG_ 988 Getriebe_11_alt 5;
BA_ "GenSigSwitchedByIgnition" SG_ 988 Getriebe_11_alt 0;
BA_ "GenSigSendType" SG_ 988 Getriebe_13_alt 0;
BA_ "GenSigStartValue" SG_ 988 Getriebe_13_alt 1;
BA_ "GenSigFuncType" SG_ 988 Getriebe_13_alt 5;
BA_ "GenSigSwitchedByIgnition" SG_ 988 Getriebe_13_alt 0;
BA_ "GenSigSendType" SG_ 988 Getriebe_14_alt 0;
BA_ "GenSigStartValue" SG_ 988 Getriebe_14_alt 1;
BA_ "GenSigFuncType" SG_ 988 Getriebe_14_alt 5;
BA_ "GenSigSwitchedByIgnition" SG_ 988 Getriebe_14_alt 0;
BA_ "GenSigSendType" SG_ 988 Getriebe_17_alt 0;
BA_ "GenSigStartValue" SG_ 988 Getriebe_17_alt 1;
BA_ "GenSigFuncType" SG_ 988 Getriebe_17_alt 5;
BA_ "GenSigSwitchedByIgnition" SG_ 988 Getriebe_17_alt 0;
BA_ "GenSigSendType" SG_ 988 MKE_Stufe 0;
BA_ "GenSigSwitchedByIgnition" SG_ 988 MKE_Stufe 0;
BA_ "GenSigSendType" SG_ 988 MKE_Texte 0;
BA_ "GenSigSwitchedByIgnition" SG_ 988 MKE_Texte 0;
BA_ "GenSigSendType" SG_ 988 MO_Drehzahl_01 0;
BA_ "GenSigSwitchedByIgnition" SG_ 988 MO_Drehzahl_01 0;
BA_ "GenSigSendType" SG_ 988 MO_QBit_Drehzahl_01 0;
BA_ "GenSigStartValue" SG_ 988 MO_QBit_Drehzahl_01 1;
BA_ "GenSigSwitchedByIgnition" SG_ 988 MO_QBit_Drehzahl_01 0;
BA_ "GenSigSendType" SG_ 988 Motor_12_alt 0;
BA_ "GenSigStartValue" SG_ 988 Motor_12_alt 1;
BA_ "GenSigFuncType" SG_ 988 Motor_12_alt 5;
BA_ "GenSigSwitchedByIgnition" SG_ 988 Motor_12_alt 0;
BA_ "GenSigSendType" SG_ 988 TSK_06_alt 0;
BA_ "GenSigStartValue" SG_ 988 TSK_06_alt 1;
BA_ "GenSigSwitchedByIgnition" SG_ 988 TSK_06_alt 0;
BA_ "GenSigSendType" SG_ 988 TSK_Hauptschalter_GRA_ACC 0;
BA_ "GenSigSwitchedByIgnition" SG_ 988 TSK_Hauptschalter_GRA_ACC 0;
BA_ "Fehlerwert" SG_ 988 TSK_Hauptschalter_GRA_ACC 3;
BA_ "GenSigSendType" SG_ 988 TSK_Limiter_ausgewaehlt 0;
BA_ "GenSigSwitchedByIgnition" SG_ 988 TSK_Limiter_ausgewaehlt 0;
BA_ "GenSigSendType" SG_ 988 TSK_Status 0;
BA_ "GenSigStartValue" SG_ 988 TSK_Status 1;
BA_ "GenSigSwitchedByIgnition" SG_ 988 TSK_Status 0;
BA_ "GenSigSendType" SG_ 1002 AWV_03_alt 0;
BA_ "GenSigStartValue" SG_ 1002 AWV_03_alt 1;
BA_ "GenSigFuncType" SG_ 1002 AWV_03_alt 5;
BA_ "GenSigSwitchedByIgnition" SG_ 1002 AWV_03_alt 0;
BA_ "GenSigSendType" SG_ 1002 AWV_Verz_Anf 3;
BA_ "GenSigStartValue" SG_ 1002 AWV_Verz_Anf 1023;
BA_ "GenSigSendType" SG_ 1002 AWV_Verz_Freigabe 3;
BA_ "GenSigSendType" SG_ 1002 AWV_Zielobjekttyp 3;
BA_ "GenSigStartValue" SG_ 1002 AWV_Zielobjekttyp 15;
BA_ "GenSigSendType" SG_ 1002 Bel_DiETa_Mode 3;
BA_ "GenSigSwitchedByIgnition" SG_ 1002 Bel_DiETa_Mode 0;
BA_ "Fehlerwert" SG_ 1002 Bel_DiETa_Mode 3;
BA_ "GenSigSendType" SG_ 1002 EBKV_03_alt 0;
BA_ "GenSigStartValue" SG_ 1002 EBKV_03_alt 1;
BA_ "GenSigFuncType" SG_ 1002 EBKV_03_alt 5;
BA_ "GenSigSwitchedByIgnition" SG_ 1002 EBKV_03_alt 0;
BA_ "GenSigSendType" SG_ 1002 EBKV_Fahrer_bremst 3;
BA_ "GenSigSwitchedByIgnition" SG_ 1002 EBKV_Fahrer_bremst 0;
BA_ "GenSigSendType" SG_ 1002 ESP_05_alt 0;
BA_ "GenSigStartValue" SG_ 1002 ESP_05_alt 1;
BA_ "GenSigFuncType" SG_ 1002 ESP_05_alt 5;
BA_ "GenSigSwitchedByIgnition" SG_ 1002 ESP_05_alt 0;
BA_ "GenSigSendType" SG_ 1002 ESP_Bremsdruck 0;
BA_ "GenSigStartValue" SG_ 1002 ESP_Bremsdruck 100;
BA_ "GenSigSwitchedByIgnition" SG_ 1002 ESP_Bremsdruck 0;
BA_ "Fehlerwert" SG_ 1002 ESP_Bremsdruck 1023;
BA_ "GenSigSendType" SG_ 1002 GE_Sumpftemperatur 0;
BA_ "GenSigSwitchedByIgnition" SG_ 1002 GE_Sumpftemperatur 0;
BA_ "Fehlerwert" SG_ 1002 GE_Sumpftemperatur 255;
BA_ "GenSigSendType" SG_ 1002 Getriebe_14_alt 0;
BA_ "GenSigStartValue" SG_ 1002 Getriebe_14_alt 1;
BA_ "GenSigFuncType" SG_ 1002 Getriebe_14_alt 5;
BA_ "GenSigSwitchedByIgnition" SG_ 1002 Getriebe_14_alt 0;
BA_ "GenSigSendType" SG_ 1002 MO_Fahrpedalrohwert_01 0;
BA_ "GenSigSwitchedByIgnition" SG_ 1002 MO_Fahrpedalrohwert_01 0;
BA_ "Fehlerwert" SG_ 1002 MO_Fahrpedalrohwert_01 255;
BA_ "GenSigSendType" SG_ 1002 MO_Mom_Ist_Summe 0;
BA_ "GenSigStartValue" SG_ 1002 MO_Mom_Ist_Summe 1022;
BA_ "GenSigSwitchedByIgnition" SG_ 1002 MO_Mom_Ist_Summe 0;
BA_ "GenSigSendType" SG_ 1002 Motor_11_alt 0;
BA_ "GenSigStartValue" SG_ 1002 Motor_11_alt 1;
BA_ "GenSigFuncType" SG_ 1002 Motor_11_alt 5;
BA_ "GenSigSwitchedByIgnition" SG_ 1002 Motor_11_alt 0;
BA_ "GenSigSendType" SG_ 1002 Motor_20_alt 0;
BA_ "GenSigStartValue" SG_ 1002 Motor_20_alt 1;
BA_ "GenSigFuncType" SG_ 1002 Motor_20_alt 5;
BA_ "GenSigSwitchedByIgnition" SG_ 1002 Motor_20_alt 0;
BA_ "GenSigSendType" SG_ 1002 PaCo_DiETa_LED 3;
BA_ "GenSigSwitchedByIgnition" SG_ 1002 PaCo_DiETa_LED 0;
BA_ "GenSigSendType" SG_ 1002 RTM_Warnstatus 3;
BA_ "GenSigSwitchedByIgnition" SG_ 1002 RTM_Warnstatus 0;
BA_ "GenSigSendType" SG_ 1003 Areaview_01_alt 0;
BA_ "GenSigStartValue" SG_ 1003 Areaview_01_alt 1;
BA_ "GenSigFuncType" SG_ 1003 Areaview_01_alt 5;
BA_ "GenSigSwitchedByIgnition" SG_ 1003 Areaview_01_alt 0;
BA_ "GenSigSendType" SG_ 1003 AV_Umfeldbeleuchtung_Anf 0;
BA_ "GenSigSwitchedByIgnition" SG_ 1003 AV_Umfeldbeleuchtung_Anf 0;
BA_ "GenSigSendType" SG_ 1003 EBKV_03_alt 0;
BA_ "GenSigStartValue" SG_ 1003 EBKV_03_alt 1;
BA_ "GenSigFuncType" SG_ 1003 EBKV_03_alt 5;
BA_ "GenSigSwitchedByIgnition" SG_ 1003 EBKV_03_alt 0;
BA_ "GenSigSendType" SG_ 1003 EBKV_Fahrer_bremst 3;
BA_ "GenSigSwitchedByIgnition" SG_ 1003 EBKV_Fahrer_bremst 0;
BA_ "GenSigSendType" SG_ 1003 EBKV_QBit_Fahrer_bremst 3;
BA_ "GenSigStartValue" SG_ 1003 EBKV_QBit_Fahrer_bremst 1;
BA_ "GenSigSwitchedByIgnition" SG_ 1003 EBKV_QBit_Fahrer_bremst 0;
BA_ "GenSigSendType" SG_ 1003 EFF_Verbrauch_STH 3;
BA_ "GenSigSwitchedByIgnition" SG_ 1003 EFF_Verbrauch_STH 0;
BA_ "Fehlerwert" SG_ 1003 EFF_Verbrauch_STH 127;
BA_ "GenSigSendType" SG_ 1003 EPS_Lastinfo 0;
BA_ "GenSigStartValue" SG_ 1003 EPS_Lastinfo 254;
BA_ "GenSigSwitchedByIgnition" SG_ 1003 EPS_Lastinfo 0;
BA_ "Fehlerwert" SG_ 1003 EPS_Lastinfo 255;
BA_ "GenSigSendType" SG_ 1003 ESP_50_alt 0;
BA_ "GenSigStartValue" SG_ 1003 ESP_50_alt 1;
BA_ "GenSigFuncType" SG_ 1003 ESP_50_alt 5;
BA_ "GenSigSwitchedByIgnition" SG_ 1003 ESP_50_alt 0;
BA_ "GenSigSendType" SG_ 1003 ESP_Bremsdruck 0;
BA_ "GenSigStartValue" SG_ 1003 ESP_Bremsdruck 100;
BA_ "GenSigSwitchedByIgnition" SG_ 1003 ESP_Bremsdruck 0;
BA_ "Fehlerwert" SG_ 1003 ESP_Bremsdruck 1023;
BA_ "GenSigSendType" SG_ 1003 ESP_QBit_Bremsdruck 0;
BA_ "GenSigStartValue" SG_ 1003 ESP_QBit_Bremsdruck 1;
BA_ "GenSigSwitchedByIgnition" SG_ 1003 ESP_QBit_Bremsdruck 0;
BA_ "GenSigSendType" SG_ 1003 LH_EPS_02_alt 0;
BA_ "GenSigStartValue" SG_ 1003 LH_EPS_02_alt 1;
BA_ "GenSigFuncType" SG_ 1003 LH_EPS_02_alt 5;
BA_ "GenSigSwitchedByIgnition" SG_ 1003 LH_EPS_02_alt 0;
BA_ "GenSigSendType" SG_ 1003 LIN_2_alt 0;
BA_ "GenSigStartValue" SG_ 1003 LIN_2_alt 1;
BA_ "GenSigFuncType" SG_ 1003 LIN_2_alt 5;
BA_ "GenSigSwitchedByIgnition" SG_ 1003 LIN_2_alt 0;
BA_ "GenSigSendType" SG_ 1003 LR_HZG_01_alt 0;
BA_ "GenSigStartValue" SG_ 1003 LR_HZG_01_alt 1;
BA_ "GenSigFuncType" SG_ 1003 LR_HZG_01_alt 5;
BA_ "GenSigSwitchedByIgnition" SG_ 1003 LR_HZG_01_alt 0;
BA_ "GenSigSendType" SG_ 1003 LR_HZG_Konfiguration 0;
BA_ "GenSigSwitchedByIgnition" SG_ 1003 LR_HZG_Konfiguration 0;
BA_ "GenSigSendType" SG_ 1003 LR_HZG_Taster_on_off 0;
BA_ "GenSigSwitchedByIgnition" SG_ 1003 LR_HZG_Taster_on_off 0;
BA_ "GenSigSendType" SG_ 1003 LR_HZG_Temp_Sensor 0;
BA_ "GenSigStartValue" SG_ 1003 LR_HZG_Temp_Sensor 254;
BA_ "GenSigSwitchedByIgnition" SG_ 1003 LR_HZG_Temp_Sensor 0;
BA_ "GenSigSendType" SG_ 1003 MFL_Signalhorn 3;
BA_ "GenSigSwitchedByIgnition" SG_ 1003 MFL_Signalhorn 0;
BA_ "GenSigSendType" SG_ 1003 MO_Fahrpedalrohwert_01 0;
BA_ "GenSigSwitchedByIgnition" SG_ 1003 MO_Fahrpedalrohwert_01 0;
BA_ "Fehlerwert" SG_ 1003 MO_Fahrpedalrohwert_01 255;
BA_ "GenSigSendType" SG_ 1003 MO_QBit_Fahrpedalwerte_01 0;
BA_ "GenSigStartValue" SG_ 1003 MO_QBit_Fahrpedalwerte_01 1;
BA_ "GenSigSwitchedByIgnition" SG_ 1003 MO_QBit_Fahrpedalwerte_01 0;
BA_ "GenSigSendType" SG_ 1003 MO_temporaere_Fahrerabwesenheit 3;
BA_ "GenSigSwitchedByIgnition" SG_ 1003 MO_temporaere_Fahrerabwesenheit 0;
BA_ "GenSigSendType" SG_ 1003 Motor_20_alt 0;
BA_ "GenSigStartValue" SG_ 1003 Motor_20_alt 1;
BA_ "GenSigFuncType" SG_ 1003 Motor_20_alt 5;
BA_ "GenSigSwitchedByIgnition" SG_ 1003 Motor_20_alt 0;
BA_ "GenSigSendType" SG_ 1003 Parkhilfe_01_alt 0;
BA_ "GenSigStartValue" SG_ 1003 Parkhilfe_01_alt 1;
BA_ "GenSigFuncType" SG_ 1003 Parkhilfe_01_alt 5;
BA_ "GenSigSwitchedByIgnition" SG_ 1003 Parkhilfe_01_alt 0;
BA_ "GenSigSendType" SG_ 1003 PH_Stoermeldung 3;
BA_ "GenSigSendType" SG_ 173 GE_Fahrstufe 0;
BA_ "GenSigStartValue" SG_ 173 GE_Fahrstufe 1;
BA_ "GenSigSwitchedByIgnition" SG_ 173 GE_Fahrstufe 0;
BA_ "Fehlerwert" SG_ 173 GE_Fahrstufe 15;
BA_ "GenSigSendType" SG_ 173 GE_Ursache_Fahrstufe_N 0;
BA_ "GenSigSwitchedByIgnition" SG_ 173 GE_Ursache_Fahrstufe_N 0;
BA_ "GenSigSendType" SG_ 173 Getriebe_11_BZ 0;
BA_ "GenSigFuncType" SG_ 173 Getriebe_11_BZ 1;
BA_ "GenSigSwitchedByIgnition" SG_ 173 Getriebe_11_BZ 0;
BA_ "GenSigSendType" SG_ 173 Getriebe_11_CRC 0;
BA_ "GenSigFuncType" SG_ 173 Getriebe_11_CRC 2;
BA_ "GenSigSwitchedByIgnition" SG_ 173 Getriebe_11_CRC 0;
BA_ "GenSigSendType" SG_ 299 GRA_Abbrechen 0;
BA_ "GenSigSendType" SG_ 299 GRA_ACC_01_BZ 0;
BA_ "GenSigFuncType" SG_ 299 GRA_ACC_01_BZ 1;
BA_ "GenSigSendType" SG_ 299 GRA_ACC_01_CRC 0;
BA_ "GenSigFuncType" SG_ 299 GRA_ACC_01_CRC 2;
BA_ "GenSigSendType" SG_ 299 GRA_Codierung 0;
BA_ "GenSigSendType" SG_ 299 GRA_Fehler 0;
BA_ "Fehlerwert" SG_ 299 GRA_Fehler 1;
BA_ "GenSigSendType" SG_ 299 GRA_Hauptschalter 0;
BA_ "GenSigSendType" SG_ 299 GRA_LIM_Taste_verfuegbar 0;
BA_ "GenSigFuncType" SG_ 299 GRA_LIM_Taste_verfuegbar 8;
BA_ "GenSigSendType" SG_ 299 GRA_Limiter 0;
BA_ "GenSigSendType" SG_ 299 GRA_PIT_Limiter 0;
BA_ "GenSigSwitchedByIgnition" SG_ 299 GRA_PIT_Limiter 0;
BA_ "GenSigSendType" SG_ 299 GRA_reserveByte5 0;
BA_ "GenSigSendType" SG_ 299 GRA_reserveByte6 0;
BA_ "GenSigSendType" SG_ 299 GRA_reserveByte7 0;
BA_ "GenSigSendType" SG_ 299 GRA_reserveByte8 0;
BA_ "GenSigSendType" SG_ 299 GRA_Tip_Hoch 0;
BA_ "GenSigSendType" SG_ 299 GRA_Tip_Runter 0;
BA_ "GenSigSendType" SG_ 299 GRA_Tip_Setzen 0;
BA_ "GenSigSendType" SG_ 299 GRA_Tip_Stufe_2 0;
BA_ "GenSigSendType" SG_ 299 GRA_Tip_Wiederaufnahme 0;
BA_ "GenSigSendType" SG_ 299 GRA_TravelAssist 0;
BA_ "GenSigSwitchedByIgnition" SG_ 299 GRA_TravelAssist 0;
BA_ "GenSigSendType" SG_ 299 GRA_Typ_Bedienteil 0;
BA_ "GenSigSendType" SG_ 299 GRA_Typ_Hauptschalter 0;
BA_ "GenSigSendType" SG_ 299 GRA_Verstellung_Zeitluecke 0;
BA_ "GenSigSwitchedByIgnition" SG_ 18 WFS_GSG_CRC 0;
BA_ "GenSigSendType" SG_ 18 WFS_GSG_RND 1;
BA_ "GenSigSwitchedByIgnition" SG_ 18 WFS_GSG_RND 0;
BA_ "GenSigSendType" SG_ 1410 HD_Bewegung_auf 0;
BA_ "GenSigSwitchedByIgnition" SG_ 1410 HD_Bewegung_auf 0;
BA_ "GenSigSendType" SG_ 1410 HD_Bewegung_zu 0;
BA_ "GenSigSwitchedByIgnition" SG_ 1410 HD_Bewegung_zu 0;
BA_ "GenSigSendType" SG_ 1410 HD_Endstellung_oben 0;
BA_ "GenSigSwitchedByIgnition" SG_ 1410 HD_Endstellung_oben 0;
BA_ "GenSigSendType" SG_ 1410 HD_Endstellung_unten 0;
BA_ "GenSigSwitchedByIgnition" SG_ 1410 HD_Endstellung_unten 0;
BA_ "GenSigSendType" SG_ 1410 HD_Innentaster_betaetigt 0;
BA_ "GenSigSwitchedByIgnition" SG_ 1410 HD_Innentaster_betaetigt 0;
BA_ "GenSigSendType" SG_ 1410 HD_Kupp_Ma_aktiv 0;
BA_ "GenSigSwitchedByIgnition" SG_ 1410 HD_Kupp_Ma_aktiv 0;
BA_ "GenSigSendType" SG_ 1410 HD_Kupp_Sl_aktiv 0;
BA_ "GenSigSwitchedByIgnition" SG_ 1410 HD_Kupp_Sl_aktiv 0;
BA_ "GenSigSendType" SG_ 1410 HD_Position 0;
BA_ "GenSigSwitchedByIgnition" SG_ 1410 HD_Position 0;
BA_ "GenSigSendType" SG_ 1410 HD_Rueckmeld_prog 0;
BA_ "GenSigSwitchedByIgnition" SG_ 1410 HD_Rueckmeld_prog 0;
BA_ "GenSigSendType" SG_ 1410 HD_SG_MA_KD_Fehler 0;
BA_ "GenSigSwitchedByIgnition" SG_ 1410 HD_SG_MA_KD_Fehler 0;
BA_ "GenSigSendType" SG_ 1410 HD_SG_SL_KD_Fehler 0;
BA_ "GenSigSwitchedByIgnition" SG_ 1410 HD_SG_SL_KD_Fehler 0;
BA_ "GenSigSendType" SG_ 1410 HD_Spannung 0;
BA_ "GenSigSwitchedByIgnition" SG_ 1410 HD_Spannung 0;
BA_ "GenSigSendType" SG_ 1410 HD_Taster_defekt 0;
BA_ "GenSigSwitchedByIgnition" SG_ 1410 HD_Taster_defekt 0;
BA_ "GenSigSendType" SG_ 1410 HD_UeKB_erkannt 0;
BA_ "GenSigSwitchedByIgnition" SG_ 1410 HD_UeKB_erkannt 0;
BA_ "GenSigSendType" SG_ 1410 HD_Verr_Taster_betaetigt_inv 0;
BA_ "GenSigSwitchedByIgnition" SG_ 1410 HD_Verr_Taster_betaetigt_inv 0;
BA_ "GenSigSendType" SG_ 1410 HD_Verriegelungstaster_betaetigt 0;
BA_ "GenSigSwitchedByIgnition" SG_ 1410 HD_Verriegelungstaster_betaetigt 0;
BA_ "GenSigSendType" SG_ 1410 HD_ZZH_Schalter_S3 3;
BA_ "GenSigSwitchedByIgnition" SG_ 1410 HD_ZZH_Schalter_S3 0;
BA_ "GenSigSendType" SG_ 1410 HDSG_Anf_Umluftklappe 3;
BA_ "GenSigSwitchedByIgnition" SG_ 1410 HDSG_Anf_Umluftklappe 0;
BA_ "GenSigSendType" SG_ 588 ASW_Akustik_Einstellung 0;
BA_ "GenSigSendType" SG_ 588 ASW_Ausgabemodus_BFS 0;
BA_ "GenSigSwitchedByIgnition" SG_ 588 ASW_Ausgabemodus_BFS 0;
BA_ "GenSigSendType" SG_ 588 ASW_Ausgabemodus_FS 0;
BA_ "GenSigSwitchedByIgnition" SG_ 588 ASW_Ausgabemodus_FS 0;
BA_ "GenSigSendType" SG_ 588 ASW_Ausgabemodus_HBFS 0;
BA_ "GenSigSwitchedByIgnition" SG_ 588 ASW_Ausgabemodus_HBFS 0;
BA_ "GenSigSendType" SG_ 588 ASW_Ausgabemodus_HFS 0;
BA_ "GenSigSwitchedByIgnition" SG_ 588 ASW_Ausgabemodus_HFS 0;
BA_ "GenSigSendType" SG_ 588 ASW_Kombiausgabe 0;
BA_ "GenSigSendType" SG_ 588 ASW_Kombitexte 0;
BA_ "GenSigSwitchedByIgnition" SG_ 588 ASW_Kombitexte 0;
BA_ "GenSigSendType" SG_ 588 ASW_Modus 0;
BA_ "GenSigStartValue" SG_ 588 ASW_Modus 4;
BA_ "GenSigSendType" SG_ 588 ASW_Status 0;
BA_ "GenSigSwitchedByIgnition" SG_ 588 ASW_Status 0;
BA_ "Fehlerwert" SG_ 588 ASW_Status 2;
BA_ "GenSigSendType" SG_ 588 ASW_Ton_Richtung_HL 0;
BA_ "GenSigSwitchedByIgnition" SG_ 588 ASW_Ton_Richtung_HL 0;
BA_ "GenSigSendType" SG_ 588 ASW_Ton_Richtung_HR 0;
BA_ "GenSigSwitchedByIgnition" SG_ 588 ASW_Ton_Richtung_HR 0;
BA_ "GenSigSendType" SG_ 588 ASW_Ton_Richtung_VL 0;
BA_ "GenSigSwitchedByIgnition" SG_ 588 ASW_Ton_Richtung_VL 0;
BA_ "GenSigSendType" SG_ 588 ASW_Ton_Richtung_VR 0;
BA_ "GenSigSwitchedByIgnition" SG_ 588 ASW_Ton_Richtung_VR 0;
BA_ "GenSigSendType" SG_ 588 ASW_Warnung_BFS 0;
BA_ "GenSigSwitchedByIgnition" SG_ 588 ASW_Warnung_BFS 0;
BA_ "GenSigSendType" SG_ 588 ASW_Warnung_FS 0;
BA_ "GenSigSwitchedByIgnition" SG_ 588 ASW_Warnung_FS 0;
BA_ "GenSigSendType" SG_ 588 Heckradar_Kombitexte 0;
BA_ "GenSigSwitchedByIgnition" SG_ 588 Heckradar_Kombitexte 0;
BA_ "GenSigSendType" SG_ 588 HRE_Anzeigetexte 0;
BA_ "GenSigSwitchedByIgnition" SG_ 588 HRE_Anzeigetexte 0;
BA_ "GenSigSendType" SG_ 588 RCTA_Kombitexte 0;
BA_ "GenSigSwitchedByIgnition" SG_ 588 RCTA_Kombitexte 0;
BA_ "GenSigSendType" SG_ 588 SWA_Anzeigen 0;
BA_ "GenSigSwitchedByIgnition" SG_ 588 SWA_Anzeigen 0;
BA_ "GenSigSendType" SG_ 588 SWA_Blindheit_erkannt 0;
BA_ "GenSigSendType" SG_ 588 SWA_Blindheitsverdacht 0;
BA_ "GenSigSendType" SG_ 588 SWA_Brightness_Mode_FPM 0;
BA_ "GenSigSwitchedByIgnition" SG_ 588 SWA_Brightness_Mode_FPM 0;
BA_ "Fehlerwert" SG_ 588 SWA_Brightness_Mode_FPM 15;
BA_ "GenSigSendType" SG_ 588 SWA_FT_RueckLED 0;
BA_ "GenSigSwitchedByIgnition" SG_ 588 SWA_FT_RueckLED 0;
BA_ "GenSigSendType" SG_ 588 SWA_Gischtzaehler 0;
BA_ "GenSigSendType" SG_ 588 SWA_Infostufe_Assist_li 0;
BA_ "GenSigSendType" SG_ 588 SWA_Infostufe_Assist_re 0;
BA_ "GenSigSendType" SG_ 588 SWA_Kombiausgabe 0;
BA_ "GenSigSendType" SG_ 588 SWA_Kombiwarnung 0;
BA_ "GenSigSwitchedByIgnition" SG_ 588 SWA_Kombiwarnung 0;
BA_ "GenSigSendType" SG_ 588 SWA_LED_Ausgabemodus_BFS 0;
BA_ "GenSigSendType" SG_ 588 SWA_LED_Ausgabemodus_FS 0;
BA_ "GenSigSendType" SG_ 588 SWA_LED_Hell_BFS 0;
BA_ "GenSigStartValue" SG_ 588 SWA_LED_Hell_BFS 126;
BA_ "Fehlerwert" SG_ 588 SWA_LED_Hell_BFS 127;
BA_ "GenSigSendType" SG_ 588 SWA_LED_Hell_FS 0;
BA_ "GenSigStartValue" SG_ 588 SWA_LED_Hell_FS 126;
BA_ "Fehlerwert" SG_ 588 SWA_LED_Hell_FS 127;
BA_ "GenSigSendType" SG_ 588 SWA_Modus 0;
BA_ "GenSigSendType" SG_ 588 SWA_Modus_System 0;
BA_ "GenSigSendType" SG_ 588 SWA_rel_Fehler 0;
BA_ "Fehlerwert" SG_ 588 SWA_rel_Fehler 1;
BA_ "GenSigSendType" SG_ 588 SWA_rel_Nichtverf 0;
BA_ "GenSigSendType" SG_ 588 SWA_Sta_aktiv 0;
BA_ "GenSigSendType" SG_ 588 SWA_Sta_passiv 0;
BA_ "GenSigSendType" SG_ 588 SWA_Standziele_li 0;
BA_ "GenSigSendType" SG_ 588 SWA_Standziele_re 0;
BA_ "GenSigSendType" SG_ 588 SWA_Status 0;
BA_ "Fehlerwert" SG_ 588 SWA_Status 3;
BA_ "GenSigSendType" SG_ 588 SWA_Status_KuFu 0;
BA_ "Fehlerwert" SG_ 588 SWA_Status_KuFu 3;
BA_ "GenSigSendType" SG_ 588 SWA_Status_System 0;
BA_ "Fehlerwert" SG_ 588 SWA_Status_System 3;
BA_ "GenSigSendType" SG_ 588 SWA_Warnstufe_Assist_li 0;
BA_ "GenSigSendType" SG_ 588 SWA_Warnstufe_Assist_re 0;
BA_ "GenSigSendType" SG_ 1016 HLR_FlHz_Freigabe_HL 3;
BA_ "GenSigSwitchedByIgnition" SG_ 1016 HLR_FlHz_Freigabe_HL 0;
BA_ "GenSigSendType" SG_ 1016 HLR_FlHz_Freigabe_HR 3;
BA_ "GenSigSwitchedByIgnition" SG_ 1016 HLR_FlHz_Freigabe_HR 0;
BA_ "GenSigSendType" SG_ 1016 HLR_FlHz_Freigabe_Ruhesitz 3;
BA_ "GenSigSwitchedByIgnition" SG_ 1016 HLR_FlHz_Freigabe_Ruhesitz 0;
BA_ "GenSigSendType" SG_ 1016 HLR_FlHz_Freigabe_VL 3;
BA_ "GenSigSwitchedByIgnition" SG_ 1016 HLR_FlHz_Freigabe_VL 0;
BA_ "GenSigSendType" SG_ 1016 HLR_FlHz_Freigabe_VR 3;
BA_ "GenSigSwitchedByIgnition" SG_ 1016 HLR_FlHz_Freigabe_VR 0;
BA_ "GenSigSendType" SG_ 1016 HLR_FSH_Freigabe 3;
BA_ "GenSigSwitchedByIgnition" SG_ 1016 HLR_FSH_Freigabe 0;
BA_ "Fehlerwert" SG_ 1016 HLR_FSH_Freigabe 63;
BA_ "GenSigSendType" SG_ 1016 HLR_HSH_Freigabe 3;
BA_ "GenSigSwitchedByIgnition" SG_ 1016 HLR_HSH_Freigabe 0;
BA_ "GenSigSendType" SG_ 1016 HLR_KRH_Freigabe_VL 3;
BA_ "GenSigSwitchedByIgnition" SG_ 1016 HLR_KRH_Freigabe_VL 0;
BA_ "GenSigSendType" SG_ 1016 HLR_KRH_Freigabe_VR 3;
BA_ "GenSigSwitchedByIgnition" SG_ 1016 HLR_KRH_Freigabe_VR 0;
BA_ "GenSigSendType" SG_ 1016 HLR_LRH_Freigabe 3;
BA_ "GenSigSwitchedByIgnition" SG_ 1016 HLR_LRH_Freigabe 0;
BA_ "GenSigSendType" SG_ 1016 HLR_PTC_Freigabe 3;
BA_ "GenSigStartValue" SG_ 1016 HLR_PTC_Freigabe 3;
BA_ "GenSigSwitchedByIgnition" SG_ 1016 HLR_PTC_Freigabe 0;
BA_ "GenSigSendType" SG_ 1016 HLR_PTC_linear_Freigabe 3;
BA_ "GenSigSwitchedByIgnition" SG_ 1016 HLR_PTC_linear_Freigabe 0;
BA_ "Fehlerwert" SG_ 1016 HLR_PTC_linear_Freigabe 63;
BA_ "GenSigSendType" SG_ 1016 HLR_SIH_Freigabe_Fond 3;
BA_ "GenSigSwitchedByIgnition" SG_ 1016 HLR_SIH_Freigabe_Fond 0;
BA_ "GenSigSendType" SG_ 1016 HLR_SIH_Freigabe_HL 3;
BA_ "GenSigSwitchedByIgnition" SG_ 1016 HLR_SIH_Freigabe_HL 0;
BA_ "GenSigSendType" SG_ 1016 HLR_SIH_Freigabe_HR 3;
BA_ "GenSigSwitchedByIgnition" SG_ 1016 HLR_SIH_Freigabe_HR 0;
BA_ "GenSigSendType" SG_ 1016 HLR_SIH_Freigabe_VL 3;
BA_ "GenSigSwitchedByIgnition" SG_ 1016 HLR_SIH_Freigabe_VL 0;
BA_ "GenSigSendType" SG_ 1016 HLR_SIH_Freigabe_VR 3;
BA_ "GenSigSwitchedByIgnition" SG_ 1016 HLR_SIH_Freigabe_VR 0;
BA_ "GenSigSendType" SG_ 1016 HLR_SIL_Freigabe_HL 3;
BA_ "GenSigSwitchedByIgnition" SG_ 1016 HLR_SIL_Freigabe_HL 0;
BA_ "GenSigSendType" SG_ 1016 HLR_SIL_Freigabe_HR 3;
BA_ "GenSigSwitchedByIgnition" SG_ 1016 HLR_SIL_Freigabe_HR 0;
BA_ "GenSigSendType" SG_ 1016 HLR_SIL_Freigabe_VL 3;
BA_ "GenSigSwitchedByIgnition" SG_ 1016 HLR_SIL_Freigabe_VL 0;
BA_ "GenSigSendType" SG_ 1016 HLR_SIL_Freigabe_VR 3;
BA_ "GenSigSwitchedByIgnition" SG_ 1016 HLR_SIL_Freigabe_VR 0;
BA_ "GenSigSendType" SG_ 1016 HLR_Sp_Heizung_Freigabe_BT 3;
BA_ "GenSigSwitchedByIgnition" SG_ 1016 HLR_Sp_Heizung_Freigabe_BT 0;
BA_ "GenSigSendType" SG_ 1016 HLR_Sp_Heizung_Freigabe_FT 3;
BA_ "GenSigSwitchedByIgnition" SG_ 1016 HLR_Sp_Heizung_Freigabe_FT 0;
BA_ "GenSigSendType" SG_ 1016 HLR_TCH_Freigabe 3;
BA_ "GenSigSwitchedByIgnition" SG_ 1016 HLR_TCH_Freigabe 0;
BA_ "GenSigSendType" SG_ 2527679731 IL_TSG_BFS_Dimmzeit_1 3;
BA_ "GenSigSwitchedByIgnition" SG_ 2527679731 IL_TSG_BFS_Dimmzeit_1 0;
BA_ "GenSigSendType" SG_ 2527679731 IL_TSG_BFS_Dimmzeit_2 3;
BA_ "GenSigSwitchedByIgnition" SG_ 2527679731 IL_TSG_BFS_Dimmzeit_2 0;
BA_ "GenSigSendType" SG_ 2527679731 IL_TSG_BFS_Dimmzeit_3 3;
BA_ "GenSigSwitchedByIgnition" SG_ 2527679731 IL_TSG_BFS_Dimmzeit_3 0;
BA_ "GenSigSendType" SG_ 2527679731 IL_TSG_BFS_Dimmzeit_4 3;
BA_ "GenSigSwitchedByIgnition" SG_ 2527679731 IL_TSG_BFS_Dimmzeit_4 0;
BA_ "GenSigSendType" SG_ 2527679731 IL_TSG_BFS_Dimmzeit_Basis_1 3;
BA_ "GenSigSwitchedByIgnition" SG_ 2527679731 IL_TSG_BFS_Dimmzeit_Basis_1 0;
BA_ "GenSigSendType" SG_ 2527679731 IL_TSG_BFS_Dimmzeit_Basis_2 3;
BA_ "GenSigSwitchedByIgnition" SG_ 2527679731 IL_TSG_BFS_Dimmzeit_Basis_2 0;
BA_ "GenSigSendType" SG_ 2527679731 IL_TSG_BFS_Dimmzeit_Basis_3 3;
BA_ "GenSigSwitchedByIgnition" SG_ 2527679731 IL_TSG_BFS_Dimmzeit_Basis_3 0;
BA_ "GenSigSendType" SG_ 2527679731 IL_TSG_BFS_Dimmzeit_Basis_4 3;
BA_ "GenSigSwitchedByIgnition" SG_ 2527679731 IL_TSG_BFS_Dimmzeit_Basis_4 0;
BA_ "GenSigSendType" SG_ 2527679731 IL_TSG_BFS_Zielhelligkeit_1 3;
BA_ "GenSigSwitchedByIgnition" SG_ 2527679731 IL_TSG_BFS_Zielhelligkeit_1 0;
BA_ "GenSigSendType" SG_ 2527679731 IL_TSG_BFS_Zielhelligkeit_2 3;
BA_ "GenSigSwitchedByIgnition" SG_ 2527679731 IL_TSG_BFS_Zielhelligkeit_2 0;
BA_ "GenSigSendType" SG_ 2527679731 IL_TSG_BFS_Zielhelligkeit_3 3;
BA_ "GenSigSwitchedByIgnition" SG_ 2527679731 IL_TSG_BFS_Zielhelligkeit_3 0;
BA_ "GenSigSendType" SG_ 2527679731 IL_TSG_BFS_Zielhelligkeit_4 3;
BA_ "GenSigSwitchedByIgnition" SG_ 2527679731 IL_TSG_BFS_Zielhelligkeit_4 0;
BA_ "GenSigSendType" SG_ 2527679730 IL_TSG_FS_Dimmzeit_1 3;
BA_ "GenSigSwitchedByIgnition" SG_ 2527679730 IL_TSG_FS_Dimmzeit_1 0;
BA_ "GenSigSendType" SG_ 2527679730 IL_TSG_FS_Dimmzeit_2 3;
BA_ "GenSigSwitchedByIgnition" SG_ 2527679730 IL_TSG_FS_Dimmzeit_2 0;
BA_ "GenSigSendType" SG_ 2527679730 IL_TSG_FS_Dimmzeit_3 3;
BA_ "GenSigSwitchedByIgnition" SG_ 2527679730 IL_TSG_FS_Dimmzeit_3 0;
BA_ "GenSigSendType" SG_ 2527679730 IL_TSG_FS_Dimmzeit_4 3;
BA_ "GenSigSwitchedByIgnition" SG_ 2527679730 IL_TSG_FS_Dimmzeit_4 0;
BA_ "GenSigSendType" SG_ 2527679730 IL_TSG_FS_Dimmzeit_Basis_1 3;
BA_ "GenSigSwitchedByIgnition" SG_ 2527679730 IL_TSG_FS_Dimmzeit_Basis_1 0;
BA_ "GenSigSendType" SG_ 2527679730 IL_TSG_FS_Dimmzeit_Basis_2 3;
BA_ "GenSigSwitchedByIgnition" SG_ 2527679730 IL_TSG_FS_Dimmzeit_Basis_2 0;
BA_ "GenSigSendType" SG_ 2527679730 IL_TSG_FS_Dimmzeit_Basis_3 3;
BA_ "GenSigSwitchedByIgnition" SG_ 2527679730 IL_TSG_FS_Dimmzeit_Basis_3 0;
BA_ "GenSigSendType" SG_ 2527679730 IL_TSG_FS_Dimmzeit_Basis_4 3;
BA_ "GenSigSwitchedByIgnition" SG_ 2527679730 IL_TSG_FS_Dimmzeit_Basis_4 0;
BA_ "GenSigSendType" SG_ 2527679730 IL_TSG_FS_Zielhelligkeit_1 3;
BA_ "GenSigSwitchedByIgnition" SG_ 2527679730 IL_TSG_FS_Zielhelligkeit_1 0;
BA_ "GenSigSendType" SG_ 2527679730 IL_TSG_FS_Zielhelligkeit_2 3;
BA_ "GenSigSwitchedByIgnition" SG_ 2527679730 IL_TSG_FS_Zielhelligkeit_2 0;
BA_ "GenSigSendType" SG_ 2527679730 IL_TSG_FS_Zielhelligkeit_3 3;
BA_ "GenSigSwitchedByIgnition" SG_ 2527679730 IL_TSG_FS_Zielhelligkeit_3 0;
BA_ "GenSigSendType" SG_ 2527679730 IL_TSG_FS_Zielhelligkeit_4 3;
BA_ "GenSigSwitchedByIgnition" SG_ 2527679730 IL_TSG_FS_Zielhelligkeit_4 0;
BA_ "GenSigSendType" SG_ 2527679732 IL_TSG_HBFS_Dimmzeit_1 3;
BA_ "GenSigSwitchedByIgnition" SG_ 2527679732 IL_TSG_HBFS_Dimmzeit_1 0;
BA_ "GenSigSendType" SG_ 2527679732 IL_TSG_HBFS_Dimmzeit_2 3;
BA_ "GenSigSwitchedByIgnition" SG_ 2527679732 IL_TSG_HBFS_Dimmzeit_2 0;
BA_ "GenSigSendType" SG_ 2527679732 IL_TSG_HBFS_Dimmzeit_3 3;
BA_ "GenSigSwitchedByIgnition" SG_ 2527679732 IL_TSG_HBFS_Dimmzeit_3 0;
BA_ "GenSigSendType" SG_ 2527679732 IL_TSG_HBFS_Dimmzeit_4 3;
BA_ "GenSigSwitchedByIgnition" SG_ 2527679732 IL_TSG_HBFS_Dimmzeit_4 0;
BA_ "GenSigSendType" SG_ 2527679732 IL_TSG_HBFS_Dimmzeit_Basis_1 3;
BA_ "GenSigSwitchedByIgnition" SG_ 2527679732 IL_TSG_HBFS_Dimmzeit_Basis_1 0;
BA_ "GenSigSendType" SG_ 2527679732 IL_TSG_HBFS_Dimmzeit_Basis_2 3;
BA_ "GenSigSwitchedByIgnition" SG_ 2527679732 IL_TSG_HBFS_Dimmzeit_Basis_2 0;
BA_ "GenSigSendType" SG_ 2527679732 IL_TSG_HBFS_Dimmzeit_Basis_3 3;
BA_ "GenSigSwitchedByIgnition" SG_ 2527679732 IL_TSG_HBFS_Dimmzeit_Basis_3 0;
BA_ "GenSigSendType" SG_ 2527679732 IL_TSG_HBFS_Dimmzeit_Basis_4 3;
BA_ "GenSigSwitchedByIgnition" SG_ 2527679732 IL_TSG_HBFS_Dimmzeit_Basis_4 0;
BA_ "GenSigSendType" SG_ 2527679732 IL_TSG_HBFS_Zielhelligkeit_1 3;
BA_ "GenSigSwitchedByIgnition" SG_ 2527679732 IL_TSG_HBFS_Zielhelligkeit_1 0;
BA_ "GenSigSendType" SG_ 2527679732 IL_TSG_HBFS_Zielhelligkeit_2 3;
BA_ "GenSigSwitchedByIgnition" SG_ 2527679732 IL_TSG_HBFS_Zielhelligkeit_2 0;
BA_ "GenSigSendType" SG_ 2527679732 IL_TSG_HBFS_Zielhelligkeit_3 3;
BA_ "GenSigSwitchedByIgnition" SG_ 2527679732 IL_TSG_HBFS_Zielhelligkeit_3 0;
BA_ "GenSigSendType" SG_ 2527679732 IL_TSG_HBFS_Zielhelligkeit_4 3;
BA_ "GenSigSwitchedByIgnition" SG_ 2527679732 IL_TSG_HBFS_Zielhelligkeit_4 0;
BA_ "GenSigSendType" SG_ 2527679733 IL_TSG_HFS_Dimmzeit_1 3;
BA_ "GenSigSwitchedByIgnition" SG_ 2527679733 IL_TSG_HFS_Dimmzeit_1 0;
BA_ "GenSigSendType" SG_ 2527679733 IL_TSG_HFS_Dimmzeit_2 3;
BA_ "GenSigSwitchedByIgnition" SG_ 2527679733 IL_TSG_HFS_Dimmzeit_2 0;
BA_ "GenSigSendType" SG_ 2527679733 IL_TSG_HFS_Dimmzeit_3 3;
BA_ "GenSigSwitchedByIgnition" SG_ 2527679733 IL_TSG_HFS_Dimmzeit_3 0;
BA_ "GenSigSendType" SG_ 2527679733 IL_TSG_HFS_Dimmzeit_4 3;
BA_ "GenSigSwitchedByIgnition" SG_ 2527679733 IL_TSG_HFS_Dimmzeit_4 0;
BA_ "GenSigSendType" SG_ 2527679733 IL_TSG_HFS_Dimmzeit_Basis_1 3;
BA_ "GenSigSwitchedByIgnition" SG_ 2527679733 IL_TSG_HFS_Dimmzeit_Basis_1 0;
BA_ "GenSigSendType" SG_ 2527679733 IL_TSG_HFS_Dimmzeit_Basis_2 3;
BA_ "GenSigSwitchedByIgnition" SG_ 2527679733 IL_TSG_HFS_Dimmzeit_Basis_2 0;
BA_ "GenSigSendType" SG_ 2527679733 IL_TSG_HFS_Dimmzeit_Basis_3 3;
BA_ "GenSigSwitchedByIgnition" SG_ 2527679733 IL_TSG_HFS_Dimmzeit_Basis_3 0;
BA_ "GenSigSendType" SG_ 2527679733 IL_TSG_HFS_Dimmzeit_Basis_4 3;
BA_ "GenSigSwitchedByIgnition" SG_ 2527679733 IL_TSG_HFS_Dimmzeit_Basis_4 0;
BA_ "GenSigSendType" SG_ 2527679733 IL_TSG_HFS_Zielhelligkeit_1 3;
BA_ "GenSigSwitchedByIgnition" SG_ 2527679733 IL_TSG_HFS_Zielhelligkeit_1 0;
BA_ "GenSigSendType" SG_ 2527679733 IL_TSG_HFS_Zielhelligkeit_2 3;
BA_ "GenSigSwitchedByIgnition" SG_ 2527679733 IL_TSG_HFS_Zielhelligkeit_2 0;
BA_ "GenSigSendType" SG_ 2527679733 IL_TSG_HFS_Zielhelligkeit_3 3;
BA_ "GenSigSwitchedByIgnition" SG_ 2527679733 IL_TSG_HFS_Zielhelligkeit_3 0;
BA_ "GenSigSendType" SG_ 2527679733 IL_TSG_HFS_Zielhelligkeit_4 3;
BA_ "GenSigSwitchedByIgnition" SG_ 2527679733 IL_TSG_HFS_Zielhelligkeit_4 0;
BA_ "GenSigSwitchedByIgnition" SG_ 27 WFS_IMMO_ELV_CRC 0;
BA_ "GenSigSwitchedByIgnition" SG_ 27 WFS_IMMO_ELV_RND 0;
BA_ "GenSigSwitchedByIgnition" SG_ 19 WFS_IMMO_GSG_CRC 0;
BA_ "GenSigSwitchedByIgnition" SG_ 19 WFS_IMMO_GSG_Data_0 0;
BA_ "GenSigSwitchedByIgnition" SG_ 19 WFS_IMMO_GSG_Data_1 0;
BA_ "GenSigSwitchedByIgnition" SG_ 19 WFS_IMMO_GSG_Data_2 0;
BA_ "GenSigSendType" SG_ 19 WFS_IMMO_GSG_Status 1;
BA_ "GenSigSwitchedByIgnition" SG_ 19 WFS_IMMO_GSG_Status 0;
BA_ "GenSigSwitchedByIgnition" SG_ 17 WFS_IMMO_MSG1_CRC 0;
BA_ "GenSigSwitchedByIgnition" SG_ 17 WFS_IMMO_MSG1_Data_0 0;
BA_ "GenSigSwitchedByIgnition" SG_ 17 WFS_IMMO_MSG1_Data_1 0;
BA_ "GenSigSwitchedByIgnition" SG_ 17 WFS_IMMO_MSG1_Data_2 0;
BA_ "GenSigSendType" SG_ 17 WFS_IMMO_MSG1_Status 1;
BA_ "GenSigSwitchedByIgnition" SG_ 17 WFS_IMMO_MSG1_Status 0;
BA_ "GenSigSwitchedByIgnition" SG_ 21 WFS_IMMO_MSG2_CRC 0;
BA_ "GenSigSendType" SG_ 21 WFS_IMMO_MSG2_Status 1;
BA_ "GenSigSwitchedByIgnition" SG_ 21 WFS_IMMO_MSG2_Status 0;
BA_ "GenSigSwitchedByIgnition" SG_ 23 WFS_IMMO_MSG3_CRC 0;
BA_ "GenSigSwitchedByIgnition" SG_ 23 WFS_IMMO_MSG3_Data_0 0;
BA_ "GenSigSwitchedByIgnition" SG_ 23 WFS_IMMO_MSG3_Data_1 0;
BA_ "GenSigSwitchedByIgnition" SG_ 23 WFS_IMMO_MSG3_Data_2 0;
BA_ "GenSigSendType" SG_ 23 WFS_IMMO_MSG3_Status 1;
BA_ "GenSigSwitchedByIgnition" SG_ 23 WFS_IMMO_MSG3_Status 0;
BA_ "GenSigSwitchedByIgnition" SG_ 25 WFS_IMMO_MSG4_CRC 0;
BA_ "GenSigSwitchedByIgnition" SG_ 25 WFS_IMMO_MSG4_Data_0 0;
BA_ "GenSigSwitchedByIgnition" SG_ 25 WFS_IMMO_MSG4_Data_1 0;
BA_ "GenSigSwitchedByIgnition" SG_ 25 WFS_IMMO_MSG4_Data_2 0;
BA_ "GenSigSendType" SG_ 25 WFS_IMMO_MSG4_Status 1;
BA_ "GenSigSwitchedByIgnition" SG_ 25 WFS_IMMO_MSG4_Status 0;
BA_ "GenSigSwitchedByIgnition" SG_ 29 WFS_IMMO_OCU_CRC 0;
BA_ "GenSigSwitchedByIgnition" SG_ 29 WFS_IMMO_OCU_RND 0;
BA_REL_ "GenSigTimeoutTime" BU_SG_REL_ BCM SG_ 885 ESC_54_BZ 500;
BA_REL_ "GenSigTimeoutTime" BU_SG_REL_ BCM SG_ 885 SSO_EdgeCount_Sum 500;
BA_REL_ "GenSigTimeoutTime" BU_SG_REL_ BCM SG_ 885 SOK_ESC_54_Signatur 500;
BA_REL_ "GenSigTimeoutTime" BU_SG_REL_ BCM SG_ 278 ESP_VL_Fahrtrichtung 1000;
BA_REL_ "GenSigTimeoutTime" BU_SG_REL_ BCM SG_ 278 ESP_VR_Fahrtrichtung 1000;
BA_REL_ "GenSigTimeoutTime" BU_SG_REL_ BCM SG_ 278 ESP_HL_Fahrtrichtung 1000;
BA_REL_ "GenSigTimeoutTime" BU_SG_REL_ BCM SG_ 278 ESP_HR_Fahrtrichtung 1000;
BA_REL_ "GenSigTimeoutTime" BU_SG_REL_ BCM SG_ 178 ESP_HL_Radgeschw_02 500;
BA_REL_ "GenSigTimeoutTime" BU_SG_REL_ BCM SG_ 178 ESP_HR_Radgeschw_02 500;
BA_REL_ "GenSigTimeoutTime" BU_SG_REL_ BCM SG_ 178 ESP_VL_Radgeschw_02 500;
BA_REL_ "GenSigTimeoutTime" BU_SG_REL_ BCM SG_ 178 ESP_VR_Radgeschw_02 500;
BA_REL_ "GenSigTimeoutTime" BU_SG_REL_ BCM SG_ 1629 BR_Systemart 5000;
BA_REL_ "GenSigTimeoutTime" BU_SG_REL_ BCM SG_ 1629 ESP_Zaehnezahl 5000;
BA_REL_ "GenSigTimeoutTime" BU_SG_REL_ BCM SG_ 253 ESP_21_CRC 500;
BA_REL_ "GenSigTimeoutTime" BU_SG_REL_ BCM SG_ 253 ESP_21_BZ 500;
BA_REL_ "GenSigTimeoutTime" BU_SG_REL_ BCM SG_ 253 ESC_v_Signal_Qualifier_High_Low 500;
BA_REL_ "GenSigTimeoutTime" BU_SG_REL_ BCM SG_ 253 ESP_v_Signal 500;
BA_REL_ "GenSigTimeoutTime" BU_SG_REL_ BCM SG_ 253 ESP_QBit_v_Signal 500;
BA_REL_ "GenSigTimeoutTime" BU_SG_REL_ BCM SG_ 795 ESP_m_Raddrehz 500;
BA_REL_ "GenSigTimeoutTime" BU_SG_REL_ BCM SG_ 795 ESP_Wegimp_VA 500;
BA_REL_ "GenSigTimeoutTime" BU_SG_REL_ BCM SG_ 795 ESP_Wegimp_Ueberlauf 500;
BA_REL_ "GenSigTimeoutTime" BU_SG_REL_ BCM SG_ 1605 FLA_aktiv 5000;
BA_REL_ "GenSigTimeoutTime" BU_SG_REL_ BCM SG_ 1605 FLA_ISP_defekt 5000;
BA_REL_ "GenSigTimeoutTime" BU_SG_REL_ BCM SG_ 1605 FLA_Sensor_blockiert 5000;
BA_REL_ "GenSigTimeoutTime" BU_SG_REL_ BCM SG_ 1605 FLA_Fernlicht_PWM 5000;
BA_REL_ "GenSigTimeoutTime" BU_SG_REL_ BCM SG_ 1605 FLA_Aufblenden 5000;
BA_REL_ "GenSigTimeoutTime" BU_SG_REL_ BCM SG_ 1605 FLA_SAE_Mode 5000;
BA_REL_ "GenSigTimeoutTime" BU_SG_REL_ BCM SG_ 986 LWI_01_alt 1000;
BA_REL_ "GenSigTimeoutTime" BU_SG_REL_ BCM SG_ 986 LWI_Sensorstatus 1000;
BA_REL_ "GenSigTimeoutTime" BU_SG_REL_ BCM SG_ 986 LWI_VZ_Lenkradwinkel 1000;
BA_REL_ "GenSigTimeoutTime" BU_SG_REL_ BCM SG_ 986 LWI_Lenkradwinkel 1000;
BA_REL_ "GenSigTimeoutTime" BU_SG_REL_ BCM SG_ 988 Motor_12_alt 500;
BA_REL_ "GenSigTimeoutTime" BU_SG_REL_ BCM SG_ 988 ESP_07_alt 500;
BA_REL_ "GenSigTimeoutTime" BU_SG_REL_ BCM SG_ 988 Getriebe_11_alt 500;
BA_REL_ "GenSigTimeoutTime" BU_SG_REL_ BCM SG_ 988 Getriebe_17_alt 500;
BA_REL_ "GenSigTimeoutTime" BU_SG_REL_ BCM SG_ 988 Getriebe_14_alt 500;
BA_REL_ "GenSigTimeoutTime" BU_SG_REL_ BCM SG_ 988 MO_QBit_Drehzahl_01 500;
BA_REL_ "GenSigTimeoutTime" BU_SG_REL_ BCM SG_ 988 MO_Drehzahl_01 500;
BA_REL_ "GenSigTimeoutTime" BU_SG_REL_ BCM SG_ 988 GE_Fahrstufe 500;
BA_REL_ "GenSigTimeoutTime" BU_SG_REL_ BCM SG_ 988 GE_Ursache_Fahrstufe_N 500;
BA_REL_ "GenSigTimeoutTime" BU_SG_REL_ BCM SG_ 988 ESP_Rollenmodus_Deaktivieren 500;
BA_REL_ "GenSigTimeoutTime" BU_SG_REL_ BCM SG_ 988 GE_Sperr_Info_WFS 500;
BA_REL_ "GenSigTimeoutTime" BU_SG_REL_ BCM SG_ 988 GE_Veto_Rollfaehigkeit 500;
BA_REL_ "GenSigTimeoutTime" BU_SG_REL_ BCM SG_ 988 Bel_DiETa_Mode2 500;
BA_REL_ "GenSigTimeoutTime" BU_SG_REL_ BCM SG_ 1002 Bel_DiETa_Mode 2000;
BA_REL_ "GenSigTimeoutTime" BU_SG_REL_ BCM SG_ 1002 PaCo_DiETa_LED 2000;
BA_REL_ "GenSigTimeoutTime" BU_SG_REL_ BCM SG_ 1003 LIN_2_alt 1000;
BA_REL_ "GenSigTimeoutTime" BU_SG_REL_ BCM SG_ 1003 Motor_20_alt 1000;
BA_REL_ "GenSigTimeoutTime" BU_SG_REL_ BCM SG_ 1003 LR_HZG_01_alt 1000;
BA_REL_ "GenSigTimeoutTime" BU_SG_REL_ BCM SG_ 1003 Areaview_01_alt 1000;
BA_REL_ "GenSigTimeoutTime" BU_SG_REL_ BCM SG_ 1003 EBKV_03_alt 1000;
BA_REL_ "GenSigTimeoutTime" BU_SG_REL_ BCM SG_ 1003 LR_HZG_Taster_on_off 1000;
BA_REL_ "GenSigTimeoutTime" BU_SG_REL_ BCM SG_ 1003 LR_HZG_Temp_Sensor 1000;
BA_REL_ "GenSigTimeoutTime" BU_SG_REL_ BCM SG_ 1003 MFL_Signalhorn 1000;
BA_REL_ "GenSigTimeoutTime" BU_SG_REL_ BCM SG_ 1003 EBKV_Fahrer_bremst 1000;
BA_REL_ "GenSigTimeoutTime" BU_SG_REL_ BCM SG_ 1003 MO_temporaere_Fahrerabwesenheit 1000;
BA_REL_ "GenSigTimeoutTime" BU_SG_REL_ BCM SG_ 1003 AV_Umfeldbeleuchtung_Anf 1000;
BA_REL_ "GenSigTimeoutTime" BU_SG_REL_ BCM SG_ 1003 LR_HZG_Konfiguration 1000;
BA_REL_ "GenSigTimeoutTime" BU_SG_REL_ BCM SG_ 1003 EBKV_QBit_Fahrer_bremst 1000;
BA_REL_ "GenSigTimeoutTime" BU_SG_REL_ BCM SG_ 173 Getriebe_11_CRC 500;
BA_REL_ "GenSigTimeoutTime" BU_SG_REL_ BCM SG_ 173 Getriebe_11_BZ 500;
BA_REL_ "GenSigTimeoutTime" BU_SG_REL_ BCM SG_ 173 GE_Fahrstufe 500;
BA_REL_ "GenSigTimeoutTime" BU_SG_REL_ BCM SG_ 1410 HD_Bewegung_auf 2000;
BA_REL_ "GenSigTimeoutTime" BU_SG_REL_ BCM SG_ 1410 HD_Bewegung_zu 2000;
BA_REL_ "GenSigTimeoutTime" BU_SG_REL_ BCM SG_ 1410 HD_Innentaster_betaetigt 2000;
BA_REL_ "GenSigTimeoutTime" BU_SG_REL_ BCM SG_ 1410 HD_Position 2000;
BA_REL_ "GenSigTimeoutTime" BU_SG_REL_ BCM SG_ 1410 HD_Rueckmeld_prog 2000;
BA_REL_ "GenSigTimeoutTime" BU_SG_REL_ BCM SG_ 1410 HD_Verriegelungstaster_betaetigt 2000;
BA_REL_ "GenSigTimeoutTime" BU_SG_REL_ BCM SG_ 1410 HD_Verr_Taster_betaetigt_inv 2000;
BA_REL_ "GenSigTimeoutTime" BU_SG_REL_ BCM SG_ 1410 HD_ZZH_Schalter_S3 2000;
BA_REL_ "GenSigTimeoutTime" BU_SG_REL_ BCM SG_ 588 ASW_Warnung_FS 500;
BA_REL_ "GenSigTimeoutTime" BU_SG_REL_ BCM SG_ 588 ASW_Warnung_BFS 500;
BA_REL_ "GenSigTimeoutTime" BU_SG_REL_ BCM SG_ 1016 HLR_KRH_Freigabe_VL 5000;
BA_REL_ "GenSigTimeoutTime" BU_SG_REL_ BCM SG_ 1016 HLR_KRH_Freigabe_VR 5000;
BA_REL_ "GenSigTimeoutTime" BU_SG_REL_ BCM SG_ 1016 HLR_LRH_Freigabe 5000;
BA_REL_ "GenSigTimeoutTime" BU_SG_REL_ Gateway_Max SG_ 299 GRA_Hauptschalter 500;
BA_REL_ "GenSigTimeoutTime" BU_SG_REL_ Gateway_Max SG_ 299 GRA_Abbrechen 500;
BA_REL_ "GenSigTimeoutTime" BU_SG_REL_ Gateway_Max SG_ 299 GRA_Limiter 500;
BA_REL_ "GenSigTimeoutTime" BU_SG_REL_ Gateway_Max SG_ 299 GRA_Tip_Setzen 500;
BA_REL_ "GenSigTimeoutTime" BU_SG_REL_ Gateway_Max SG_ 299 GRA_Tip_Hoch 500;
BA_REL_ "GenSigTimeoutTime" BU_SG_REL_ Gateway_Max SG_ 299 GRA_Tip_Runter 500;
BA_REL_ "GenSigTimeoutTime" BU_SG_REL_ Gateway_Max SG_ 299 GRA_Tip_Wiederaufnahme 500;
BA_REL_ "GenSigTimeoutTime" BU_SG_REL_ Gateway_Max SG_ 299 GRA_Verstellung_Zeitluecke 500;
BA_REL_ "GenSigTimeoutTime" BU_SG_REL_ Gateway_Max SG_ 299 GRA_Tip_Stufe_2 500;
BA_REL_ "GenSigTimeoutTime" BU_SG_REL_ Gateway_Max SG_ 299 GRA_TravelAssist 500;
BA_REL_ "GenSigTimeoutTime" BU_SG_REL_ TSGGen3_BFS SG_ 253 ESP_21_CRC 500;
BA_REL_ "GenSigTimeoutTime" BU_SG_REL_ TSGGen3_BFS SG_ 253 ESP_21_BZ 500;
BA_REL_ "GenSigTimeoutTime" BU_SG_REL_ TSGGen3_BFS SG_ 253 ESP_v_Signal 500;
BA_REL_ "GenSigTimeoutTime" BU_SG_REL_ TSGGen3_BFS SG_ 253 ESP_QBit_v_Signal 500;
BA_REL_ "GenSigTimeoutTime" BU_SG_REL_ TSGGen3_BFS SG_ 588 SWA_LED_Hell_BFS 500;
BA_REL_ "GenSigTimeoutTime" BU_SG_REL_ TSGGen3_BFS SG_ 588 SWA_LED_Hell_FS 500;
BA_REL_ "GenSigTimeoutTime" BU_SG_REL_ TSGGen3_BFS SG_ 588 SWA_LED_Ausgabemodus_BFS 500;
BA_REL_ "GenSigTimeoutTime" BU_SG_REL_ TSGGen3_BFS SG_ 588 ASW_Ausgabemodus_HBFS 500;
BA_REL_ "GenSigTimeoutTime" BU_SG_REL_ TSGGen3_BFS SG_ 588 ASW_Akustik_Einstellung 500;
BA_REL_ "GenSigTimeoutTime" BU_SG_REL_ TSGGen3_BFS SG_ 588 ASW_Status 500;
BA_REL_ "GenSigTimeoutTime" BU_SG_REL_ TSGGen3_BFS SG_ 588 ASW_Ausgabemodus_BFS 500;
BA_REL_ "GenSigTimeoutTime" BU_SG_REL_ TSGGen3_BFS SG_ 588 ASW_Warnung_FS 500;
BA_REL_ "GenSigTimeoutTime" BU_SG_REL_ TSGGen3_BFS SG_ 588 ASW_Warnung_BFS 500;
BA_REL_ "GenSigTimeoutTime" BU_SG_REL_ TSGGen3_BFS SG_ 1016 HLR_Sp_Heizung_Freigabe_BT 5000;
BA_REL_ "GenSigTimeoutTime" BU_SG_REL_ TSGGen3_BFS SG_ 2527679731 IL_TSG_BFS_Dimmzeit_Basis_1 5000;
BA_REL_ "GenSigTimeoutTime" BU_SG_REL_ TSGGen3_BFS SG_ 2527679731 IL_TSG_BFS_Dimmzeit_Basis_2 5000;
BA_REL_ "GenSigTimeoutTime" BU_SG_REL_ TSGGen3_BFS SG_ 2527679731 IL_TSG_BFS_Dimmzeit_Basis_3 5000;
BA_REL_ "GenSigTimeoutTime" BU_SG_REL_ TSGGen3_BFS SG_ 2527679731 IL_TSG_BFS_Dimmzeit_Basis_4 5000;
BA_REL_ "GenSigTimeoutTime" BU_SG_REL_ TSGGen3_BFS SG_ 2527679731 IL_TSG_BFS_Dimmzeit_1 5000;
BA_REL_ "GenSigTimeoutTime" BU_SG_REL_ TSGGen3_BFS SG_ 2527679731 IL_TSG_BFS_Dimmzeit_2 5000;
BA_REL_ "GenSigTimeoutTime" BU_SG_REL_ TSGGen3_BFS SG_ 2527679731 IL_TSG_BFS_Dimmzeit_3 5000;
BA_REL_ "GenSigTimeoutTime" BU_SG_REL_ TSGGen3_BFS SG_ 2527679731 IL_TSG_BFS_Dimmzeit_4 5000;
BA_REL_ "GenSigTimeoutTime" BU_SG_REL_ TSGGen3_BFS SG_ 2527679731 IL_TSG_BFS_Zielhelligkeit_1 5000;
BA_REL_ "GenSigTimeoutTime" BU_SG_REL_ TSGGen3_BFS SG_ 2527679731 IL_TSG_BFS_Zielhelligkeit_2 5000;
BA_REL_ "GenSigTimeoutTime" BU_SG_REL_ TSGGen3_BFS SG_ 2527679731 IL_TSG_BFS_Zielhelligkeit_3 5000;
BA_REL_ "GenSigTimeoutTime" BU_SG_REL_ TSGGen3_BFS SG_ 2527679731 IL_TSG_BFS_Zielhelligkeit_4 5000;
BA_REL_ "GenSigTimeoutTime" BU_SG_REL_ TSGGen3_FS SG_ 253 ESP_21_CRC 500;
BA_REL_ "GenSigTimeoutTime" BU_SG_REL_ TSGGen3_FS SG_ 253 ESP_21_BZ 500;
BA_REL_ "GenSigTimeoutTime" BU_SG_REL_ TSGGen3_FS SG_ 253 ESP_v_Signal 500;
BA_REL_ "GenSigTimeoutTime" BU_SG_REL_ TSGGen3_FS SG_ 253 ESP_QBit_v_Signal 500;
BA_REL_ "GenSigTimeoutTime" BU_SG_REL_ TSGGen3_FS SG_ 588 SWA_LED_Hell_BFS 500;
BA_REL_ "GenSigTimeoutTime" BU_SG_REL_ TSGGen3_FS SG_ 588 SWA_LED_Hell_FS 500;
BA_REL_ "GenSigTimeoutTime" BU_SG_REL_ TSGGen3_FS SG_ 588 SWA_LED_Ausgabemodus_FS 500;
BA_REL_ "GenSigTimeoutTime" BU_SG_REL_ TSGGen3_FS SG_ 588 ASW_Ausgabemodus_HFS 500;
BA_REL_ "GenSigTimeoutTime" BU_SG_REL_ TSGGen3_FS SG_ 588 ASW_Akustik_Einstellung 500;
BA_REL_ "GenSigTimeoutTime" BU_SG_REL_ TSGGen3_FS SG_ 588 ASW_Status 500;
BA_REL_ "GenSigTimeoutTime" BU_SG_REL_ TSGGen3_FS SG_ 588 ASW_Warnung_FS 500;
BA_REL_ "GenSigTimeoutTime" BU_SG_REL_ TSGGen3_FS SG_ 588 ASW_Warnung_BFS 500;
BA_REL_ "GenSigTimeoutTime" BU_SG_REL_ TSGGen3_FS SG_ 588 ASW_Ausgabemodus_FS 500;
BA_REL_ "GenSigTimeoutTime" BU_SG_REL_ TSGGen3_FS SG_ 1016 HLR_Sp_Heizung_Freigabe_FT 5000;
BA_REL_ "GenSigTimeoutTime" BU_SG_REL_ TSGGen3_FS SG_ 2527679730 IL_TSG_FS_Dimmzeit_Basis_1 5000;
BA_REL_ "GenSigTimeoutTime" BU_SG_REL_ TSGGen3_FS SG_ 2527679730 IL_TSG_FS_Dimmzeit_Basis_2 5000;
BA_REL_ "GenSigTimeoutTime" BU_SG_REL_ TSGGen3_FS SG_ 2527679730 IL_TSG_FS_Dimmzeit_Basis_3 5000;
BA_REL_ "GenSigTimeoutTime" BU_SG_REL_ TSGGen3_FS SG_ 2527679730 IL_TSG_FS_Dimmzeit_Basis_4 5000;
BA_REL_ "GenSigTimeoutTime" BU_SG_REL_ TSGGen3_FS SG_ 2527679730 IL_TSG_FS_Dimmzeit_1 5000;
BA_REL_ "GenSigTimeoutTime" BU_SG_REL_ TSGGen3_FS SG_ 2527679730 IL_TSG_FS_Dimmzeit_2 5000;
BA_REL_ "GenSigTimeoutTime" BU_SG_REL_ TSGGen3_FS SG_ 2527679730 IL_TSG_FS_Dimmzeit_3 5000;
BA_REL_ "GenSigTimeoutTime" BU_SG_REL_ TSGGen3_FS SG_ 2527679730 IL_TSG_FS_Dimmzeit_4 5000;
BA_REL_ "GenSigTimeoutTime" BU_SG_REL_ TSGGen3_FS SG_ 2527679730 IL_TSG_FS_Zielhelligkeit_1 5000;
BA_REL_ "GenSigTimeoutTime" BU_SG_REL_ TSGGen3_FS SG_ 2527679730 IL_TSG_FS_Zielhelligkeit_2 5000;
BA_REL_ "GenSigTimeoutTime" BU_SG_REL_ TSGGen3_FS SG_ 2527679730 IL_TSG_FS_Zielhelligkeit_3 5000;
BA_REL_ "GenSigTimeoutTime" BU_SG_REL_ TSGGen3_FS SG_ 2527679730 IL_TSG_FS_Zielhelligkeit_4 5000;
BA_REL_ "GenSigTimeoutTime" BU_SG_REL_ TSGGen3_HBFS SG_ 253 ESP_21_CRC 500;
BA_REL_ "GenSigTimeoutTime" BU_SG_REL_ TSGGen3_HBFS SG_ 253 ESP_21_BZ 500;
BA_REL_ "GenSigTimeoutTime" BU_SG_REL_ TSGGen3_HBFS SG_ 253 ESP_v_Signal 500;
BA_REL_ "GenSigTimeoutTime" BU_SG_REL_ TSGGen3_HBFS SG_ 253 ESP_QBit_v_Signal 500;
BA_REL_ "GenSigTimeoutTime" BU_SG_REL_ TSGGen3_HBFS SG_ 588 SWA_LED_Hell_BFS 500;
BA_REL_ "GenSigTimeoutTime" BU_SG_REL_ TSGGen3_HBFS SG_ 588 SWA_LED_Hell_FS 500;
BA_REL_ "GenSigTimeoutTime" BU_SG_REL_ TSGGen3_HBFS SG_ 588 ASW_Ausgabemodus_HBFS 500;
BA_REL_ "GenSigTimeoutTime" BU_SG_REL_ TSGGen3_HBFS SG_ 588 ASW_Akustik_Einstellung 500;
BA_REL_ "GenSigTimeoutTime" BU_SG_REL_ TSGGen3_HBFS SG_ 588 ASW_Status 500;
BA_REL_ "GenSigTimeoutTime" BU_SG_REL_ TSGGen3_HBFS SG_ 588 ASW_Warnung_FS 500;
BA_REL_ "GenSigTimeoutTime" BU_SG_REL_ TSGGen3_HBFS SG_ 588 ASW_Warnung_BFS 500;
BA_REL_ "GenSigTimeoutTime" BU_SG_REL_ TSGGen3_HBFS SG_ 2527679732 IL_TSG_HBFS_Dimmzeit_Basis_1 5000;
BA_REL_ "GenSigTimeoutTime" BU_SG_REL_ TSGGen3_HBFS SG_ 2527679732 IL_TSG_HBFS_Dimmzeit_Basis_2 5000;
BA_REL_ "GenSigTimeoutTime" BU_SG_REL_ TSGGen3_HBFS SG_ 2527679732 IL_TSG_HBFS_Dimmzeit_Basis_3 5000;
BA_REL_ "GenSigTimeoutTime" BU_SG_REL_ TSGGen3_HBFS SG_ 2527679732 IL_TSG_HBFS_Dimmzeit_Basis_4 5000;
BA_REL_ "GenSigTimeoutTime" BU_SG_REL_ TSGGen3_HBFS SG_ 2527679732 IL_TSG_HBFS_Dimmzeit_1 5000;
BA_REL_ "GenSigTimeoutTime" BU_SG_REL_ TSGGen3_HBFS SG_ 2527679732 IL_TSG_HBFS_Dimmzeit_2 5000;
BA_REL_ "GenSigTimeoutTime" BU_SG_REL_ TSGGen3_HBFS SG_ 2527679732 IL_TSG_HBFS_Dimmzeit_3 5000;
BA_REL_ "GenSigTimeoutTime" BU_SG_REL_ TSGGen3_HBFS SG_ 2527679732 IL_TSG_HBFS_Dimmzeit_4 5000;
BA_REL_ "GenSigTimeoutTime" BU_SG_REL_ TSGGen3_HBFS SG_ 2527679732 IL_TSG_HBFS_Zielhelligkeit_1 5000;
BA_REL_ "GenSigTimeoutTime" BU_SG_REL_ TSGGen3_HBFS SG_ 2527679732 IL_TSG_HBFS_Zielhelligkeit_2 5000;
BA_REL_ "GenSigTimeoutTime" BU_SG_REL_ TSGGen3_HBFS SG_ 2527679732 IL_TSG_HBFS_Zielhelligkeit_3 5000;
BA_REL_ "GenSigTimeoutTime" BU_SG_REL_ TSGGen3_HBFS SG_ 2527679732 IL_TSG_HBFS_Zielhelligkeit_4 5000;
BA_REL_ "GenSigTimeoutTime" BU_SG_REL_ TSGGen3_HFS SG_ 253 ESP_21_CRC 500;
BA_REL_ "GenSigTimeoutTime" BU_SG_REL_ TSGGen3_HFS SG_ 253 ESP_21_BZ 500;
BA_REL_ "GenSigTimeoutTime" BU_SG_REL_ TSGGen3_HFS SG_ 253 ESP_v_Signal 500;
BA_REL_ "GenSigTimeoutTime" BU_SG_REL_ TSGGen3_HFS SG_ 253 ESP_QBit_v_Signal 500;
BA_REL_ "GenSigTimeoutTime" BU_SG_REL_ TSGGen3_HFS SG_ 588 SWA_LED_Hell_BFS 500;
BA_REL_ "GenSigTimeoutTime" BU_SG_REL_ TSGGen3_HFS SG_ 588 SWA_LED_Hell_FS 500;
BA_REL_ "GenSigTimeoutTime" BU_SG_REL_ TSGGen3_HFS SG_ 588 ASW_Ausgabemodus_HFS 500;
BA_REL_ "GenSigTimeoutTime" BU_SG_REL_ TSGGen3_HFS SG_ 588 ASW_Akustik_Einstellung 500;
BA_REL_ "GenSigTimeoutTime" BU_SG_REL_ TSGGen3_HFS SG_ 588 ASW_Status 500;
BA_REL_ "GenSigTimeoutTime" BU_SG_REL_ TSGGen3_HFS SG_ 588 ASW_Warnung_FS 500;
BA_REL_ "GenSigTimeoutTime" BU_SG_REL_ TSGGen3_HFS SG_ 588 ASW_Warnung_BFS 500;
BA_REL_ "GenSigTimeoutTime" BU_SG_REL_ TSGGen3_HFS SG_ 2527679733 IL_TSG_HFS_Dimmzeit_Basis_1 5000;
BA_REL_ "GenSigTimeoutTime" BU_SG_REL_ TSGGen3_HFS SG_ 2527679733 IL_TSG_HFS_Dimmzeit_Basis_2 5000;
BA_REL_ "GenSigTimeoutTime" BU_SG_REL_ TSGGen3_HFS SG_ 2527679733 IL_TSG_HFS_Dimmzeit_Basis_3 5000;
BA_REL_ "GenSigTimeoutTime" BU_SG_REL_ TSGGen3_HFS SG_ 2527679733 IL_TSG_HFS_Dimmzeit_Basis_4 5000;
BA_REL_ "GenSigTimeoutTime" BU_SG_REL_ TSGGen3_HFS SG_ 2527679733 IL_TSG_HFS_Dimmzeit_1 5000;
BA_REL_ "GenSigTimeoutTime" BU_SG_REL_ TSGGen3_HFS SG_ 2527679733 IL_TSG_HFS_Dimmzeit_2 5000;
BA_REL_ "GenSigTimeoutTime" BU_SG_REL_ TSGGen3_HFS SG_ 2527679733 IL_TSG_HFS_Dimmzeit_3 5000;
BA_REL_ "GenSigTimeoutTime" BU_SG_REL_ TSGGen3_HFS SG_ 2527679733 IL_TSG_HFS_Dimmzeit_4 5000;
BA_REL_ "GenSigTimeoutTime" BU_SG_REL_ TSGGen3_HFS SG_ 2527679733 IL_TSG_HFS_Zielhelligkeit_1 5000;
BA_REL_ "GenSigTimeoutTime" BU_SG_REL_ TSGGen3_HFS SG_ 2527679733 IL_TSG_HFS_Zielhelligkeit_2 5000;
BA_REL_ "GenSigTimeoutTime" BU_SG_REL_ TSGGen3_HFS SG_ 2527679733 IL_TSG_HFS_Zielhelligkeit_3 5000;
BA_REL_ "GenSigTimeoutTime" BU_SG_REL_ TSGGen3_HFS SG_ 2527679733 IL_TSG_HFS_Zielhelligkeit_4 5000;
BA_REL_ "GenSigTimeoutTime" BU_SG_REL_ WLC_01_CFD SG_ 253 ESP_v_Signal 500;
BA_REL_ "GenSigTimeoutTime" BU_SG_REL_ WLC_01_CFD SG_ 253 ESP_QBit_v_Signal 500;
BA_REL_ "GenSigTimeoutTime" BU_SG_REL_ WLC_01_CFD SG_ 2463978794 FBS_Anf_Start_Auth 2000;
BA_REL_ "GenSigTimeoutTime" BU_SG_REL_ WLC_01_CFD SG_ 2463978794 WLC_laden_unterbrechen 2000;
VAL_ 885 SSO_EdgeCount_Sum 0 "init" 0 "Fehler" ;
VAL_ 278 ESP_QBit_Wegimpuls_VL 0 "gueltiger_Wert" 1 "Ersatz_Init_oder_Fehlerwert" ;
VAL_ 278 ESP_QBit_Wegimpuls_VR 0 "gueltiger_Wert" 1 "Ersatz_Init_oder_Fehlerwert" ;
VAL_ 278 ESP_QBit_Wegimpuls_HL 0 "gueltiger_Wert" 1 "Ersatz_Init_oder_Fehlerwert" ;
VAL_ 278 ESP_QBit_Wegimpuls_HR 0 "gueltiger_Wert" 1 "Ersatz_Init_oder_Fehlerwert" ;
VAL_ 278 ESP_Wegimpuls_VL 1021 "Init" 1022 "Unterspannung" 1023 "Fehler" ;
VAL_ 278 ESP_Wegimpuls_VR 1021 "Init" 1022 "Unterspannung" 1023 "Fehler" ;
VAL_ 278 ESP_Wegimpuls_HL 1021 "Init" 1022 "Unterspannung" 1023 "Fehler" ;
VAL_ 278 ESP_Wegimpuls_HR 1021 "Init" 1022 "Unterspannung" 1023 "Fehler" ;
VAL_ 278 ESP_VL_Fahrtrichtung 0 "Vorwaerts" 1 "Rueckwaerts" 2 "Init" 3 "ungueltig_oder_nicht_verbaut" ;
VAL_ 278 ESP_VR_Fahrtrichtung 0 "Vorwaerts" 1 "Rueckwaerts" 2 "Init" 3 "ungueltig_oder_nicht_verbaut" ;
VAL_ 278 ESP_HL_Fahrtrichtung 0 "Vorwaerts" 1 "Rueckwaerts" 2 "Init" 3 "ungueltig_oder_nicht_verbaut" ;
VAL_ 278 ESP_HR_Fahrtrichtung 0 "Vorwaerts" 1 "Rueckwaerts" 2 "Init" 3 "ungueltig_oder_nicht_verbaut" ;
VAL_ 178 ESP_HL_Radgeschw_02 65533 "Unterspannung" 65534 "Init" 65535 "Fehler" ;
VAL_ 178 ESP_HR_Radgeschw_02 65533 "Unterspannung" 65534 "Init" 65535 "Fehler" ;
VAL_ 178 ESP_VL_Radgeschw_02 65533 "Unterspannung" 65534 "Init" 65535 "Fehler" ;
VAL_ 178 ESP_VR_Radgeschw_02 65533 "Unterspannung" 65534 "Init" 65535 "Fehler" ;
VAL_ 1629 BR_Systemart 0 "ABS" 1 "ABS_ASR" 2 "ESP" 3 "ESP_mit_integrierter_EPB" ;
VAL_ 1629 ESP_SpannungsAnf_02 0 "keine_Anforderung" 1 "Anforderung_Stufe1" 2 "Anforderung_Stufe2" 3 "Anforderung_Stufe3" ;
VAL_ 1629 ESP_Charisma_FahrPr 0 "keine_Funktion" 1 "Programm_1" 2 "Programm_2" 3 "Programm_3" 4 "Programm_4" 5 "Programm_5" 6 "Programm_6" 7 "Programm_7" 8 "Programm_8" 9 "Programm_9" 10 "Programm_10" 11 "Programm_11" 12 "Programm_12" 13 "Programm_13" 14 "Programm_14" 15 "Programm_15" ;
VAL_ 1629 ESP_Charisma_Status 0 "Init" 1 "verfuegbar" 2 "nicht_verfuegbar" 3 "asynchron_durch_Fahrerwunsch" ;
VAL_ 1629 ESP_Wiederstart_Anz_01 0 "keine_Anzeige" 1 "Rueckwaertsrollen" ;
VAL_ 1629 ESP_Wiederstart_Anz_02 0 "keine_Anzeige" 1 "Autohold_Rutschen" ;
VAL_ 1629 ESP_Wiederstart_Anz_03 0 "keine_Anzeige" 1 "Offroad_HDC" ;
VAL_ 1629 ESP_Wiederstart_Anz_04 0 "keine_Anzeige" 1 "ESC_Off" ;
VAL_ 1629 ESP_Stoppverbot_Anz_01 0 "keine_Anzeige" 1 "Notbremsung_aktiv" ;
VAL_ 1629 ESP_Stoppverbot_Anz_02 0 "keine_Anzeige" 1 "Autohold_AVH_Rutschen" ;
VAL_ 1629 ESP_Stoppverbot_Anz_03 0 "keine_Anzeige" 1 "Rueckwaertsrollen" ;
VAL_ 1629 ESP_Stoppverbot_Anz_04 0 "keine_Anzeige" 1 "ESP_Pumpenlauf" ;
VAL_ 1629 ESP_Stoppverbot_Anz_05 0 "keine_Anzeige" 1 "ESP_OFF" ;
VAL_ 1629 ESP_Stoppverbot_Anz_06 0 "keine_Anzeige" 1 "Offroad_HDC" ;
VAL_ 1629 ESP_Stoppverbot_Anz_07 0 "keine_Anzeige" 1 "ESP_Haltefunktion_nicht_verfuegbar" ;
VAL_ 1629 ESP_Stoppverbot_Anz_Std 0 "keine_Anzeige" 1 "Standard_Stoppvetogrund" ;
VAL_ 1629 ESP_Dachrelingsensor 0 "Sensor_nicht_verbaut" 1 "Quertraeger_montiert" 2 "Quertraeger_nicht_montiert" 3 "Fehler" ;
VAL_ 1629 ESP_Stoppverbot_Anz_08 0 "keine_Anzeige" 1 "Neigungsbegrenzung" ;
VAL_ 1629 HDC_Charisma_FahrPr 0 "keine_Funktion" 1 "Programm_1" 2 "Programm_2" 3 "Programm_3" 4 "Programm_4" 5 "Programm_5" 6 "Programm_6" 7 "Programm_7" 8 "Programm_8" 9 "Programm_9" 10 "Programm_10" 11 "Programm_11" 12 "Programm_12" 13 "Programm_13" 14 "Programm_14" 15 "Programm_15" ;
VAL_ 1629 HDC_Charisma_Status 0 "Init" 1 "verfuegbar" 2 "nicht_verfuegbar" 3 "asynchron_durch_Fahrerwunsch" ;
VAL_ 1629 BR_QBit_Reifenumfang 0 "gueltiger_Wert" 1 "Ersatz_Init_oder_Fehlerwert" ;
VAL_ 253 BR_Eingriffsmoment 1022 "Init" 1023 "Fehler" ;
VAL_ 253 ESP_PLA_Bremseingriff 0 "inaktiv" 1 "aktiv" ;
VAL_ 253 ESP_Diagnose 0 "ESP_nicht_in_Diagnose" 1 "ESP_in_Diagnose" ;
VAL_ 253 ESC_Reku_Freigabe 0 "keine_Freigabe_der_Rekuperation" 1 "Freigabe_der_Rekuperation" ;
VAL_ 253 ESC_v_Signal_Qualifier_High_Low 0 "Gueteschwelle_kleiner_1kmh" 1 "Gueteschwelle_kleiner_3kmh" 2 "Gueteschwelle_kleiner_5kmh" 3 "Gueteschwelle_kleiner_10kmh" 4 "Gueteschwelle_kleiner_20kmh" 5 "Gueteschwelle_groessergleich_20kmh" 6 "Init" 7 "Fehler" ;
VAL_ 253 ESP_Vorsteuerung 0 "keine_Vorsteuerung_aktiv" 1 "Vorsteuerung_aktiv" ;
VAL_ 253 ESP_AWV3_Brems_aktiv 0 "inaktiv" 1 "aktiv" ;
VAL_ 253 OBD_Schlechtweg 0 "kein_Schlechtweg_erkannt" 1 "Schlechtweg_erkannt" ;
VAL_ 253 OBD_QBit_Schlechtweg 0 "gueltiger_Wert" 1 "Ersatz_Init_oder_Fehlerwert" ;
VAL_ 253 ESP_v_Signal 65533 "Unterspannung" 65534 "Init" 65535 "Fehler" ;
VAL_ 253 ASR_Tastung_passiv 0 "ASR_aktiviert" 1 "ASR_passiv_getastet_oder_Schwellen_geaendert" ;
VAL_ 253 ESP_Tastung_passiv 0 "ESP_aktiviert" 1 "ESP_passiv_getastet_oder_Schwellen_geaendert" ;
VAL_ 253 ESP_Systemstatus 0 "iO" 1 "Fehler" ;
VAL_ 253 ASR_Schalteingriff 0 "keine_Anforderung" 1 "ASR_Schaltkennfeld" 2 "Rueckschaltung" 3 "Schaltverbot" ;
VAL_ 253 ESP_Haltebestaetigung 0 "kein_sicheres_Halten" 1 "sicheres_Halten" ;
VAL_ 253 ESP_MKB_Abbruch_Geschw 0 "MKB_nicht_beendet_wg_v_Schwelle" 1 "MKB_beendet_wg_v_Schwelle" ;
VAL_ 253 ESP_QBit_v_Signal 0 "gueltiger_Wert" 1 "Ersatz_Init_oder_Fehlerwert" ;
VAL_ 253 ABS_Bremsung 0 "keine_ABS_Regelung" 1 "ABS_Regelung_aktiv" ;
VAL_ 253 ASR_Anf 0 "keine_Anforderung" 1 "ASR_Anforderung" ;
VAL_ 253 MSR_Anf 0 "keine Anfoderung" 1 "MSR-Anforderung" ;
VAL_ 253 EBV_Eingriff 0 "kein_EBV_Eingriff" 1 "EBV_Eingriff" ;
VAL_ 253 EDS_Eingriff 0 "kein_EDS_Eingriff" 1 "EDS_Eingriff" ;
VAL_ 253 ESP_Eingriff 0 "kein_ESP_Eingriff" 1 "ESP_Eingriff_aktiv" ;
VAL_ 253 ESP_ASP 0 "inaktiv" 1 "aktiv" ;
VAL_ 253 ESP_Anhaltevorgang_ACC_aktiv 0 "inaktiv" 1 "aktiv" ;
VAL_ 795 ESP_Lampe 0 "Aus" 1 "Ein" ;
VAL_ 795 ABS_Lampe 0 "Aus" 1 "Ein" ;
VAL_ 795 BK_Lampe_02 0 "aus" 1 "Typ1_ein_statisch" 2 "Typ2_ein_statisch" 3 "Warnung" ;
VAL_ 795 TC_Lampe 0 "Aus" 1 "Ein" ;
VAL_ 795 ESP_m_Raddrehz 32765 "Unterspannung" 32766 "Init" 32767 "Fehler" ;
VAL_ 795 ESP_Textanzeigen_03 0 "kein_Text" 1 "ESP_Stoerung" 2 "ABS_Stoerung" 3 "ESP_ABS_Stoerung" 4 "Werkstatt_Bremse" 5 "ASR_Stoerung" 6 "ESP_switched_off" 7 "ASR_off" 8 "ESP_ASR_on" 10 "keine_Bremskraftverstaerkung" 11 "ASR_aktiviert" 12 "ABS_ASR_Stoerung" 15 "ESP_offroad" 17 "ESP_sport" 18 "ESP_Zwangsaktivierung" 19 "ESP_Taster_Info" 20 "TC_aktiv" 21 "reserviert_fuer_Verlwarn" 22 "TC_switched_off" 23 "Verlwarn_akt_Rollsicher_inakt" 24 "ESP_SuperSport" 25 "ESP_Offroad_nicht_verfuegbar" ;
VAL_ 795 ESP_Meldungen 0 "keine_Anzeige" 1 "Autohold_Hinweis_1" 2 "Stoerung_Autohold" 3 "Stoerung_Hillholder" 4 "Uebernehmen" 5 "Autohold_aus" 6 "Autohold_Hinweis_2" ;
VAL_ 795 ESP_Fehlerstatus_Wegimp 0 "Wegimpulse_iO" 1 "Fehler" ;
VAL_ 795 ESP_Wegimp_Ueberlauf 0 "Reset_und_kein_Ueberlauf" 1 "mindestens_1x_Ueberlauf" ;
VAL_ 795 ESP_QBit_Wegimp_VA 0 "gueltiger_Wert" 1 "Ersatz_Init_oder_Fehlerwert" ;
VAL_ 795 ESP_HDC_FktLampe 0 "Aus" 1 "Ein" ;
VAL_ 795 ESP_Off_Lampe 0 "Lampe_aus" 1 "Lampe_ein" ;
VAL_ 795 ESP_HDC_Regelgeschw 0 "nicht_verbaut" 125 "HDC_Standby" 126 "Init" 127 "Fehler" ;
VAL_ 795 ESP_BKV_Warnung 0 "keine_Anzeige" 1 "keine_Bremskraftverstaerkung" ;
VAL_ 2463978794 FBS_Anf_Start_Auth 0 "Init_kein_Auth_Request" 1 "Auth_Request" ;
VAL_ 2463978794 FBS_Anf_Access_Auth 0 "Init_kein_Auth_Request" 1 "Auth_Request" ;
VAL_ 2463978794 FBS_MDK_in_Reichweite 0 "ausser_Reichweite" 1 "innerhalb_Reichweite" ;
VAL_ 2463978794 WLC_laden_unterbrechen 0 "Laden_nicht_unterbrechen" 1 "Laden_unterbrechen" ;
VAL_ 2463978794 FBS_MDK_button 0 "no_command" 1 "unlock" 2 "lock" 3 "rear_trunk" 4 "front_trunk" 5 "panic" 6 "joker" 7 "park" 8 "remotestart" 9 "open_convertible" 10 "close_convertible" ;
VAL_ 1605 FLA_aktiv 0 "inaktiv" 1 "aktiv" ;
VAL_ 1605 FLA_ISP_defekt 0 "iO" 1 "defekt" ;
VAL_ 1605 FLA_Sensor_blockiert 0 "Sensor in Ordnung" 1 "Sensor blockiert" ;
VAL_ 1605 FLA_Abblendursache 0 "nichts erkannt (Init-Wert)" 1 "enentgegenkommendes Fahrzeug (Scheinwerfer erkannt)" 2 "vorausfahrendes Fahrzeug (Heckleuchten erkannt)" 4 "Geschwindigkeitslimit unterschritten" 8 "Ort_oder_Infrastruktur_erkannt" 16 "Umgebungshelligkeit_generell_zu_hell" 32 "Nebel_oder_Sensor_blockiert" 64 "Übertemperatur Imager" 128 "Verzögerungsbedingung" 255 "Fehler" ;
VAL_ 1605 FLA_Fernlicht_PWM 127 "Fehler" ;
VAL_ 1605 ISP_EC_Lichtwert_vorne 62 "Init" 63 "Fehler" ;
VAL_ 1605 ISP_EC_Lichtwert_hinten 62 "Init" 63 "Fehler" ;
VAL_ 1605 ISP_Himmelsrichtung 30 "nicht verfuegbar bzw. Init" 31 "Fehler" ;
VAL_ 1605 ISP_Taste_betaetigt 0 "nicht_betaetigt" 1 "betaetigt" ;
VAL_ 1605 ISP_EC_aktiv 0 "inaktiv" 1 "aktiv" ;
VAL_ 1605 ISP_Kompass_aktiv 0 "inaktiv" 1 "aktiv" ;
VAL_ 1605 FLA_Aufblenden 0 "nicht_aufblenden" 1 "aufblenden" ;
VAL_ 1605 FLA_SAE_Mode 0 "Init" 1 "FLA_Icon_invertiert" ;
VAL_ 2589283684 GRA_FoD_Status 0 "Init" 1 "Funktion_inaktiv" 2 "Funktion_aktiv" ;
VAL_ 2589283684 FoD_Transmission_Info 0 "Initwert" 1 "start_transmission" 2 "finish_transmission" ;
VAL_ 986 ESP_05_alt 0 "aktuell" 1 "veraltet" ;
VAL_ 986 EPB_01_alt 0 "aktuell" 1 "veraltet" ;
VAL_ 986 ESP_21_alt 0 "aktuell" 1 "veraltet" ;
VAL_ 986 LWI_01_alt 0 "aktuell" 1 "veraltet" ;
VAL_ 986 Parkhilfe_01_alt 0 "aktuell" 1 "veraltet" ;
VAL_ 986 Kamera_Status_alt 0 "aktuell" 1 "veraltet" ;
VAL_ 986 ESP_HDC_Standby 0 "HDC_Funktion_nicht_im_Standby" 1 "HDC_Funktion_im_Standby" ;
VAL_ 986 ECD_Bremslicht 0 "Aus" 1 "Ein" ;
VAL_ 986 EPB_Status 0 "offen" 1 "Bremse_geschl_(Spannkraft_voll/reduziert)" 2 "Aktuator_im_Lauf" 3 "Fehler_oder_unbekannt" ;
VAL_ 986 EPB_QBit_Pedalweg_Kuppl 0 "gültiger Wert" 1 "Ersatz-, Init- oder Fehlerwert" ;
VAL_ 986 ESP_QBit_v_Signal 0 "gueltiger_Wert" 1 "Ersatz_Init_oder_Fehlerwert" ;
VAL_ 986 ABS_Bremsung 0 "keine_ABS_Regelung" 1 "ABS_Regelung_aktiv" ;
VAL_ 986 ESP_Eingriff 0 "kein_ESP_Eingriff" 1 "ESP_Eingriff_aktiv" ;
VAL_ 986 Kamera_FSH_aktiv 0 "Kamera_Frontscheibenheizung_nicht_aktiviert" 1 "Kamera_Frontscheibenheizung_aktiviert" ;
VAL_ 986 EPB_Pedalweg_Kuppl 0 "Init" 255 "Fehler" ;
VAL_ 986 ESP_v_Signal 65533 "Unterspannung" 65534 "Init" 65535 "Fehler" ;
VAL_ 986 LWI_QBit_Lenkradwinkel 0 "gültiger Wert" 1 "ausserhalb der Spezifikation" ;
VAL_ 986 LWI_Sensorstatus 0 "iO" 1 "nicht kalibriert" ;
VAL_ 986 LWI_VZ_Lenkradwinkel 0 "positiv_links_von_der_Nullstellung" 1 "negativ" ;
VAL_ 986 LWI_Lenkradwinkel 8190 "Init" 8191 "Fehler" ;
VAL_ 986 PH_Anf_Audioabsenkung 0 "Keine_Audioabsenkung" 1 "Anforderung_Audioabsenkung" ;
VAL_ 986 PH_Systemzustand 0 "Anlage aus" 1 "Anlage durch einlegen R-Gang aktiviert" 2 "Anlage manuell durch Taster aktiviert" 3 "Anlage automatisch aktiviert" 4 "Anlage durch ARA aktiviert" 6 "Init - Initialisierungsphase nach Kl. 15 ein / Reset" 7 "Fehler-/gestört Zustand, System noch aktiv" ;
VAL_ 986 PH_Taster 0 "Taster_nicht_gedrueckt" 1 "Taster_gedrueckt" 2 "reserviert" 3 "Fehler" ;
VAL_ 986 ESP_MKB_Abbruch_Geschw 0 "MKB_nicht_beendet_wg_v_Schwelle" 1 "MKB_beendet_wg_v_Schwelle" ;
VAL_ 986 PLA_Anf_Aufschaltung_RVC 0 "Keine_RVC_Aufschalteanf" 1 "RVC_Aufschalteanforderung" ;
VAL_ 988 Motor_12_alt 0 "aktuell" 1 "veraltet" ;
VAL_ 988 ESP_07_alt 0 "aktuell" 1 "veraltet" ;
VAL_ 988 Getriebe_11_alt 0 "aktuell" 1 "veraltet" ;
VAL_ 988 Getriebe_13_alt 0 "aktuell" 1 "veraltet" ;
VAL_ 988 Getriebe_17_alt 0 "aktuell" 1 "veraltet" ;
VAL_ 988 TSK_06_alt 0 "aktuell" 1 "veraltet" ;
VAL_ 988 Getriebe_14_alt 0 "aktuell" 1 "veraltet" ;
VAL_ 988 ESP_50_alt 0 "aktuell" 1 "veraltet" ;
VAL_ 988 MO_QBit_Drehzahl_01 0 "gueltiger_Wert" 1 "Ersatz_Init_oder_Fehlerwert" ;
VAL_ 988 MKE_Texte 0 "keine_Anzeige" 1 "Warnstufe_1" 2 "Warnstufe_2" ;
VAL_ 988 MKE_Stufe 0 "deaktiviert" 1 "nicht_verfügbar" 2 "Stufe_1" 3 "Stufe_2" 4 "Stufe_3" 5 "Stufe_4" 6 "reserviert" 7 "reserviert" ;
VAL_ 988 TSK_Hauptschalter_GRA_ACC 0 "Init" 1 "Aus" 2 "Ein" 3 "Fehler" ;
VAL_ 988 TSK_Status 0 "Hauptschalter_aus" 1 "Init" 2 "passiv" 3 "aktiv" 4 "Uebertreten" 5 "brake_only_Mode" 6 "reversibel_aus" 7 "irreversibel_aus" ;
VAL_ 988 EPB_Schalterposition 0 "keine Fahreranforderung" 1 "Fahreranforderung Öffnen" 2 "Fahreranforderung Schließen" 3 "Fehler" ;
VAL_ 988 GE_LaunchControl 0 "inaktiv" 1 "aktiv" ;
VAL_ 988 GE_Fahrstufe 0 "Zwischenstellung" 1 "Init" 5 "Position_P" 6 "Position_R" 7 "Position_N" 8 "Position_D" 9 "Position_S" 10 "Effizienz" 13 "Tipp_in_S" 14 "Tipp_in_D" 15 "Fehler" ;
VAL_ 988 GE_Ursache_Fahrstufe_N 0 "Fahrstufe_N_mit_Fahrerwunsch" 1 "Fahrstufe_N_ohne_Fahrerwunsch" ;
VAL_ 988 GE_Notlauf 0 "kein Notlauf / Init" 1 "Getriebe im Notlauf" ;
VAL_ 988 ESP_Rollenmodus_Deaktivieren 0 "keine_Aenderung" 1 "Abbruch" ;
VAL_ 988 GE_Freilauf_Status 0 "Freilauf_inaktiv_aber_moeglich" 1 "Freilauf_aktiv" 2 "Freilauf_nicht_moegl_1Verhinderer" 3 "Freilauf_nicht_moegl_gr_1Verhinderer" 7 "Fehler" ;
VAL_ 988 GE_Sperr_Info_WFS 0 "nicht_gesperrt" 1 "gesperrt" ;
VAL_ 988 TSK_Limiter_ausgewaehlt 0 "kein_Limiter_ausgewaehlt" 1 "Limiter_ausgewaehlt" ;
VAL_ 988 GE_Veto_Rollfaehigkeit 0 "kein_Veto__Rollfaehigkeit_moegl" 1 "Veto__Rollfaehigkeit_nicht_moegl" ;
VAL_ 988 EPB_Status_02 0 "offen" 1 "geschlossen_Parken" 2 "teilgespannt_Halten" 3 "im_Lauf_oeffnen" 4 "im_Lauf_schliessen" 5 "tbd" 6 "Init" 7 "unbekannt" ;
VAL_ 988 ACC_Status_ACC 0 "ACC_OFF_Hauptschalter_aus" 1 "ACC_INIT" 2 "ACC_STANDBY" 3 "ACC_AKTIV_regelt" 4 "ACC_OVERRIDE" 5 "ACC_Abschaltreaktion" 6 "reversibler_Fehler_im_ACC_System" 7 "irreversibler_Fehler_im_ACC_System" ;
VAL_ 988 ACC_18_alt 0 "aktuell" 1 "veraltet" ;
VAL_ 988 Bel_DiETa_Mode2 0 "LED_Aus" 1 "LED_Ein" 2 "LED_blinken" 3 "Fehler" ;
VAL_ 1002 ESP_05_alt 0 "aktuell" 1 "veraltet" ;
VAL_ 1002 Getriebe_14_alt 0 "aktuell" 1 "veraltet" ;
VAL_ 1002 Motor_11_alt 0 "aktuell" 1 "veraltet" ;
VAL_ 1002 Motor_20_alt 0 "aktuell" 1 "veraltet" ;
VAL_ 1002 EBKV_03_alt 0 "aktuell" 1 "veraltet" ;
VAL_ 1002 AWV_03_alt 0 "aktuell" 1 "veraltet" ;
VAL_ 1002 AWV_Verz_Freigabe 0 "Verzoegerung_nicht_freigeben" 1 "Verzoegerung_freigeben" ;
VAL_ 1002 AWV_Verz_Anf 1023 "keine_Anforderung" ;
VAL_ 1002 Bel_DiETa_Mode 0 "LED_Aus" 1 "LED_Ein" 2 "LED_blinken" 3 "Fehler" ;
VAL_ 1002 PaCo_DiETa_LED 0 "LED_Inactive" 1 "LED_Active" 2 "LED_Flashing" 3 "Error" ;
VAL_ 1002 RTM_Warnstatus 0 "keine_Warnung" 1 "Warnstufe_ChNational" 2 "reserviert" 3 "reserviert" ;
VAL_ 1002 EBKV_Fahrer_bremst 0 "Fahrer_bremst_nicht_selbst" 1 "Fahrer_will_selbst_bremsen" ;
VAL_ 1002 AWV_Zielobjekttyp 0 "Unbekannt" 1 "Fussgaenger" 2 "Zweirad" 3 "PKW" 4 "LKW" 5 "reserviert" 6 "reserviert" 7 "reserviert" 8 "reserviert" 9 "reserviert" 10 "reserviert" 11 "reserviert" 12 "reserviert" 13 "reserviert" 14 "kein_relevantes_Obj" 15 "init" ;
VAL_ 1002 ESP_Bremsdruck 1023 "Fehler" ;
VAL_ 1002 MO_Mom_Ist_Summe 1022 "Init" ;
VAL_ 1002 MO_Fahrpedalrohwert_01 255 "Fehler" ;
VAL_ 1002 GE_Sumpftemperatur 255 "Fehler" ;
VAL_ 1003 LH_EPS_02_alt 0 "aktuell" 1 "veraltet" ;
VAL_ 1003 LIN_2_alt 0 "aktuell" 1 "veraltet" ;
VAL_ 1003 Parkhilfe_01_alt 0 "aktuell" 1 "veraltet" ;
VAL_ 1003 Motor_20_alt 0 "aktuell" 1 "veraltet" ;
VAL_ 1003 LR_HZG_01_alt 0 "aktuell" 1 "veraltet" ;
VAL_ 1003 Areaview_01_alt 0 "aktuell" 1 "veraltet" ;
VAL_ 1003 EBKV_03_alt 0 "aktuell" 1 "veraltet" ;
VAL_ 1003 ESP_50_alt 0 "aktuell" 1 "veraltet" ;
VAL_ 1003 EPS_Lastinfo 254 "Init" 255 "Fehler" ;
VAL_ 1003 EFF_Verbrauch_STH 127 "Fehler" ;
VAL_ 1003 LR_HZG_Taster_on_off 0 "nicht_betaetigt" 1 "betaetigt" ;
VAL_ 1003 LR_HZG_Temp_Sensor 253 "KS_Plus__Unterbrechung" 254 "Init" 255 "Tempsensor_fehlerhaft__KS_GND" ;
VAL_ 1003 MFL_Signalhorn 0 "nicht_betaetigt" 1 "betaetigt" ;
VAL_ 1003 EBKV_Fahrer_bremst 0 "Fahrer_bremst_nicht_selbst" 1 "Fahrer_will_selbst_bremsen" ;
VAL_ 1003 PH_Stoermeldung 0 "keine_Anzeige_kein_Gong" 1 "Textmeldung_PDC_hinten_gestoert_mit_Gong" 2 "Textmeldung_PDC_hinten_gestoert_ohne_Gong" 3 "Textmeldung_PDC_vorn_gestoert_mit_Gong" 4 "Textmeldung_PDC_vorn_gestoert_ohne_Gong" 5 "Textmeldung_PDC_gestoert_mit_Gong" 6 "Textmeldung_PDC_gestoert_ohne_Gong" 7 "Textmeldung_PDC_seitlich_gestoert_mit_Gong" 8 "Textmeldung_PDC_seitlich_gestoert_ohne_Gong" ;
VAL_ 1003 MO_temporaere_Fahrerabwesenheit 0 "nicht_erkannt" 1 "erkannt" ;
VAL_ 1003 AV_Umfeldbeleuchtung_Anf 0 "nicht_angefordert" 1 "angefordert" ;
VAL_ 1003 MO_Fahrpedalrohwert_01 255 "Fehler" ;
VAL_ 1003 LR_HZG_Konfiguration 0 "Init" 1 "Parametersatz_1" 2 "Parametersatz_2" 3 "Parametersatz_3" 4 "Parametersatz_4" 5 "Parametersatz_5" 6 "Parametersatz_6" 7 "Parametersatz_7" ;
VAL_ 1003 EBKV_QBit_Fahrer_bremst 0 "gueltiger_Wert" 1 "Ersatz_Init_oder_Fehlerwert" ;
VAL_ 1003 MO_QBit_Fahrpedalwerte_01 0 "gueltiger_Wert" 1 "Ersatz_Init_oder_Fehlerwert" ;
VAL_ 1003 ESP_QBit_Bremsdruck 0 "gueltiger_Wert" 1 "Ersatz_Init_oder_Fehlerwert" ;
VAL_ 1003 ESP_Bremsdruck 1023 "Fehler" ;
VAL_ 173 GE_Fahrstufe 0 "Zwischenstellung" 1 "Init" 5 "Position_P" 6 "Position_R" 7 "Position_N" 8 "Position_D" 9 "Position_S" 10 "Effizienz" 13 "Tipp_in_S" 14 "Tipp_in_D" 15 "Fehler" ;
VAL_ 173 GE_Ursache_Fahrstufe_N 0 "Fahrstufe_N_mit_Fahrerwunsch" 1 "Fahrstufe_N_ohne_Fahrerwunsch" ;
VAL_ 299 GRA_Hauptschalter 0 "Aus_Taster_nicht_betaetigt" 1 "Ein_Taster_betaetigt" ;
VAL_ 299 GRA_Abbrechen 0 "nicht_betaetigt" 1 "betaetigt" ;
VAL_ 299 GRA_Typ_Hauptschalter 0 "gerasteter_Lenkstockschalter" 1 "getasteter_Lenkstockschalter" ;
VAL_ 299 GRA_Limiter 0 "nicht_betaetigt" 1 "betaetigt" ;
VAL_ 299 GRA_Tip_Setzen 0 "nicht_betaetigt" 1 "betaetigt" ;
VAL_ 299 GRA_Tip_Hoch 0 "nicht_betaetigt" 1 "betaetigt" ;
VAL_ 299 GRA_Tip_Runter 0 "nicht_betaetigt" 1 "betaetigt" ;
VAL_ 299 GRA_Tip_Wiederaufnahme 0 "nicht_betaetigt" 1 "betaetigt" ;
VAL_ 299 GRA_Verstellung_Zeitluecke 0 "Taste_nicht_betaetigt" 1 "Dist_minus_1" 2 "Dist_plus_1" 3 "Dist_Toggle" ;
VAL_ 299 GRA_Codierung 0 "kein_Hebel" 1 "GRA_Hebel" 2 "ACC_Hebel" 3 "Limiter_Only" ;
VAL_ 299 GRA_Fehler 0 "kein_Fehler" 1 "Fehler" ;
VAL_ 299 GRA_LIM_Taste_verfuegbar 0 "Limiter_Taste_nicht_vorhanden" 1 "Limiter_Taste_vorhanden" ;
VAL_ 299 GRA_Tip_Stufe_2 0 "Tip_Stufe_1_keine_Betaetigung" 1 "Tip_Stufe_2" ;
VAL_ 299 GRA_Typ_Bedienteil 0 "Init" 1 "4_Positions_Bedienteil" 2 "6_Positions_Bedienteil" 3 "8_Positions_Bedienteil" 4 "PAG_5_Positions_Bedienteil" 5 "VW_MFL_Gen2" 6 "VW_MFL_Gen3" 7 "PAG_DX1_Bedienteil" ;
VAL_ 299 GRA_TravelAssist 0 "nicht_betaetigt" 1 "betaetigt" ;
VAL_ 299 GRA_PIT_Limiter 0 "nicht_betaetigt" 1 "betaetigt" ;
VAL_ 1410 HD_Endstellung_oben 1 "HD in Endstellung oben (offen)" ;
VAL_ 1410 HD_Endstellung_unten 0 "Init" 1 "HD in Endstellung unten (geschlossen)" ;
VAL_ 1410 HD_Bewegung_auf 0 "Init" 1 "HD in Bewegung auf" ;
VAL_ 1410 HD_Bewegung_zu 0 "Init" 1 "HD in Bewegung zu" ;
VAL_ 1410 HD_Innentaster_betaetigt 0 "HD_Innentaster_nicht_betaetigt" 1 "HD_Innentaster_betaetigt" ;
VAL_ 1410 HD_Kupp_Ma_aktiv 1 "Kupplung 1 ein" ;
VAL_ 1410 HD_Kupp_Sl_aktiv 1 "Kupplung 2 aktiv" ;
VAL_ 1410 HD_UeKB_erkannt 0 "Init" 1 "Einklemmschutz aktiv" ;
VAL_ 1410 HD_SG_MA_KD_Fehler 0 "SG_funktionsfaehig" 1 "SG_defekt" ;
VAL_ 1410 HD_SG_SL_KD_Fehler 0 "SG_funktionsfaehig" 1 "SG_defekt" ;
VAL_ 1410 HD_Taster_defekt 0 "Taster_funktionsfähig" 1 "Taster defekt" ;
VAL_ 1410 HD_Rueckmeld_prog 0 "keine Rueckmeldung" 1 "Rueckmeldung zur Programmierung Endstellung aktiv" ;
VAL_ 1410 HD_Verriegelungstaster_betaetigt 0 "Taster_nicht_betaetigt" 1 "Taster_betaetigt" ;
VAL_ 1410 HD_Verr_Taster_betaetigt_inv 0 "Taster_betaetigt" 1 "Taster_nicht_betaetigt" ;
VAL_ 1410 HD_ZZH_Schalter_S3 0 "nicht_betaetigt" 1 "betaetigt" ;
VAL_ 1410 HDSG_Anf_Umluftklappe 0 "aus" 1 "an" ;
VAL_ 588 SWA_LED_Hell_BFS 126 "Init" 127 "Fehler" ;
VAL_ 588 SWA_LED_Hell_FS 126 "Init" 127 "Fehler" ;
VAL_ 588 SWA_LED_Ausgabemodus_BFS 0 "LED_aus" 1 "Infostufe" 2 "Warnstufe" 3 "Aufpruefen_SWAABAHeck_ASW" 4 "Aufpruefen_SWAABAHeck" 5 "Demolauf" ;
VAL_ 588 SWA_LED_Ausgabemodus_FS 0 "LED_aus" 1 "Infostufe" 2 "Warnstufe" 3 "Aufpruefen_SWAABAHeck_ASW" 4 "Aufpruefen_SWAABAHeck" 5 "Demolauf" ;
VAL_ 588 SWA_Status 0 "aus" 1 "passiv" 2 "aktiv" 3 "Fehler" ;
VAL_ 588 ASW_Ton_Richtung_VL 0 "kein_Warnton" 1 "Warnton" ;
VAL_ 588 ASW_Ton_Richtung_VR 0 "kein_Warnton" 1 "Warnton" ;
VAL_ 588 ASW_Ton_Richtung_HL 0 "kein_Warnton" 1 "Warnton" ;
VAL_ 588 ASW_Ton_Richtung_HR 0 "kein_Warnton" 1 "Warnton" ;
VAL_ 588 SWA_Status_System 0 "aus" 1 "passiv" 2 "aktiv" 3 "Fehler" ;
VAL_ 588 SWA_Brightness_Mode_FPM 0 "Init" 1 "No_error" 2 "Trailer_active" 3 "Muted_by_driver" 4 "Blind" 5 "not_selectable" 6 "not_available" 7 "Privacy_Mode" 8 "No_License" 9 "License_expired" 14 "Temporary_error" 15 "Fehler" ;
VAL_ 588 SWA_Status_KuFu 0 "aus" 1 "passiv" 2 "aktiv" 3 "Fehler" ;
VAL_ 588 SWA_Infostufe_Assist_li 0 "keine_Infostufe" 1 "Infostufe_aktiv" ;
VAL_ 588 SWA_Infostufe_Assist_re 0 "keine_Infostufe" 1 "Infostufe_aktiv" ;
VAL_ 588 SWA_Warnstufe_Assist_li 0 "keine_Warnstufe" 1 "Warnstufe_aktiv" ;
VAL_ 588 SWA_Warnstufe_Assist_re 0 "keine_Warnstufe" 1 "Warnstufe_aktiv" ;
VAL_ 588 SWA_Modus_System 0 "nicht_verfuegbar" 1 "verfuegbar" 2 "Anhaengerbetrieb" 3 "eingeschraenkte_Sensorsicht" 4 "keine_Sensorsicht" 5 "reserved" 6 "temporaerer_Fehler" 7 "dauerhafter_Fehler" ;
VAL_ 588 SWA_Kombiausgabe 0 "Keine_Anzeige" 1 "zur_Zeit_nicht_verfuegbar" 2 "Systemfehler" 3 "Sensor_blockiert" 4 "Anhaengerbetrb_nicht_verfuegbar" 5 "Sensor_teilweise_blockiert" ;
VAL_ 588 ASW_Kombiausgabe 0 "Keine_Anzeige" 1 "zur_Zeit_nicht_verfuegbar" 2 "Systemfehler" 3 "Sensor_blockiert" 4 "Anhaengerbetrb_nicht_verfuegbar" ;
VAL_ 588 SWA_Kombiwarnung 0 "Keine_Warnung" 1 "Akustik_Warnung" ;
VAL_ 588 ASW_Ausgabemodus_HBFS 0 "keine_Ausgabe" 1 "Infostufe" 2 "Infostufe_ohne_Tueraktion" 3 "Warnstufe_ohne_Ton" 4 "Warnstufe_mit_Ton" 5 "Aufpruefen" ;
VAL_ 588 ASW_Ausgabemodus_HFS 0 "keine_Ausgabe" 1 "Infostufe" 2 "Infostufe_ohne_Tueraktion" 3 "Warnstufe_ohne_Ton" 4 "Warnstufe_mit_Ton" 5 "Aufpruefen" ;
VAL_ 588 ASW_Akustik_Einstellung 0 "Aus" 1 "Ein" ;
VAL_ 588 SWA_Anzeigen 0 "keine_Anzeige" 1 "Text_1_SWA_zurzeit_nicht_verfuegbar" 2 "Text_2_SWA_Systemstoerung" 3 "Text_3_SWA_zurzeit_nicht_verfuegbar_Keine_Sensorsicht" 4 "Text_4_SWA_zurzeit_nicht_verfuegbar_Anhaengerbetrieb" 5 "Text_5_SWA_Eskalation" 6 "Text_6_SWA_eingeschränkt" ;
VAL_ 588 SWA_Blindheit_erkannt 0 "nicht erkannt" 1 "erkannt" ;
VAL_ 588 SWA_rel_Nichtverf 0 "verfuegbar" 1 "nicht verfuegbar" ;
VAL_ 588 SWA_rel_Fehler 0 "kein Fehler" 1 "Fehler" ;
VAL_ 588 SWA_Sta_aktiv 0 "Aus" 1 "Ein" ;
VAL_ 588 SWA_Sta_passiv 0 "Aus" 1 "Ein" ;
VAL_ 588 SWA_FT_RueckLED 0 "inaktiv" 1 "aktiv" ;
VAL_ 588 ASW_Status 0 "Passiv" 1 "Aktiv" 2 "Fehler" 3 "AUS" ;
VAL_ 588 SWA_Standziele_li 0 "Abstand i.O." 1 "Abstand zu gering" ;
VAL_ 588 ASW_Ausgabemodus_BFS 0 "keine_Ausgabe" 1 "Infostufe" 2 "Infostufe_ohne_Tueraktion" 3 "Warnstufe_ohne_Ton" 4 "Warnstufe_mit_Ton" 5 "Aufpruefen" ;
VAL_ 588 ASW_Warnung_FS 0 "inaktiv" 1 "aktiv" ;
VAL_ 588 ASW_Warnung_BFS 0 "inaktiv" 1 "aktiv" ;
VAL_ 588 ASW_Kombitexte 0 "keine Anzeige.    //    Prio 5" 1 "Text_1_ASW_zur_Zeit_nicht_verfuegbar_und_Akustik    //    Prio 2" 2 "Text_2_ASW_Systemfehler_und_Akustik    //    Prio 1" 3 "Text_3_ASW_Sensor_blockiert_und_Akustik    //    Prio 3" 4 "Text_4_ASW_im_Anhaengerbetrieb_nicht_verfuegbar_und_Akustik    //    Prio 4" 5 "Text_5_ASW_Warnung_FS_und_Akustik" 6 "Text_6_ASW_Warnung_BFS_und_Akustik" 7 "Text_7_ASW_aus" ;
VAL_ 588 ASW_Modus 0 "kein_Fehler_KL15" 1 "kein_Fehler_KL30" 2 "reserve" 3 "Anhaengerbetrieb" 4 "Init_nicht_codiert" 5 "keine_Sensorsicht_blindheit" 6 "Zur_zeit_nicht_verfuegbar_temp_Fehler" 7 "Systemstoerung_dauer_fehler" ;
VAL_ 588 SWA_Modus 0 "kein_Fehler_verfuegbar" 1 "kein_Fehler_eingeschr_Reichweite" 2 "reserve" 3 "Anhaengerbetrieb" 4 "Init_nicht_codiert" 5 "keine_Sensorsicht_blindheit" 6 "Zur_zeit_nicht_verfuegbar_temp_Fehler" 7 "Systemstoerung_dauer_fehler" ;
VAL_ 588 SWA_Standziele_re 0 "Abstand i.O." 1 "Abstand zu gering" ;
VAL_ 588 ASW_Ausgabemodus_FS 0 "keine_Ausgabe" 1 "Infostufe" 2 "Infostufe_ohne_Tueraktion" 3 "Warnstufe_ohne_Ton" 4 "Warnstufe_mit_Ton" 5 "Aufpruefen" ;
VAL_ 588 HRE_Anzeigetexte 0 "keine_Anzeige" 1 "BSD_RTA_zZt_nicht_verfuegbar" 2 "BSD_RTA_Systemfehler" 3 "BSD_RTA_Sensor_blockiert" 4 "BSD_RTA_Anhaengerbetrieb" 5 "RTA_Warnung" 6 "BSD_Warnung" 7 "Fahreruebernahme_Notbremsung" 8 "RTA_nicht_verfuegbar" 9 "BSD_RTA_ASW_zZt_nicht_verfuegbar" 10 "BSD_RTA_ASW_Systemfehler" 11 "BSD_RTA_ASW_Sensor_blockiert" 12 "BSD_RTA_ASW_Anhaengerbetrieb" ;
VAL_ 588 SWA_Blindheitsverdacht 0 "kein_Blindheitsverdacht_erkannt" 1 "Blindheitsverdacht_erkannt" ;
VAL_ 588 Heckradar_Kombitexte 0 "keine Anzeige.    //    Prio 5" 1 "Text_1_SWA_und_ASW_zur_Zeit_nicht_verfuegbar_und_Akustik    //    Prio 2" 2 "Text_2_SWA_und_ASW_Systemfehler_und_Akustik    //    Prio 1" 3 "Text_3_SWA_und_ASW_Sensor_blockiert_und_Akustik    //    Prio 3" 4 "Text_4_SWA_und_ASW_im_Anhaengerbetrieb_nicht_verfuegbar_und_Akustik    //    Prio 4" 5 "Text_1_SWA_und_RCTA_zur_Zeit_nicht_verfuegbar_und_Akustik // Prio 2" 6 "Text_2_SWA_und_RCTA_Systemfehler_und_Akustik // Prio 1" 7 "		Text_3_SWA_und_RCTA_Sensor_blockiert_und_Akustik // Prio 3" 8 "Text_4_SWA_und_RCTA_im_Anhaengerbetrieb_nicht_verfuegbar_und_Akustik // Prio 4" 9 "Text_1_ASW_und_RCTA_zur_Zeit_nicht_verfuegbar_und_Akustik // Prio 2" 10 "Text_2_ASW_und_RCTA_Systemfehler_und_Akustik // Prio 1" 11 "Text_3_ASW_und_RCTA_Sensor_blockiert_und_Akustik // Prio 3" 12 "Text_4_ASW_und_RCTA_im_Anhaengerbetrieb_nicht_verfuegbar_und_Akustik // Prio 4" 13 "Text_1_SWA_und_ASW_und_RCTA_zur_Zeit_nicht_verfuegbar_und_Akustik // Prio 2" 14 "Text_2_SWA_und_ASW_und_RCTA_Systemfehler_und_Akustik // Prio 1" 15 "Text_3_SWA_und_ASW_und_RCTA_Sensor_blockiert_und_Akustik // Prio 3" 16 "Text_4_SWA_und_ASW_und_RCTA_im_Anhaengerbetrieb_nicht_verfuegbar_und_Akustik // Prio 4" 17 "reserviert" 18 "reserviert" 19 "reserviert" 20 "reserviert" 21 "reserviert" 22 "reserviert" 23 "reserviert" 24 "reserviert" 25 "reserviert" 26 "reserviert" 27 "reserviert" 28 "reserviert" 29 "reserviert" ;
VAL_ 588 RCTA_Kombitexte 0 "keine_Anzeige" 1 "RCTA_zur_Zeit_nicht_verfuegbar" 2 "RCTA_Systemfehler" 3 "RCTA_Sensor_blockiert" 4 "RCTA_im_Anhaengerbetrieb" 5 "RTA_Warnung" 6 "Fahreruebernahme_Notbremsung" 7 "Eingeschraenkt_verfuegbar_ESCaus" ;
VAL_ 1016 HLR_FlHz_Freigabe_Ruhesitz 0 "0_Prozent" 1 "33_Prozent" 2 "66_Prozent" 3 "100_Prozent" ;
VAL_ 1016 HLR_FlHz_Freigabe_VR 0 "0_Prozent" 1 "33_Prozent" 2 "66_Prozent" 3 "100_Prozent" ;
VAL_ 1016 HLR_FlHz_Freigabe_VL 0 "0_Prozent" 1 "33_Prozent" 2 "66_Prozent" 3 "100_Prozent" ;
VAL_ 1016 HLR_FlHz_Freigabe_HR 0 "0_Prozent" 1 "33_Prozent" 2 "66_Prozent" 3 "100_Prozent" ;
VAL_ 1016 HLR_FlHz_Freigabe_HL 0 "0_Prozent" 1 "33_Prozent" 2 "66_Prozent" 3 "100_Prozent" ;
VAL_ 1016 HLR_TCH_Freigabe 0 "keine_Freigabe" 1 "Freigabe" ;
VAL_ 1016 HLR_SIH_Freigabe_Fond 0 "keine_Freigabe" 1 "Freigabe" ;
VAL_ 1016 HLR_Sp_Heizung_Freigabe_BT 0 "keine_Freigabe" 1 "Freigabe" ;
VAL_ 1016 HLR_Sp_Heizung_Freigabe_FT 0 "keine_Freigabe" 1 "Freigabe" ;
VAL_ 1016 HLR_KRH_Freigabe_VL 0 "0_Prozent" 1 "33_Prozent" 2 "66_Prozent" 3 "100_Prozent" ;
VAL_ 1016 HLR_KRH_Freigabe_VR 0 "0_Prozent" 1 "33_Prozent" 2 "66_Prozent" 3 "100_Prozent" ;
VAL_ 1016 HLR_SIH_Freigabe_VL 0 "0_Prozent" 1 "33_Prozent" 2 "66_Prozent" 3 "100_Prozent" ;
VAL_ 1016 HLR_SIH_Freigabe_VR 0 "0_Prozent" 1 "33_Prozent" 2 "66_Prozent" 3 "100_Prozent" ;
VAL_ 1016 HLR_SIH_Freigabe_HL 0 "0_Prozent" 1 "33_Prozent" 2 "66_Prozent" 3 "100_Prozent" ;
VAL_ 1016 HLR_SIH_Freigabe_HR 0 "0_Prozent" 1 "33_Prozent" 2 "66_Prozent" 3 "100_Prozent" ;
VAL_ 1016 HLR_SIL_Freigabe_VL 0 "0_Prozent" 1 "33_Prozent" 2 "66_Prozent" 3 "100_Prozent" ;
VAL_ 1016 HLR_SIL_Freigabe_VR 0 "0_Prozent" 1 "33_Prozent" 2 "66_Prozent" 3 "100_Prozent" ;
VAL_ 1016 HLR_SIL_Freigabe_HL 0 "0_Prozent" 1 "33_Prozent" 2 "66_Prozent" 3 "100_Prozent" ;
VAL_ 1016 HLR_SIL_Freigabe_HR 0 "0_Prozent" 1 "33_Prozent" 2 "66_Prozent" 3 "100_Prozent" ;
VAL_ 1016 HLR_FSH_Freigabe 0 "AUS" 63 "Fehler" ;
VAL_ 1016 HLR_HSH_Freigabe 0 "keine_Freigabe" 1 "Freigabe" ;
VAL_ 1016 HLR_LRH_Freigabe 0 "keine_Freigabe" 1 "Freigabe" ;
VAL_ 1016 HLR_PTC_linear_Freigabe 63 "Fehler" ;
VAL_ 1016 HLR_PTC_Freigabe 0 "Aus" 1 "Stufe_1" 2 "Stufe_2" 3 "Stufe_3" ;
VAL_ 2527679731 IL_TSG_BFS_Dimmzeit_Basis_1 0 "Zeitbasis_50ms" 1 "Zeitbasis_250ms" ;
VAL_ 2527679731 IL_TSG_BFS_Dimmzeit_Basis_2 0 "Zeitbasis_50ms" 1 "Zeitbasis_250ms" ;
VAL_ 2527679731 IL_TSG_BFS_Dimmzeit_Basis_3 0 "Zeitbasis_50ms" 1 "Zeitbasis_250ms" ;
VAL_ 2527679731 IL_TSG_BFS_Dimmzeit_Basis_4 0 "Zeitbasis_50ms" 1 "Zeitbasis_250ms" ;
VAL_ 2527679730 IL_TSG_FS_Dimmzeit_Basis_1 0 "Zeitbasis_50ms" 1 "Zeitbasis_250ms" ;
VAL_ 2527679730 IL_TSG_FS_Dimmzeit_Basis_2 0 "Zeitbasis_50ms" 1 "Zeitbasis_250ms" ;
VAL_ 2527679730 IL_TSG_FS_Dimmzeit_Basis_3 0 "Zeitbasis_50ms" 1 "Zeitbasis_250ms" ;
VAL_ 2527679730 IL_TSG_FS_Dimmzeit_Basis_4 0 "Zeitbasis_50ms" 1 "Zeitbasis_250ms" ;
VAL_ 2527679732 IL_TSG_HBFS_Dimmzeit_Basis_1 0 "Zeitbasis_50ms" 1 "Zeitbasis_250ms" ;
VAL_ 2527679732 IL_TSG_HBFS_Dimmzeit_Basis_2 0 "Zeitbasis_50ms" 1 "Zeitbasis_250ms" ;
VAL_ 2527679732 IL_TSG_HBFS_Dimmzeit_Basis_3 0 "Zeitbasis_50ms" 1 "Zeitbasis_250ms" ;
VAL_ 2527679732 IL_TSG_HBFS_Dimmzeit_Basis_4 0 "Zeitbasis_50ms" 1 "Zeitbasis_250ms" ;
VAL_ 2527679733 IL_TSG_HFS_Dimmzeit_Basis_1 0 "Zeitbasis_50ms" 1 "Zeitbasis_250ms" ;
VAL_ 2527679733 IL_TSG_HFS_Dimmzeit_Basis_2 0 "Zeitbasis_50ms" 1 "Zeitbasis_250ms" ;
VAL_ 2527679733 IL_TSG_HFS_Dimmzeit_Basis_3 0 "Zeitbasis_50ms" 1 "Zeitbasis_250ms" ;
VAL_ 2527679733 IL_TSG_HFS_Dimmzeit_Basis_4 0 "Zeitbasis_50ms" 1 "Zeitbasis_250ms" ;
VAL_ 27 WFS_IMMO_ELV_RND 0 "Init" ;
VAL_ 19 WFS_IMMO_GSG_Data_0 0 "Init" ;
VAL_ 19 WFS_IMMO_GSG_Data_1 0 "Init" ;
VAL_ 19 WFS_IMMO_GSG_Data_2 0 "Init" ;
VAL_ 17 WFS_IMMO_MSG1_Data_0 0 "Init" ;
VAL_ 17 WFS_IMMO_MSG1_Data_1 0 "Init" ;
VAL_ 17 WFS_IMMO_MSG1_Data_2 0 "Init" ;
VAL_ 23 WFS_IMMO_MSG3_Data_0 0 "Init" ;
VAL_ 23 WFS_IMMO_MSG3_Data_1 0 "Init" ;
VAL_ 23 WFS_IMMO_MSG3_Data_2 0 "Init" ;
VAL_ 25 WFS_IMMO_MSG4_Data_0 0 "Init" ;
VAL_ 25 WFS_IMMO_MSG4_Data_1 0 "Init" ;
VAL_ 25 WFS_IMMO_MSG4_Data_2 0 "Init" ;
VAL_ 29 WFS_IMMO_OCU_CRC 0 "Init" ;
VAL_ 29 WFS_IMMO_OCU_RND 0 "Init" ;
